VERSION "HNNBNNNYNNNNNNNNNNNNNNNNNNNNNNNNNNNNNNNNNN/4/%%%/4/'%**4NNN///"

NS_ :

BS_:

BU_: ADR_PAG_X2 BAP_Tester GW_App_PAG_PF GW_Routing_PAG_PF Klima_PAG_PF Klimakomp_Dash_PAG_PF Kombi_PAG_PF Miko_PAG_X2 OCU_PAG_PF RDK_High_PAG_PF

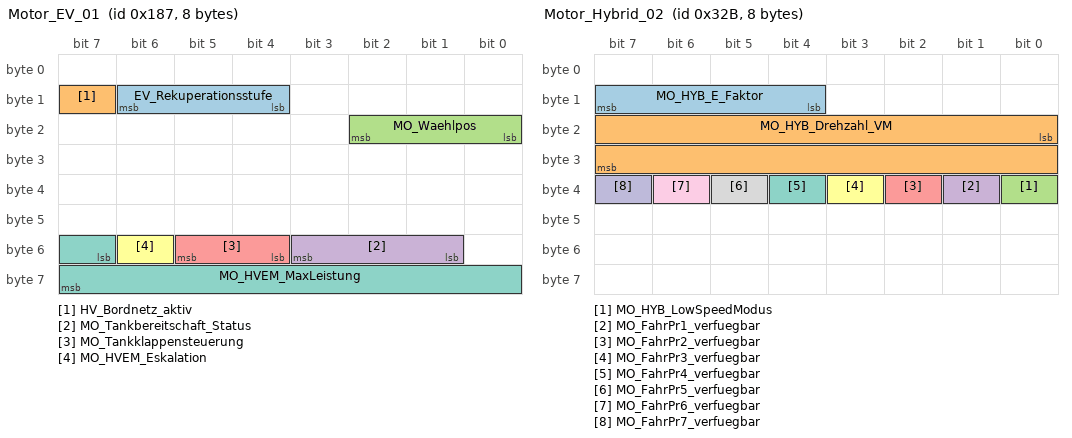
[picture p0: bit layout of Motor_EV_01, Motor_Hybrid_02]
BO_ 391 Motor_EV_01: 8 GW_Routing_PAG_PF
 SG_ EV_Rekuperationsstufe : 12|3@1+ (1,0) [0|7] "" Vector__XXX
 SG_ HV_Bordnetz_aktiv : 15|1@1+ (1,0) [0|1] "" Vector__XXX
 SG_ MO_Waehlpos : 16|3@1+ (1,0) [0|7] "" Vector__XXX
 SG_ MO_Tankbereitschaft_Status : 49|3@1+ (1,0) [0|7] ""  Kombi_PAG_PF
 SG_ MO_Tankklappensteuerung : 52|2@1+ (1,0) [0|3] "" Vector__XXX
 SG_ MO_HVEM_Eskalation : 54|1@1+ (1,0) [0|1] "" Vector__XXX
 SG_ MO_HVEM_MaxLeistung : 55|9@1+ (50,0) [0|25450] "Unit_Watt" Vector__XXX

BO_ 811 Motor_Hybrid_02: 8 GW_Routing_PAG_PF
 SG_ MO_HYB_E_Faktor : 12|4@1+ (1,0) [0|15] "" Vector__XXX
 SG_ MO_HYB_Drehzahl_VM : 16|16@1+ (0.25,0) [0|16256] "Unit_MinutInver" Vector__XXX
 SG_ MO_HYB_LowSpeedModus : 32|1@1+ (1,0) [0|1] "" Vector__XXX
 SG_ MO_FahrPr1_verfuegbar : 33|1@1+ (1,0) [0|1] ""  Klima_PAG_PF
 SG_ MO_FahrPr2_verfuegbar : 34|1@1+ (1,0) [0|1] ""  Klima_PAG_PF
 SG_ MO_FahrPr3_verfuegbar : 35|1@1+ (1,0) [0|1] ""  Klima_PAG_PF
 SG_ MO_FahrPr4_verfuegbar : 36|1@1+ (1,0) [0|1] ""  Klima_PAG_PF
 SG_ MO_FahrPr5_verfuegbar : 37|1@1+ (1,0) [0|1] ""  Klima_PAG_PF
 SG_ MO_FahrPr6_verfuegbar : 38|1@1+ (1,0) [0|1] ""  Klima_PAG_PF
 SG_ MO_FahrPr7_verfuegbar : 39|1@1+ (1,0) [0|1] ""  Klima_PAG_PF

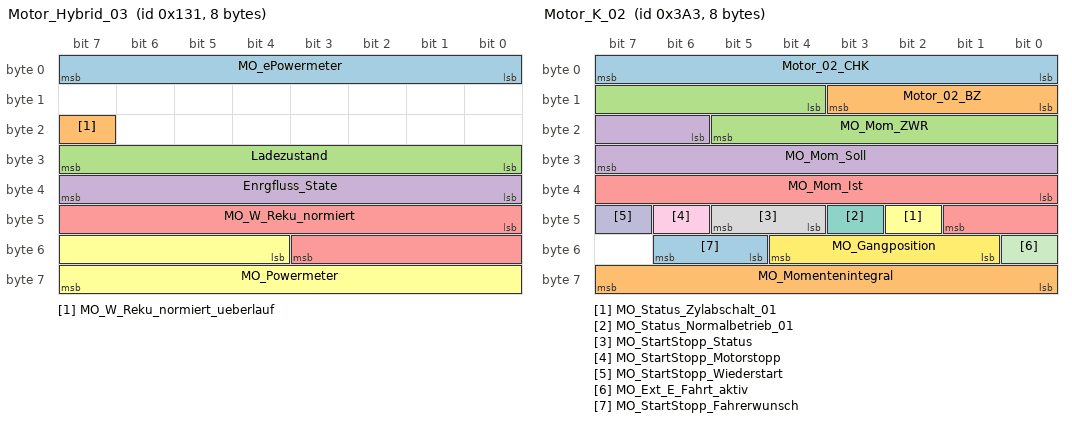
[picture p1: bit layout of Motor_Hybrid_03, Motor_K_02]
BO_ 305 Motor_Hybrid_03: 8 GW_Routing_PAG_PF
 SG_ MO_ePowermeter : 0|8@1+ (0.4,-0.4) [0|100.8] "Unit_PerCent" Vector__XXX
 SG_ MO_W_Reku_normiert_ueberlauf : 23|1@1+ (1,0) [0|1] "" Vector__XXX
 SG_ Ladezustand : 24|8@1+ (1,0) [0|100] "Unit_PerCent"  OCU_PAG_PF
 SG_ Enrgfluss_State : 32|8@1+ (1,0) [0|255] "" Vector__XXX
 SG_ MO_W_Reku_normiert : 40|12@1+ (10,0) [0|40950] "Unit_WattSecond" Vector__XXX
 SG_ MO_Powermeter : 52|12@1+ (1,0) [0|4092] ""  Kombi_PAG_PF

BO_ 931 Motor_K_02: 8 GW_Routing_PAG_PF
 SG_ Motor_02_CHK : 0|8@1+ (1,0) [0|255] "" Vector__XXX
 SG_ Motor_02_BZ : 8|4@1+ (1,0) [0|15] "" Vector__XXX
 SG_ MO_Mom_ZWR : 12|10@1+ (1,0) [0|1021] "" Vector__XXX
 SG_ MO_Mom_Soll : 22|10@1+ (1,0) [0|1021] "" Vector__XXX
 SG_ MO_Mom_Ist : 32|10@1+ (1,0) [0|1021] "" Vector__XXX
 SG_ MO_Status_Zylabschalt_01 : 42|1@1+ (1,0) [0|1] "" Vector__XXX
 SG_ MO_Status_Normalbetrieb_01 : 43|1@1+ (1,0) [0|1] "" Vector__XXX
 SG_ MO_StartStopp_Status : 44|2@1+ (1,0) [0|3] ""  Klima_PAG_PF,Kombi_PAG_PF
 SG_ MO_StartStopp_Motorstopp : 46|1@1+ (1,0) [0|1] ""  ADR_PAG_X2,Klima_PAG_PF,Kombi_PAG_PF
 SG_ MO_StartStopp_Wiederstart : 47|1@1+ (1,0) [0|1] ""  Klima_PAG_PF
 SG_ MO_Ext_E_Fahrt_aktiv : 48|1@1+ (1,0) [0|1] ""  Klima_PAG_PF
 SG_ MO_Gangposition : 49|4@1+ (1,0) [0|15] "" Vector__XXX
 SG_ MO_StartStopp_Fahrerwunsch : 53|2@1+ (1,0) [0|3] "" Vector__XXX
 SG_ MO_Momentenintegral : 56|8@1+ (0.3921,0) [0|99.9855] "" Vector__XXX

BO_ 1747 NMH_CDR_PCM: 7 ADR_PAG_X2
 SG_ NM_CDR_PCM_Start_1 : 0|1@1+ (1,0) [0|1] ""  ADR_PAG_X2,GW_App_PAG_PF,Klima_PAG_PF,Kombi_PAG_PF,Miko_PAG_X2,OCU_PAG_PF,RDK_High_PAG_PF
 SG_ NM_CDR_PCM_Start_2 : 1|1@1+ (1,0) [0|1] "" Vector__XXX
 SG_ NM_CDR_PCM_Normal_Mode_1 : 2|1@1+ (1,0) [0|1] "" Vector__XXX
 SG_ NM_CDR_PCM_Normal_Mode_2 : 3|1@1+ (1,0) [0|1] "" Vector__XXX
 SG_ NM_CDR_PCM_Car_WakeUp : 6|1@1+ (1,0) [0|1] "" Vector__XXX
 SG_ NM_CDR_PCM_Per_WakeUp : 8|5@1+ (1,0) [0|31] "" Vector__XXX
 SG_ NM_CDR_PCM_Fkt_WakeUp : 13|3@1+ (1,0) [0|7] "" Vector__XXX
 SG_ NM_CDR_PCM_Klemme_15 : 16|1@1+ (1,0) [0|1] "" Vector__XXX
 SG_ NM_CDR_PCM_Diagnose : 17|1@1+ (1,0) [0|1] "" Vector__XXX
 SG_ NM_CDR_PCM_MindestAktivZeit : 18|1@1+ (1,0) [0|1] "" Vector__XXX
 SG_ NMH_CDR_PCM_Signalfehler : 32|1@1+ (1,0) [0|1] "" Vector__XXX
 SG_ NM_CDR_PCM_TimeOut_Fehler : 33|1@1+ (1,0) [0|1] "" Vector__XXX
 SG_ NM_CDR_PCM_CAN_Diag_deaktiv : 34|1@1+ (1,0) [0|1] "" Vector__XXX
 SG_ NM_CDR_PCM_KompSchutz : 35|1@1+ (1,0) [0|1] "" Vector__XXX
 SG_ NM_CDR_PCM_Mute_Mode : 36|1@1+ (1,0) [0|1] "" Vector__XXX
 SG_ NM_CDR_PCM_Transport_Mode : 37|1@1+ (1,0) [0|1] "" Vector__XXX
 SG_ NM_CDR_PCM_Abschaltstufe_aktiv : 38|1@1+ (1,0) [0|1] "" Vector__XXX
 SG_ NM_CDR_PCM_Busfehler : 39|1@1+ (1,0) [0|1] "" Vector__XXX
 SG_ NMH_CDR_PCM_Lokalaktiv : 48|1@1+ (1,0) [0|1] "" Vector__XXX
 SG_ NMH_CDR_PCM_Subsystemaktiv : 49|1@1+ (1,0) [0|1] "" Vector__XXX

BO_ 1728 NMH_Gateway: 7 GW_App_PAG_PF
 SG_ NMH_GW_Start_1 : 0|1@1+ (1,0) [0|1] ""  ADR_PAG_X2,GW_App_PAG_PF,Klima_PAG_PF,Kombi_PAG_PF,Miko_PAG_X2,OCU_PAG_PF,RDK_High_PAG_PF
 SG_ NMH_GW_Start_2 : 1|1@1+ (1,0) [0|1] "" Vector__XXX
 SG_ NMH_GW_Normal_Mode_1 : 2|1@1+ (1,0) [0|1] "" Vector__XXX
 SG_ NMH_GW_Normal_Mode_2 : 3|1@1+ (1,0) [0|1] "" Vector__XXX
 SG_ NMH_GW_Car_WakeUp : 6|1@1+ (1,0) [0|1] "" Vector__XXX
 SG_ NMH_GW_Per_WakeUp : 8|5@1+ (1,0) [0|31] "" Vector__XXX
 SG_ NMH_GW_Fkt_WakeUp : 13|3@1+ (1,0) [0|7] "" Vector__XXX
 SG_ NMH_GW_NM_aktiv_Klemme_15 : 16|1@1+ (1,0) [0|1] "" Vector__XXX
 SG_ NMH_GW_NM_aktiv_Diagnose : 17|1@1+ (1,0) [0|1] "" Vector__XXX
 SG_ NMH_GW_NM_aktiv_Start : 18|1@1+ (1,0) [0|1] "" Vector__XXX
 SG_ NMH_GW_NM_aktiv_BDM : 19|1@1+ (1,0) [0|1] "" Vector__XXX
 SG_ NMH_GW_NM_aktiv_Warnblinken : 20|1@1+ (1,0) [0|1] "" Vector__XXX
 SG_ NMH_GW_NM_aktiv_ESP : 21|1@1+ (1,0) [0|1] "" Vector__XXX
 SG_ NMH_GW_NM_aktiv_EMP : 22|1@1+ (1,0) [0|1] "" Vector__XXX
 SG_ NMH_GW_Abschaltstufe_3 : 24|1@1+ (1,0) [0|1] "" Vector__XXX
 SG_ NMH_GW_SG_Fehlerdauer : 25|1@1+ (1,0) [0|1] "" Vector__XXX
 SG_ NMH_GW_STH_Wakeup : 26|1@1+ (1,0) [0|1] "" Vector__XXX
 SG_ NMH_GW_NL_Diagnose : 27|1@1+ (1,0) [0|1] "" Vector__XXX
 SG_ NM_GW_Signalfehler : 32|1@1+ (1,0) [0|1] "" Vector__XXX
 SG_ NMH_GW_TimeOut_Fehler : 33|1@1+ (1,0) [0|1] "" Vector__XXX
 SG_ NMH_GW_CAN_Diag_deaktiv : 34|1@1+ (1,0) [0|1] "" Vector__XXX
 SG_ NMH_GW_KompSchutz : 35|1@1+ (1,0) [0|1] "" Vector__XXX
 SG_ NMH_GW_Mute_Mode : 36|1@1+ (1,0) [0|1] "" Vector__XXX
 SG_ NMH_GW_Transport_Mode : 37|1@1+ (1,0) [0|1] "" Vector__XXX
 SG_ NMH_GW_Abschaltstufe_aktiv : 38|1@1+ (1,0) [0|1] "" Vector__XXX
 SG_ NMH_GW_Eindraht_Fehler : 39|1@1+ (1,0) [0|1] "" Vector__XXX
 SG_ NMH_GW_ACAN : 40|1@1+ (1,0) [0|1] "" Vector__XXX
 SG_ NMH_GW_KombiCAN : 41|1@1+ (1,0) [0|1] "" Vector__XXX
 SG_ NMH_GW_KomfortCAN : 42|1@1+ (1,0) [0|1] "" Vector__XXX
 SG_ NMH_GW_Infotainment : 43|1@1+ (1,0) [0|1] "" Vector__XXX
 SG_ NMH_GW_Fahrwerk : 44|1@1+ (1,0) [0|1] "" Vector__XXX
 SG_ NMH_GW_WakeUp_CAN_Bus : 45|3@1+ (1,0) [0|7] "" Vector__XXX

BO_ 1775 NMH_GSM: 7 OCU_PAG_PF
 SG_ NMH_GSM_Start_1 : 0|1@1+ (1,0) [0|1] ""  ADR_PAG_X2,GW_App_PAG_PF,Klima_PAG_PF,Kombi_PAG_PF,Miko_PAG_X2,OCU_PAG_PF,RDK_High_PAG_PF
 SG_ NMH_GSM_Start_2 : 1|1@1+ (1,0) [0|1] "" Vector__XXX
 SG_ NMH_GSM_Normal_Mode_1 : 2|1@1+ (1,0) [0|1] "" Vector__XXX
 SG_ NMH_GSM_Normal_Mode_2 : 3|1@1+ (1,0) [0|1] "" Vector__XXX
 SG_ NMH_GSM_Car_WakeUp : 6|1@1+ (1,0) [0|1] "" Vector__XXX
 SG_ NMH_GSM_Per_WakeUp : 8|5@1+ (1,0) [0|31] "" Vector__XXX
 SG_ NMH_GSM_Fkt_WakeUp : 13|3@1+ (1,0) [0|7] "" Vector__XXX
 SG_ NMH_GSM_Klemme_15 : 16|1@1+ (1,0) [0|1] "" Vector__XXX
 SG_ NMH_GSM_Diagnose : 17|1@1+ (1,0) [0|1] "" Vector__XXX
 SG_ NMH_GSM_MindestAktivZeit : 18|1@1+ (1,0) [0|1] "" Vector__XXX
 SG_ NMH_GSM_Signalfehler : 32|1@1+ (1,0) [0|1] "" Vector__XXX
 SG_ NMH_GSM_TimeOut_Fehler : 33|1@1+ (1,0) [0|1] "" Vector__XXX
 SG_ NMH_GSM_CAN_Diag_deaktiv : 34|1@1+ (1,0) [0|1] "" Vector__XXX
 SG_ NMH_GSM_KompSchutz : 35|1@1+ (1,0) [0|1] "" Vector__XXX
 SG_ NMH_GSM_Mute_Mode : 36|1@1+ (1,0) [0|1] "" Vector__XXX
 SG_ NMH_GSM_Transport_Mode : 37|1@1+ (1,0) [0|1] "" Vector__XXX
 SG_ NMH_GSM_Abschaltstufe_aktiv : 38|1@1+ (1,0) [0|1] "" Vector__XXX
 SG_ NMH_GSM_Eindraht_Fehler : 39|1@1+ (1,0) [0|1] "" Vector__XXX
 SG_ NMH_GSM_Lokalaktiv : 48|1@1+ (1,0) [0|1] "" Vector__XXX
 SG_ NMH_GSM_Subsystemaktiv : 49|1@1+ (1,0) [0|1] "" Vector__XXX

BO_ 1772 NMH_Klima: 7 Klima_PAG_PF
 SG_ NMH_KL_Start_1 : 0|1@1+ (1,0) [0|1] ""  ADR_PAG_X2,GW_App_PAG_PF,Klima_PAG_PF,Kombi_PAG_PF,Miko_PAG_X2,OCU_PAG_PF,RDK_High_PAG_PF
 SG_ NMH_KL_Start_2 : 1|1@1+ (1,0) [0|1] "" Vector__XXX
 SG_ NMH_KL_Normal_Mode_1 : 2|1@1+ (1,0) [0|1] "" Vector__XXX
 SG_ NMH_KL_Normal_Mode_2 : 3|1@1+ (1,0) [0|1] "" Vector__XXX
 SG_ NM_KL_Car_WakeUp : 6|1@1+ (1,0) [0|1] "" Vector__XXX
 SG_ NM_KL_Per_WakeUp : 8|5@1+ (1,0) [0|31] "" Vector__XXX
 SG_ NM_KL_Fkt_WakeUp : 13|3@1+ (1,0) [0|7] "" Vector__XXX
 SG_ NM_KL_Klemme_15 : 16|1@1+ (1,0) [0|1] "" Vector__XXX
 SG_ NM_KL_Diagnose : 17|1@1+ (1,0) [0|1] "" Vector__XXX
 SG_ NM_KL_MindestAktivZeit : 18|1@1+ (1,0) [0|1] "" Vector__XXX
 SG_ NM_KL_FKT_Nachlauf_Klappen : 19|1@1+ (1,0) [0|1] "" Vector__XXX
 SG_ NM_KL_NL_STH : 24|1@1+ (1,0) [0|1] "" Vector__XXX
 SG_ NM_KL_NL_Restwaerme : 25|1@1+ (1,0) [0|1] "" Vector__XXX
 SG_ NM_KL_NL_LIN : 26|1@1+ (1,0) [0|1] "" Vector__XXX
 SG_ NM_Klima_Signalfehler : 32|1@1+ (1,0) [0|1] "" Vector__XXX
 SG_ NM_KL_TimeOut_Fehler : 33|1@1+ (1,0) [0|1] "" Vector__XXX
 SG_ NM_KL_CAN_Diag_deaktiv : 34|1@1+ (1,0) [0|1] "" Vector__XXX
 SG_ NM_KL_KompSchutz : 35|1@1+ (1,0) [0|1] "" Vector__XXX
 SG_ NM_KL_Mute_Mode : 36|1@1+ (1,0) [0|1] "" Vector__XXX
 SG_ NM_KL_Transport_Mode : 37|1@1+ (1,0) [0|1] "" Vector__XXX
 SG_ NM_KL_Abschaltstufe_aktiv : 38|1@1+ (1,0) [0|1] "" Vector__XXX
 SG_ NM_KL_Eindraht_Fehler : 39|1@1+ (1,0) [0|1] "" Vector__XXX
 SG_ NMH_Klima_Lokalaktiv : 48|1@1+ (1,0) [0|1] "" Vector__XXX
 SG_ NMH_Klima_Subsystemaktiv : 49|1@1+ (1,0) [0|1] "" Vector__XXX

BO_ 1735 NMH_Kombi: 7 Kombi_PAG_PF
 SG_ NMH_KBI_Start_1 : 0|1@1+ (1,0) [0|1] ""  ADR_PAG_X2,GW_App_PAG_PF,Klima_PAG_PF,Kombi_PAG_PF,Miko_PAG_X2,OCU_PAG_PF,RDK_High_PAG_PF
 SG_ NMH_KBI_Start_2 : 1|1@1+ (1,0) [0|1] "" Vector__XXX
 SG_ NMH_KBI_Normal_Mode_1 : 2|1@1+ (1,0) [0|1] "" Vector__XXX
 SG_ NMH_KBI_Normal_Mode_2 : 3|1@1+ (1,0) [0|1] "" Vector__XXX
 SG_ NMH_KBI_Car_WakeUp : 6|1@1+ (1,0) [0|1] "" Vector__XXX
 SG_ NMH_KBI_Per_WakeUp : 8|5@1+ (1,0) [0|31] "" Vector__XXX
 SG_ NMH_KBI_Fkt_WakeUp : 13|3@1+ (1,0) [0|7] "" Vector__XXX
 SG_ NMH_KBI_NM_aktiv_Klemme_15 : 16|1@1+ (1,0) [0|1] "" Vector__XXX
 SG_ NMH_KBI_NM_aktiv_Diagnose : 17|1@1+ (1,0) [0|1] "" Vector__XXX
 SG_ NMH_KBI_NM_aktiv_Start : 18|1@1+ (1,0) [0|1] "" Vector__XXX
 SG_ NMH_KBI_NM_aktiv_Tankinhalt : 19|1@1+ (1,0) [0|1] "" Vector__XXX
 SG_ NMH_KBI_NM_aktiv_Display : 20|1@1+ (1,0) [0|1] "" Vector__XXX
 SG_ NMH_KBI_kein_NL : 24|1@1+ (1,0) [0|1] "" Vector__XXX
 SG_ NMH_KBI_NL_Sync_Funkuhr : 25|1@1+ (1,0) [0|1] "" Vector__XXX
 SG_ NM_Kombi_NL_Warnblinken : 26|1@1+ (1,0) [0|1] "" Vector__XXX
 SG_ NMH_KBI_NL_KL15 : 27|1@1+ (1,0) [0|1] "" Vector__XXX
 SG_ NMH_KBI_Signalfehler : 32|1@1+ (1,0) [0|1] "" Vector__XXX
 SG_ NMH_KBI_TimeOut_Fehler : 33|1@1+ (1,0) [0|1] "" Vector__XXX
 SG_ NMH_KBI_CAN_Diag_deaktiv : 34|1@1+ (1,0) [0|1] "" Vector__XXX
 SG_ NMH_KBI_KompSchutz : 35|1@1+ (1,0) [0|1] "" Vector__XXX
 SG_ NMH_KBI_Mute_Mode : 36|1@1+ (1,0) [0|1] "" Vector__XXX
 SG_ NMH_KBI_Transport_Mode : 37|1@1+ (1,0) [0|1] "" Vector__XXX
 SG_ NMH_KBI_Abschaltstufe_aktiv : 38|1@1+ (1,0) [0|1] "" Vector__XXX
 SG_ NMH_KBI_Eindraht_Fehler : 39|1@1+ (1,0) [0|1] "" Vector__XXX
 SG_ NMH_Kombi_Lokalaktiv : 48|1@1+ (1,0) [0|1] "" Vector__XXX
 SG_ NMH_Kombi_Subsystemaktiv : 49|1@1+ (1,0) [0|1] "" Vector__XXX

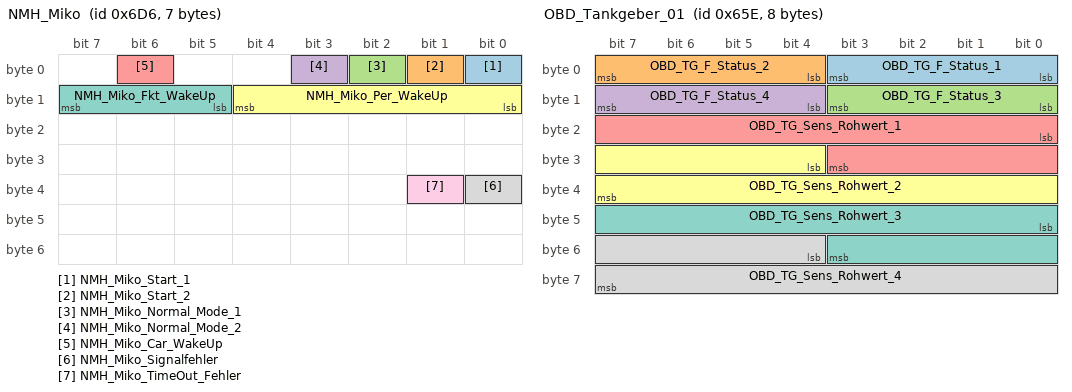
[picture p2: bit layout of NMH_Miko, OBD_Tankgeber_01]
BO_ 1750 NMH_Miko: 7 Miko_PAG_X2
 SG_ NMH_Miko_Start_1 : 0|1@1+ (1,0) [0|1] ""  ADR_PAG_X2,GW_App_PAG_PF,Klima_PAG_PF,Kombi_PAG_PF,Miko_PAG_X2,OCU_PAG_PF,RDK_High_PAG_PF
 SG_ NMH_Miko_Start_2 : 1|1@1+ (1,0) [0|1] "" Vector__XXX
 SG_ NMH_Miko_Normal_Mode_1 : 2|1@1+ (1,0) [0|1] "" Vector__XXX
 SG_ NMH_Miko_Normal_Mode_2 : 3|1@1+ (1,0) [0|1] "" Vector__XXX
 SG_ NMH_Miko_Car_WakeUp : 6|1@1+ (1,0) [0|1] "" Vector__XXX
 SG_ NMH_Miko_Per_WakeUp : 8|5@1+ (1,0) [0|31] "" Vector__XXX
 SG_ NMH_Miko_Fkt_WakeUp : 13|3@1+ (1,0) [0|7] "" Vector__XXX
 SG_ NMH_Miko_Signalfehler : 32|1@1+ (1,0) [0|1] "" Vector__XXX
 SG_ NMH_Miko_TimeOut_Fehler : 33|1@1+ (1,0) [0|1] "" Vector__XXX

BO_ 1774 NMH_RDK: 7 RDK_High_PAG_PF
 SG_ NM_RDK_Start_1 : 0|1@1+ (1,0) [0|1] ""  ADR_PAG_X2,GW_App_PAG_PF,Klima_PAG_PF,Kombi_PAG_PF,Miko_PAG_X2,OCU_PAG_PF,RDK_High_PAG_PF
 SG_ NM_RDK_Start_2 : 1|1@1+ (1,0) [0|1] "" Vector__XXX
 SG_ NM_RDK_Normal_Mode_1 : 2|1@1+ (1,0) [0|1] "" Vector__XXX
 SG_ NM_RDK_Normal_Mode_2 : 3|1@1+ (1,0) [0|1] "" Vector__XXX
 SG_ NM_RDK_Car_WakeUp : 6|1@1+ (1,0) [0|1] "" Vector__XXX
 SG_ NM_RDK_Per_WakeUp : 8|5@1+ (1,0) [0|31] "" Vector__XXX
 SG_ NM_RDK_Fkt_WakeUp : 13|3@1+ (1,0) [0|7] "" Vector__XXX
 SG_ NM_RDK_Klemme_15 : 16|1@1+ (1,0) [0|1] "" Vector__XXX
 SG_ NM_RDK_Diagnose : 17|1@1+ (1,0) [0|1] "" Vector__XXX
 SG_ NM_RDK_MindestAktivZeit : 18|1@1+ (1,0) [0|1] "" Vector__XXX
 SG_ NMH_RDK_NL_Radmanagement : 24|1@1+ (1,0) [0|1] "" Vector__XXX
 SG_ NM_RDK_Signalfehler : 32|1@1+ (1,0) [0|1] "" Vector__XXX
 SG_ NM_RDK_TimeOut_Fehler : 33|1@1+ (1,0) [0|1] "" Vector__XXX
 SG_ NM_RDK_CAN_Diag_deaktiv : 34|1@1+ (1,0) [0|1] "" Vector__XXX
 SG_ NM_RDK_KompSchutz : 35|1@1+ (1,0) [0|1] "" Vector__XXX
 SG_ NM_RDK_Mute_Mode : 36|1@1+ (1,0) [0|1] "" Vector__XXX
 SG_ NM_RDK_Transport_Mode : 37|1@1+ (1,0) [0|1] "" Vector__XXX
 SG_ NM_RDK_Abschaltstufe_aktiv : 38|1@1+ (1,0) [0|1] "" Vector__XXX
 SG_ NM_RDK_Eindraht_Fehler : 39|1@1+ (1,0) [0|1] "" Vector__XXX
 SG_ NMH_RDK_Lokalaktiv : 48|1@1+ (1,0) [0|1] "" Vector__XXX
 SG_ NMH_RDK_Subsystemaktiv : 49|1@1+ (1,0) [0|1] "" Vector__XXX

BO_ 1156 NPM_01_PAG: 8 GW_App_PAG_PF
 SG_ NPM_ForceShutdown : 0|4@1+ (1,0) [0|15] ""  ADR_PAG_X2,Klima_PAG_PF,Kombi_PAG_PF,Miko_PAG_X2,RDK_High_PAG_PF
 SG_ NPM_PreventWakeup : 4|4@1+ (1,0) [0|15] ""  ADR_PAG_X2,Klima_PAG_PF,Kombi_PAG_PF,Miko_PAG_X2,RDK_High_PAG_PF
 SG_ NPM_directAdressing : 8|1@1+ (1,0) [0|1] ""  ADR_PAG_X2,Klima_PAG_PF,Kombi_PAG_PF,Miko_PAG_X2,RDK_High_PAG_PF
 SG_ NPM_FS_VSG : 9|1@1+ (1,0) [0|1] "" Vector__XXX
 SG_ NPM_FS_HAL : 10|1@1+ (1,0) [0|1] "" Vector__XXX
 SG_ NPM_FS_Vorhalt03 : 11|1@1+ (1,0) [0|1] "" Vector__XXX
 SG_ NPM_FS_Vorhalt04 : 12|1@1+ (1,0) [0|1] "" Vector__XXX
 SG_ NPM_FS_EPB : 13|1@1+ (1,0) [0|1] "" Vector__XXX
 SG_ NPM_FS_Niveau : 14|1@1+ (1,0) [0|1] "" Vector__XXX
 SG_ NPM_FS_BCM1 : 15|1@1+ (1,0) [0|1] "" Vector__XXX
 SG_ NPM_FS_BCM2 : 16|1@1+ (1,0) [0|1] "" Vector__XXX
 SG_ NPM_FS_TF : 17|1@1+ (1,0) [0|1] "" Vector__XXX
 SG_ NPM_FS_TB : 18|1@1+ (1,0) [0|1] "" Vector__XXX
 SG_ NPM_FS_Lenkhilfe : 19|1@1+ (1,0) [0|1] "" Vector__XXX
 SG_ NPM_FS_Vorhalt12 : 20|1@1+ (1,0) [0|1] "" Vector__XXX
 SG_ NPM_FS_SF : 21|1@1+ (1,0) [0|1] "" Vector__XXX
 SG_ NPM_FS_SB : 22|1@1+ (1,0) [0|1] "" Vector__XXX
 SG_ NPM_FS_SMLS : 23|1@1+ (1,0) [0|1] "" Vector__XXX
 SG_ NPM_FS_RDK : 24|1@1+ (1,0) [0|1] ""  RDK_High_PAG_PF
 SG_ NPM_FS_AAG : 25|1@1+ (1,0) [0|1] "" Vector__XXX
 SG_ NPM_FS_HDSG : 26|1@1+ (1,0) [0|1] "" Vector__XXX
 SG_ NPM_FS_RFK : 27|1@1+ (1,0) [0|1] "" Vector__XXX
 SG_ NPM_FS_TopView : 28|1@1+ (1,0) [0|1] "" Vector__XXX
 SG_ NPM_FS_Vorhalt21 : 29|1@1+ (1,0) [0|1] "" Vector__XXX
 SG_ NPM_FS_KMB : 30|1@1+ (1,0) [0|1] ""  Kombi_PAG_PF
 SG_ NPM_FS_Miko : 31|1@1+ (1,0) [0|1] ""  Miko_PAG_X2
 SG_ NPM_FS_SU : 32|1@1+ (1,0) [0|1] "" Vector__XXX
 SG_ NPM_FS_HU : 33|1@1+ (1,0) [0|1] ""  ADR_PAG_X2
 SG_ NPM_FS_BKE : 34|1@1+ (1,0) [0|1] ""  Klima_PAG_PF
 SG_ NPM_FS_Vorhalt27 : 35|1@1+ (1,0) [0|1] "" Vector__XXX
 SG_ NPM_PrWu_VSG : 36|1@1+ (1,0) [0|1] "" Vector__XXX
 SG_ NPM_PrWu_HAL : 37|1@1+ (1,0) [0|1] "" Vector__XXX
 SG_ NPM_PrWu_Vorhalt03 : 38|1@1+ (1,0) [0|1] "" Vector__XXX
 SG_ NPM_PrWu_Vorhalt04 : 39|1@1+ (1,0) [0|1] "" Vector__XXX
 SG_ NPM_PrWu_EPB : 40|1@1+ (1,0) [0|1] "" Vector__XXX
 SG_ NPM_PrWu_Niveau : 41|1@1+ (1,0) [0|1] "" Vector__XXX
 SG_ NPM_PrWu_BCM1 : 42|1@1+ (1,0) [0|1] "" Vector__XXX
 SG_ NPM_PrWu_BCM2 : 43|1@1+ (1,0) [0|1] "" Vector__XXX
 SG_ NPM_PrWu_TF : 44|1@1+ (1,0) [0|1] "" Vector__XXX
 SG_ NPM_PrWu_TB : 45|1@1+ (1,0) [0|1] "" Vector__XXX
 SG_ NPM_PrWu_Lenkhilfe : 46|1@1+ (1,0) [0|1] "" Vector__XXX
 SG_ NPM_PrWu_SF : 48|1@1+ (1,0) [0|1] "" Vector__XXX
 SG_ NPM_PrWu_SB : 49|1@1+ (1,0) [0|1] "" Vector__XXX
 SG_ NPM_PrWu_SMLS : 50|1@1+ (1,0) [0|1] "" Vector__XXX
 SG_ NPM_PrWu_RDK : 51|1@1+ (1,0) [0|1] ""  RDK_High_PAG_PF
 SG_ NPM_PrWu_AAG : 52|1@1+ (1,0) [0|1] "" Vector__XXX
 SG_ NPM_PrWu_HDSG : 53|1@1+ (1,0) [0|1] "" Vector__XXX
 SG_ NPM_PrWu_RFK : 54|1@1+ (1,0) [0|1] "" Vector__XXX
 SG_ NPM_PrWu_TopView : 55|1@1+ (1,0) [0|1] "" Vector__XXX
 SG_ NPM_PrWu_Vorhalt21 : 56|1@1+ (1,0) [0|1] "" Vector__XXX
 SG_ NPM_PrWu_KMB : 57|1@1+ (1,0) [0|1] ""  Kombi_PAG_PF
 SG_ NPM_PrWu_Miko : 58|1@1+ (1,0) [0|1] ""  Miko_PAG_X2
 SG_ NPM_PrWu_SU : 59|1@1+ (1,0) [0|1] "" Vector__XXX
 SG_ NPM_PrWu_HU : 60|1@1+ (1,0) [0|1] ""  ADR_PAG_X2
 SG_ NPM_PrWu_BKE : 61|1@1+ (1,0) [0|1] ""  Klima_PAG_PF
 SG_ NPM_PrWu_Vorhalt27 : 62|1@1+ (1,0) [0|1] "" Vector__XXX

BO_ 1630 OBD_Tankgeber_01: 8 Kombi_PAG_PF
 SG_ OBD_TG_F_Status_1 : 0|4@1+ (1,0) [0|15] "" Vector__XXX
 SG_ OBD_TG_F_Status_2 : 4|4@1+ (1,0) [0|15] "" Vector__XXX
 SG_ OBD_TG_F_Status_3 : 8|4@1+ (1,0) [0|15] "" Vector__XXX
 SG_ OBD_TG_F_Status_4 : 12|4@1+ (1,0) [0|15] "" Vector__XXX
 SG_ OBD_TG_Sens_Rohwert_1 : 16|12@1+ (0.5,0) [0|2047.5] "Unit_Ohm" Vector__XXX
 SG_ OBD_TG_Sens_Rohwert_2 : 28|12@1+ (0.5,0) [0|2047.5] "Unit_Ohm" Vector__XXX
 SG_ OBD_TG_Sens_Rohwert_3 : 40|12@1+ (0.5,0) [0|2047.5] "Unit_Ohm" Vector__XXX
 SG_ OBD_TG_Sens_Rohwert_4 : 52|12@1+ (0.5,0) [0|2047.5] "Unit_Ohm" Vector__XXX

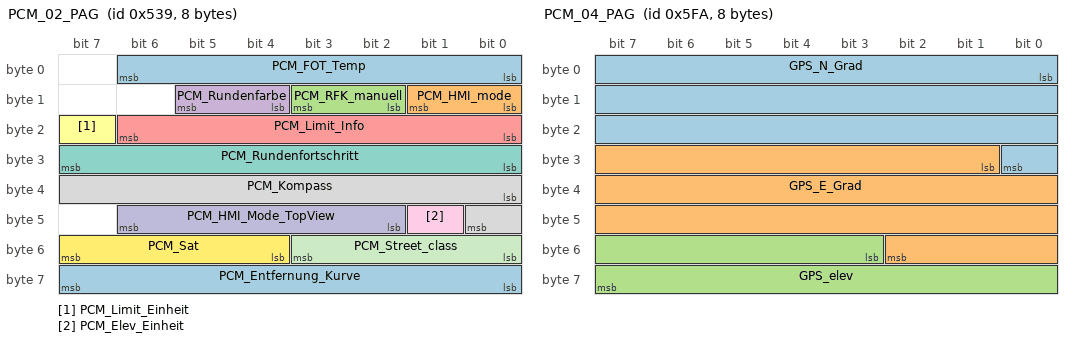
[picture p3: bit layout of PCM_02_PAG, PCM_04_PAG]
BO_ 1337 PCM_02_PAG: 8 ADR_PAG_X2
 SG_ PCM_FOT_Temp : 0|7@1+ (1,-10) [-10|116] "Unit_DegreCelsi" Vector__XXX
 SG_ PCM_HMI_mode : 8|2@1+ (1,0) [0|3] ""  GW_Routing_PAG_PF
 SG_ PCM_RFK_manuell : 10|2@1+ (1,0) [0|3] ""  GW_Routing_PAG_PF
 SG_ PCM_Rundenfarbe : 12|2@1+ (1,0) [0|3] "" Vector__XXX
 SG_ PCM_Limit_Info : 16|7@1+ (5,0) [0|200] ""  Kombi_PAG_PF
 SG_ PCM_Limit_Einheit : 23|1@1+ (1,0) [0|1] "" Vector__XXX
 SG_ PCM_Rundenfortschritt : 24|8@1+ (1.5,0) [0|240] "" Vector__XXX
 SG_ PCM_Kompass : 32|9@1+ (1,0) [0|359] "Unit_DegreCelsi"  Kombi_PAG_PF
 SG_ PCM_Elev_Einheit : 41|1@1+ (1,0) [0|1] ""  GW_Routing_PAG_PF,Kombi_PAG_PF,OCU_PAG_PF
 SG_ PCM_HMI_Mode_TopView : 42|5@1+ (1,0) [0|31] "" Vector__XXX
 SG_ PCM_Street_class : 48|4@1+ (1,0) [0|15] "" Vector__XXX
 SG_ PCM_Sat : 52|4@1+ (1,0) [0|15] "" Vector__XXX
 SG_ PCM_Entfernung_Kurve : 56|8@1+ (10,0) [10|2540] "Unit_Meter"  Kombi_PAG_PF

BO_ 1530 PCM_04_PAG: 8 ADR_PAG_X2
 SG_ GPS_N_Grad : 0|25@1+ (1E-005,-90) [-90|90] ""  GW_Routing_PAG_PF,OCU_PAG_PF
 SG_ GPS_E_Grad : 25|26@1+ (1E-005,-180) [-180|180] ""  GW_Routing_PAG_PF,OCU_PAG_PF
 SG_ GPS_elev : 51|13@1+ (1,-1000) [-1000|7191] ""  GW_Routing_PAG_PF,OCU_PAG_PF

BO_ 1707 PCM_CDR_01_PAG: 8 ADR_PAG_X2
 SG_ PCM_Std : 0|5@1+ (1,0) [0|23] "Unit_Hours"  Kombi_PAG_PF
 SG_ PCM_Min : 5|6@1+ (1,0) [0|59] "Unit_Minut"  Kombi_PAG_PF
 SG_ PCM_Sek : 11|6@1+ (1,0) [0|59] "Unit_Secon"  Kombi_PAG_PF
 SG_ PCM_Zeitzone : 17|5@1+ (0.5,0) [0.5|15] "Unit_Hours"  Kombi_PAG_PF
 SG_ PCM_Zeitzone_Vorzeichen : 22|1@1+ (1,0) [0|1] ""  Kombi_PAG_PF
 SG_ PCM_Uebern : 23|1@1+ (1,0) [0|1] ""  Kombi_PAG_PF
 SG_ PCM_Tag : 24|5@1+ (1,0) [1|31] "Unit_Day"  Kombi_PAG_PF
 SG_ PCM_Mon : 29|4@1+ (1,0) [1|12] "Unit_Month"  Kombi_PAG_PF
 SG_ PCM_JJ : 33|7@1+ (1,0) [0|99] "Unit_Year"  Kombi_PAG_PF
 SG_ PCM_Sommerzeit : 40|1@1+ (1,0) [0|1] ""  Kombi_PAG_PF
 SG_ PCM_Reset_Trip_1 : 41|1@1+ (1,0) [0|1] ""  Kombi_PAG_PF
 SG_ PCM_Reset_Trip_2 : 42|1@1+ (1,0) [0|1] ""  Kombi_PAG_PF
 SG_ HU_Fotosensor : 48|9@1+ (0.25,0) [0|100] "Unit_PerCent"  GW_Routing_PAG_PF,Klima_PAG_PF,Kombi_PAG_PF,Miko_PAG_X2
 SG_ HU_SVB_AMP : 57|1@1+ (1,0) [0|1] "" Vector__XXX
 SG_ PCM_SVB_TV : 58|1@1+ (1,0) [0|1] "" Vector__XXX
 SG_ PCM_KD_Fehler_AMP : 59|1@1+ (1,0) [0|1] "" Vector__XXX
 SG_ PCM_KD_Fehler_TV : 60|1@1+ (1,0) [0|1] "" Vector__XXX
 SG_ HU_PCMCDR : 61|1@1+ (1,0) [0|1] ""  GW_App_PAG_PF
 SG_ HU_Topview_on_Anf : 62|1@1+ (1,0) [0|1] "" Vector__XXX
 SG_ HU_KD_Fehler : 63|1@1+ (1,0) [0|1] ""  GW_App_PAG_PF

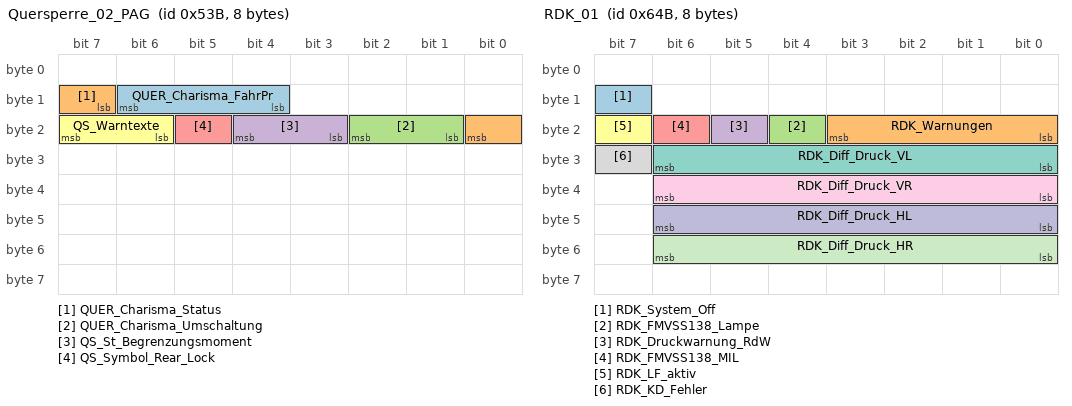
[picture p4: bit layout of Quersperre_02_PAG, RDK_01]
BO_ 1339 Quersperre_02_PAG: 8 GW_Routing_PAG_PF
 SG_ QUER_Charisma_FahrPr : 12|3@1+ (1,0) [0|7] "" Vector__XXX
 SG_ QUER_Charisma_Status : 15|2@1+ (1,0) [0|3] "" Vector__XXX
 SG_ QUER_Charisma_Umschaltung : 17|2@1+ (1,0) [0|3] "" Vector__XXX
 SG_ QS_St_Begrenzungsmoment : 19|2@1+ (1,0) [0|3] "" Vector__XXX
 SG_ QS_Symbol_Rear_Lock : 21|1@1+ (1,0) [0|1] "" Vector__XXX
 SG_ QS_Warntexte : 22|2@1+ (1,0) [0|3] ""  Kombi_PAG_PF

BO_ 1611 RDK_01: 8 RDK_High_PAG_PF
 SG_ RDK_System_Off : 15|1@1+ (1,0) [0|1] ""  GW_Routing_PAG_PF
 SG_ RDK_Warnungen : 16|4@1+ (1,0) [0|15] ""  GW_Routing_PAG_PF
 SG_ RDK_FMVSS138_Lampe : 20|1@1+ (1,0) [0|1] ""  GW_Routing_PAG_PF
 SG_ RDK_Druckwarnung_RdW : 21|1@1+ (1,0) [0|1] ""  GW_Routing_PAG_PF
 SG_ RDK_FMVSS138_MIL : 22|1@1+ (1,0) [0|1] ""  GW_Routing_PAG_PF
 SG_ RDK_LF_aktiv : 23|1@1+ (1,0) [0|1] ""  GW_Routing_PAG_PF
 SG_ RDK_Diff_Druck_VL : 24|7@1+ (0.1,-6.3) [-6.3|6.3] "Unit_Bar"  GW_Routing_PAG_PF,Kombi_PAG_PF
 SG_ RDK_KD_Fehler : 31|1@1+ (1,0) [0|1] ""  GW_App_PAG_PF,GW_Routing_PAG_PF
 SG_ RDK_Diff_Druck_VR : 32|7@1+ (0.1,-6.3) [-6.3|6.3] "Unit_Bar"  GW_Routing_PAG_PF,Kombi_PAG_PF
 SG_ RDK_Diff_Druck_HL : 40|7@1+ (0.1,-6.3) [-6.3|6.3] "Unit_Bar"  GW_Routing_PAG_PF,Kombi_PAG_PF
 SG_ RDK_Diff_Druck_HR : 48|7@1+ (0.1,-6.3) [-6.3|6.3] "Unit_Bar"  GW_Routing_PAG_PF,Kombi_PAG_PF

BO_ 1652 RDK_02_PAG: 8 RDK_High_PAG_PF
 SG_ RDK_W_1_Reifen_VL : 0|1@1+ (1,0) [0|1] ""  Kombi_PAG_PF
 SG_ RDK_W_2_Reifen_VL : 1|1@1+ (1,0) [0|1] ""  Kombi_PAG_PF
 SG_ RDK_W_1_Reifen_VR : 2|1@1+ (1,0) [0|1] ""  Kombi_PAG_PF
 SG_ RDK_W_2_Reifen_VR : 3|1@1+ (1,0) [0|1] ""  Kombi_PAG_PF
 SG_ RDK_W_1_Reifen_HL : 4|1@1+ (1,0) [0|1] ""  Kombi_PAG_PF
 SG_ RDK_W_2_Reifen_HL : 5|1@1+ (1,0) [0|1] ""  Kombi_PAG_PF
 SG_ RDK_W_1_Reifen_HR : 6|1@1+ (1,0) [0|1] ""  Kombi_PAG_PF
 SG_ RDK_W_2_Reifen_HR : 7|1@1+ (1,0) [0|1] ""  Kombi_PAG_PF
 SG_ RDK_Warnung_1 : 8|1@1+ (1,0) [0|1] "" Vector__XXX
 SG_ RDK_Warnung_2 : 9|1@1+ (1,0) [0|1] "" Vector__XXX
 SG_ RDK_angelernt : 10|1@1+ (1,0) [0|1] ""  ADR_PAG_X2
 SG_ RDK_Solldr_uebern : 12|1@1+ (1,0) [0|1] ""  Kombi_PAG_PF
 SG_ RDK_Text_1 : 16|1@1+ (1,0) [0|1] ""  Kombi_PAG_PF
 SG_ RDK_Text_2 : 17|1@1+ (1,0) [0|1] ""  Kombi_PAG_PF
 SG_ RDK_Text_3 : 18|1@1+ (1,0) [0|1] ""  Kombi_PAG_PF
 SG_ RDK_Text_4 : 19|1@1+ (1,0) [0|1] ""  Kombi_PAG_PF
 SG_ RDK_Text_5 : 20|1@1+ (1,0) [0|1] ""  Kombi_PAG_PF
 SG_ RDK_Text_6 : 21|1@1+ (1,0) [0|1] ""  Kombi_PAG_PF
 SG_ RDK_W_3_Reifendr_erh : 23|1@1+ (1,0) [0|1] ""  Kombi_PAG_PF

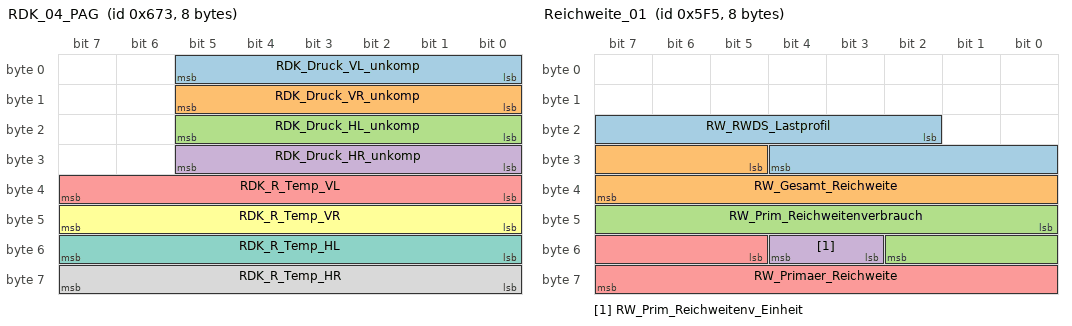
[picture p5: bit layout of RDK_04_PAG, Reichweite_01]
BO_ 1651 RDK_04_PAG: 8 RDK_High_PAG_PF
 SG_ RDK_Druck_VL_unkomp : 0|6@1+ (0.1,0) [0|6.2] "Unit_Bar"  Kombi_PAG_PF
 SG_ RDK_Druck_VR_unkomp : 8|6@1+ (0.1,0) [0|6.2] "Unit_Bar"  Kombi_PAG_PF
 SG_ RDK_Druck_HL_unkomp : 16|6@1+ (0.1,0) [0|6.2] "Unit_Bar"  Kombi_PAG_PF
 SG_ RDK_Druck_HR_unkomp : 24|6@1+ (0.1,0) [0|6.2] "Unit_Bar"  Kombi_PAG_PF
 SG_ RDK_R_Temp_VL : 32|8@1+ (1,-60) [-60|194] "Unit_DegreCelsi" Vector__XXX
 SG_ RDK_R_Temp_VR : 40|8@1+ (1,-60) [-60|194] "Unit_DegreCelsi" Vector__XXX
 SG_ RDK_R_Temp_HL : 48|8@1+ (1,-60) [-60|194] "Unit_DegreCelsi" Vector__XXX
 SG_ RDK_R_Temp_HR : 56|8@1+ (1,-60) [-60|194] "Unit_DegreCelsi" Vector__XXX

BO_ 1525 Reichweite_01: 8 GW_Routing_PAG_PF
 SG_ RW_RWDS_Lastprofil : 18|11@1+ (1,0) [0|2045] "Unit_Amper" Vector__XXX
 SG_ RW_Gesamt_Reichweite : 29|11@1+ (1,0) [0|2044] "Unit_KiloMeter"  Kombi_PAG_PF
 SG_ RW_Prim_Reichweitenverbrauch : 40|11@1+ (0.1,0) [0|204.4] "" Vector__XXX
 SG_ RW_Prim_Reichweitenv_Einheit : 51|2@1+ (1,0) [0|3] "" Vector__XXX
 SG_ RW_Primaer_Reichweite : 53|11@1+ (1,0) [0|2044] "Unit_KiloMeter" Vector__XXX

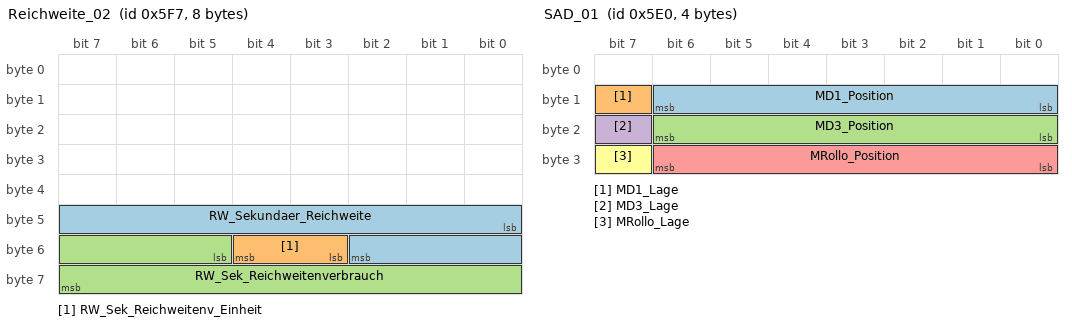
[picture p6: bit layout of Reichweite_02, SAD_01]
BO_ 1527 Reichweite_02: 8 GW_Routing_PAG_PF
 SG_ RW_Sekundaer_Reichweite : 40|11@1+ (1,0) [0|2044] "Unit_KiloMeter"  Kombi_PAG_PF
 SG_ RW_Sek_Reichweitenv_Einheit : 51|2@1+ (1,0) [0|3] "" Vector__XXX
 SG_ RW_Sek_Reichweitenverbrauch : 53|11@1+ (0.1,0) [0|204.4] "" Vector__XXX

BO_ 1504 SAD_01: 4 GW_Routing_PAG_PF
 SG_ MD1_Position : 8|7@1+ (1,0) [0|100] "Unit_PerCent"  Klima_PAG_PF
 SG_ MD1_Lage : 15|1@1+ (1,0) [0|1] ""  Klima_PAG_PF
 SG_ MD3_Position : 16|7@1+ (1,0) [0|100] "Unit_PerCent"  Klima_PAG_PF
 SG_ MD3_Lage : 23|1@1+ (1,0) [0|1] "" Vector__XXX
 SG_ MRollo_Position : 24|7@1+ (1,0) [0|100] "Unit_PerCent" Vector__XXX
 SG_ MRollo_Lage : 31|1@1+ (1,0) [0|1] "" Vector__XXX

BO_ 1413 Systeminfo_01: 8 GW_App_PAG_PF
 SG_ SI_Int_CAN_gespiegelt : 0|1@1+ (1,0) [0|1] "" Vector__XXX
 SG_ SI_CAN_Komfort_Sleep : 1|1@1+ (1,0) [0|1] ""  ADR_PAG_X2,Kombi_PAG_PF
 SG_ SI_CAN_Dashboard_Sleep : 2|1@1+ (1,0) [0|1] ""  ADR_PAG_X2
 SG_ SI_CAN_Antrieb_Sleep : 3|1@1+ (1,0) [0|1] ""  ADR_PAG_X2
 SG_ SI_Infotainment_Sleep : 4|1@1+ (1,0) [0|1] "" Vector__XXX
 SG_ SI_CAN_Extended_Sleep : 5|1@1+ (1,0) [0|1] ""  ADR_PAG_X2,Kombi_PAG_PF
 SG_ SI_Fahrwerk_Sleep : 6|1@1+ (1,0) [0|1] ""  ADR_PAG_X2
 SG_ SI_Diagnose_Aktiv : 7|1@1+ (1,0) [0|1] "" Vector__XXX
 SG_ SI_QRS_Mode : 8|1@1+ (1,0) [0|1] ""  OCU_PAG_PF,RDK_High_PAG_PF
 SG_ SI_T_Mode : 9|1@1+ (1,0) [0|1] ""  ADR_PAG_X2,Klima_PAG_PF,Kombi_PAG_PF,OCU_PAG_PF,RDK_High_PAG_PF
 SG_ SI_NWDF : 10|1@1+ (1,0) [0|1] ""  ADR_PAG_X2,Klima_PAG_PF,Kombi_PAG_PF,Miko_PAG_X2,OCU_PAG_PF,RDK_High_PAG_PF
 SG_ SI_NWDF_gueltig : 11|1@1+ (1,0) [0|1] ""  ADR_PAG_X2,Klima_PAG_PF,Kombi_PAG_PF,Miko_PAG_X2,OCU_PAG_PF,RDK_High_PAG_PF
 SG_ SI_Sammelfehler : 12|1@1+ (1,0) [0|1] "" Vector__XXX
 SG_ GW_KD_Fehler : 13|1@1+ (1,0) [0|1] "" Vector__XXX
 SG_ SI_T_Schutz : 14|1@1+ (1,0) [0|1] "" Vector__XXX
 SG_ SI_MOST_Status : 15|1@1+ (1,0) [0|1] "" Vector__XXX
 SG_ SI_Sammel_SG_Fehler : 56|6@1+ (1,0) [0|60] "" Vector__XXX
 SG_ SI_MO_WU : 63|1@1+ (1,0) [0|1] "" Vector__XXX

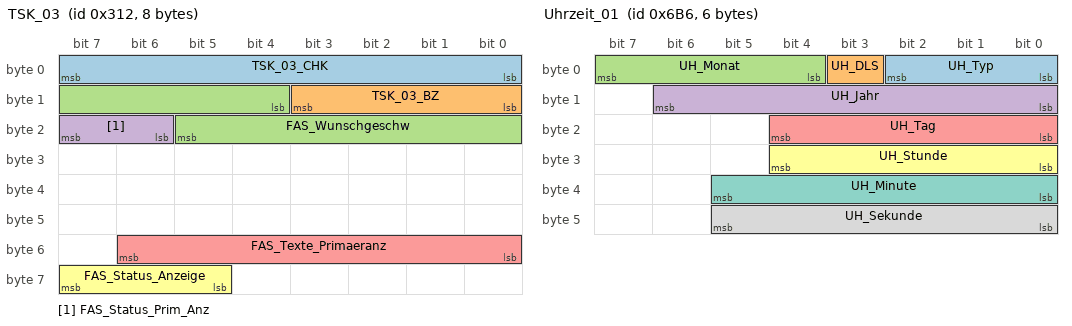
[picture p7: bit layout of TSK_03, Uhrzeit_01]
BO_ 786 TSK_03: 8 GW_Routing_PAG_PF
 SG_ TSK_03_CHK : 0|8@1+ (1,0) [0|255] ""  Kombi_PAG_PF
 SG_ TSK_03_BZ : 8|4@1+ (1,0) [0|15] ""  Kombi_PAG_PF
 SG_ FAS_Wunschgeschw : 12|10@1+ (0.32,0) [0|326.72] "Unit_KiloMeterPerHour"  Kombi_PAG_PF
 SG_ FAS_Status_Prim_Anz : 22|2@1+ (1,0) [0|3] "" Vector__XXX
 SG_ FAS_Texte_Primaeranz : 48|7@1+ (1,0) [0|127] ""  Kombi_PAG_PF
 SG_ FAS_Status_Anzeige : 61|3@1+ (1,0) [0|7] ""  Kombi_PAG_PF

BO_ 1718 Uhrzeit_01: 6 Kombi_PAG_PF
 SG_ UH_Typ : 0|3@1+ (1,0) [0|7] "" Vector__XXX
 SG_ UH_DLS : 3|1@1+ (1,0) [0|1] "" Vector__XXX
 SG_ UH_Monat : 4|4@1+ (1,0) [1|12] "Unit_Month"  GW_App_PAG_PF
 SG_ UH_Jahr : 8|7@1+ (1,2000) [2000|2127] "Unit_Year"  GW_App_PAG_PF
 SG_ UH_Tag : 16|5@1+ (1,0) [1|31] "Unit_Day"  GW_App_PAG_PF
 SG_ UH_Stunde : 24|5@1+ (1,0) [0|23] "Unit_Hours"  GW_App_PAG_PF
 SG_ UH_Minute : 32|6@1+ (1,0) [0|59] "Unit_Minut"  GW_App_PAG_PF
 SG_ UH_Sekunde : 40|6@1+ (1,0) [0|59] "Unit_Secon"  GW_App_PAG_PF

BO_ 1716 VIN_01: 8 GW_Routing_PAG_PF
 SG_ VIN_01_MUX M : 0|2@1+ (1,0) [0|3] ""  ADR_PAG_X2,Klima_PAG_PF,OCU_PAG_PF
 SG_ KS_Geheimnis_1 m0 : 8|8@1+ (1,0) [0|255] "" Vector__XXX
 SG_ VIN_4 m1 : 8|8@1+ (1,0) [0|255] ""  ADR_PAG_X2,Klima_PAG_PF,OCU_PAG_PF
 SG_ VIN_11 m2 : 8|8@1+ (1,0) [0|255] ""  ADR_PAG_X2,Klima_PAG_PF,OCU_PAG_PF
 SG_ KS_Geheimnis_2 m0 : 16|8@1+ (1,0) [0|255] "" Vector__XXX
 SG_ VIN_5 m1 : 16|8@1+ (1,0) [0|255] ""  ADR_PAG_X2,Klima_PAG_PF,OCU_PAG_PF
 SG_ VIN_12 m2 : 16|8@1+ (1,0) [0|255] ""  ADR_PAG_X2,Klima_PAG_PF,OCU_PAG_PF
 SG_ KS_Geheimnis_3 m0 : 24|8@1+ (1,0) [0|255] "" Vector__XXX
 SG_ VIN_6 m1 : 24|8@1+ (1,0) [0|255] ""  ADR_PAG_X2,Klima_PAG_PF,OCU_PAG_PF
 SG_ VIN_13 m2 : 24|8@1+ (1,0) [0|255] ""  ADR_PAG_X2,Klima_PAG_PF,OCU_PAG_PF
 SG_ KS_Geheimnis_4 m0 : 32|8@1+ (1,0) [0|255] "" Vector__XXX
 SG_ VIN_7 m1 : 32|8@1+ (1,0) [0|255] ""  ADR_PAG_X2,Klima_PAG_PF,OCU_PAG_PF
 SG_ VIN_14 m2 : 32|8@1+ (1,0) [0|255] ""  ADR_PAG_X2,Klima_PAG_PF,OCU_PAG_PF
 SG_ VIN_1 m0 : 40|8@1+ (1,0) [0|255] ""  ADR_PAG_X2,Klima_PAG_PF,OCU_PAG_PF
 SG_ VIN_8 m1 : 40|8@1+ (1,0) [0|255] ""  ADR_PAG_X2,Klima_PAG_PF,OCU_PAG_PF
 SG_ VIN_15 m2 : 40|8@1+ (1,0) [0|255] ""  ADR_PAG_X2,Klima_PAG_PF,OCU_PAG_PF
 SG_ VIN_2 m0 : 48|8@1+ (1,0) [0|255] ""  ADR_PAG_X2,Klima_PAG_PF,OCU_PAG_PF
 SG_ VIN_9 m1 : 48|8@1+ (1,0) [0|255] ""  ADR_PAG_X2,Klima_PAG_PF,OCU_PAG_PF
 SG_ VIN_16 m2 : 48|8@1+ (1,0) [0|255] ""  ADR_PAG_X2,Klima_PAG_PF,OCU_PAG_PF
 SG_ VIN_3 m0 : 56|8@1+ (1,0) [0|255] ""  ADR_PAG_X2,Klima_PAG_PF,OCU_PAG_PF
 SG_ VIN_10 m1 : 56|8@1+ (1,0) [0|255] ""  ADR_PAG_X2,Klima_PAG_PF,OCU_PAG_PF
 SG_ VIN_17 m2 : 56|8@1+ (1,0) [0|255] ""  ADR_PAG_X2,Klima_PAG_PF,OCU_PAG_PF

BO_ 915 WBA_02: 8 GW_Routing_PAG_PF
 SG_ WBA_02_CHK : 0|8@1+ (1,0) [0|255] ""  Kombi_PAG_PF
 SG_ WBA_02_BZ : 8|4@1+ (1,0) [0|15] ""  Kombi_PAG_PF
 SG_ WBA_Senderkennung M : 12|1@1+ (1,0) [0|1] ""  Kombi_PAG_PF
 SG_ WBA_Lampe_Shift_Lock m0 : 13|1@1+ (1,0) [0|1] "" Vector__XXX
 SG_ WBA_Schaltempf_verfbar m1 : 13|1@1+ (1,0) [0|1] "" Vector__XXX
 SG_ WBA_Effizienzmodus : 14|1@1+ (1,0) [0|1] "" Vector__XXX
 SG_ WBA_Blinken m0 : 16|1@1+ (1,0) [0|1] ""  Kombi_PAG_PF
 SG_ WBA_Getriebevariante m0 : 17|4@1+ (1,0) [0|15] "" Vector__XXX
 SG_ WBA_GE_Warnung : 21|3@1+ (1,0) [0|7] ""  Kombi_PAG_PF
 SG_ WBA_Fahrstufe m0 : 24|4@1+ (1,0) [0|15] ""  Kombi_PAG_PF
 SG_ WBA_Istgang m1 : 24|4@1+ (1,0) [0|15] "" Vector__XXX
 SG_ WBA_eing_Gang m0 : 28|4@1+ (1,0) [0|15] ""  Kombi_PAG_PF
 SG_ WBA_Sollgang m1 : 28|4@1+ (1,0) [0|15] "" Vector__XXX
 SG_ WBA_GE_Texte m0 : 32|3@1+ (1,0) [0|7] ""  Kombi_PAG_PF
 SG_ WBA_Schaltschema_Aktiv m0 : 35|1@1+ (1,0) [0|1] "" Vector__XXX
 SG_ WH_Warnung m0 : 36|3@1+ (1,0) [0|7] "" Vector__XXX
 SG_ WBA_GE_Zusatzwarnungen m0 : 39|3@1+ (1,0) [0|7] "" Vector__XXX
 SG_ GE_Tipschaltempf_verfuegbar m0 : 43|1@1+ (1,0) [0|1] "" Vector__XXX
 SG_ GE_Sollgang m0 : 44|4@1+ (1,0) [0|15] "" Vector__XXX

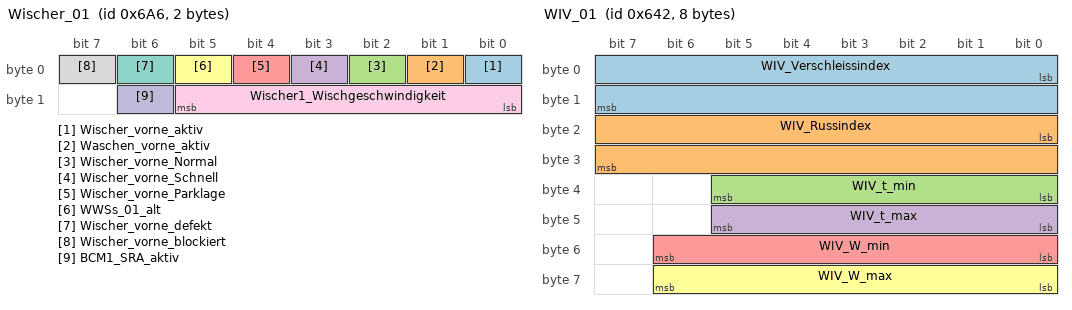
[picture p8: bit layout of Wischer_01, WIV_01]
BO_ 1702 Wischer_01: 2 GW_Routing_PAG_PF
 SG_ Wischer_vorne_aktiv : 0|1@1+ (1,0) [0|1] ""  Klima_PAG_PF
 SG_ Waschen_vorne_aktiv : 1|1@1+ (1,0) [0|1] ""  Klima_PAG_PF
 SG_ Wischer_vorne_Normal : 2|1@1+ (1,0) [0|1] ""  Klima_PAG_PF
 SG_ Wischer_vorne_Schnell : 3|1@1+ (1,0) [0|1] ""  Klima_PAG_PF
 SG_ Wischer_vorne_Parklage : 4|1@1+ (1,0) [0|1] "" Vector__XXX
 SG_ WWSs_01_alt : 5|1@1+ (1,0) [0|1] "" Vector__XXX
 SG_ Wischer_vorne_defekt : 6|1@1+ (1,0) [0|1] ""  Kombi_PAG_PF
 SG_ Wischer_vorne_blockiert : 7|1@1+ (1,0) [0|1] "" Vector__XXX
 SG_ Wischer1_Wischgeschwindigkeit : 8|6@1+ (1,9) [10|70] "Unit_MinutInver" Vector__XXX
 SG_ BCM1_SRA_aktiv : 14|1@1+ (1,0) [0|1] "" Vector__XXX

BO_ 1602 WIV_01: 8 GW_Routing_PAG_PF
 SG_ WIV_Verschleissindex : 0|16@1+ (2E-008,0) [0|0.00131068] ""  Kombi_PAG_PF
 SG_ WIV_Russindex : 16|16@1+ (2E-008,0) [0|0.00131068] ""  Kombi_PAG_PF
 SG_ WIV_t_min : 32|6@1+ (1,0) [0|63] "Unit_Month"  Kombi_PAG_PF
 SG_ WIV_t_max : 40|6@1+ (1,0) [0|63] "Unit_Month"  Kombi_PAG_PF
 SG_ WIV_W_min : 48|7@1+ (1000,0) [0|127000] "Unit_KiloMeter"  Kombi_PAG_PF
 SG_ WIV_W_max : 56|7@1+ (1000,0) [0|127000] "Unit_KiloMeter"  Kombi_PAG_PF

CM_ SG_ 391 EV_Rekuperationsstufe "Im Kombi anzuzeigende Rekuperationsstufe";
CM_ SG_ 391 HV_Bordnetz_aktiv "Signalisiert ein aktives Hochvoltbordnetz. HV-Schütze geschlossen. Im Fehlerfall wird das Bit nicht gesetzt.(Klemmende Schütze)";
CM_ SG_ 391 MO_Waehlpos "Wählhebelposition (im VW120/7 und MQB Omega ist der Wählhebel am HCAN mit Master Motor-SG angeschlossen)

(wenn Signal in MSG_HYB_03: Signal nur in der CAN-Welt PQ35/25 zu verwenden, da dort am ACAN die Wählhebelposition nicht abgesichert übertragen wir";
CM_ SG_ 391 MO_Tankbereitschaft_Status "Meldung der Tankbereitschaft";
CM_ SG_ 391 MO_Tankklappensteuerung "Ansteuerungsanforderung der Tankklappe";
CM_ SG_ 391 MO_HVEM_Eskalation "Eskalationsbit, mit diesem zusammen darf MO_HVEM_MaxLeistung < der minimal angeforderten Leistung sein und ist durch das HVEM durch Ergreifung aller Eskalationsmaßnahmen umzusetzen (Bei neg. Ladebilanz z.B. im Leerlauf nötig, um die HVBatt vor Entladung e";
CM_ SG_ 391 MO_HVEM_MaxLeistung "Maximal zulässige Leistung, die das HVEM einzustellen hat. 
Ohne Eskalationsbit ist diese Anforderung >= der Minimal benötigten Leistung des HVEM";
CM_ BO_ 811 "Motor - Getriebe - Schnittstelle auf CAN-Antrieb (nur Hybrid)";
CM_ SG_ 811 MO_HYB_E_Faktor "Signed Nibble, verwendet vom GSG zur Interpolation zwischen VMKennfeld und dem Rekuperations-Grenzkennfeld (negative Werte des E-Faktors) bzw. dem Boost-Grenzkennfeld (positive Werte des E-Faktors).
0000 = VM-Kennfeld (keine Interpolation)
0001..0111 = ";
CM_ SG_ 811 MO_HYB_Drehzahl_VM "für OBD freeze frame";
CM_ SG_ 811 MO_HYB_LowSpeedModus "MSG legt fest:
0 = klassisches Ausrollen/Anfahren mit N_mot >= N_Leerlauf_VM
1 = elektr. Ausrollen/Anfahren mit geschl. Triebstrang mit N_mot < N_Leerlauf_VM";
CM_ SG_ 811 MO_FahrPr1_verfuegbar "Verfügbarkeitsanzeige des Fahrprogramm 1";
CM_ SG_ 811 MO_FahrPr2_verfuegbar "Verfügbarkeitsanzeige des Fahrprogramm 2";
CM_ SG_ 811 MO_FahrPr3_verfuegbar "Verfügbarkeitsanzeige des Fahrprogramm 3";
CM_ SG_ 811 MO_FahrPr4_verfuegbar "Verfügbarkeitsanzeige des Fahrprogramm 4";
CM_ SG_ 811 MO_FahrPr5_verfuegbar "Verfügbarkeitsanzeige des Fahrprogramm 5";
CM_ SG_ 811 MO_FahrPr6_verfuegbar "Verfügbarkeitsanzeige des Fahrprogramm 6";
CM_ SG_ 811 MO_FahrPr7_verfuegbar "Verfügbarkeitsanzeige des Fahrprogramm 7";
CM_ SG_ 305 MO_ePowermeter "Anzeige ePowermeter (Fahrreserve elektrisch bis Start Verbrennungsmotor (Verbrenner startet bei 100%))";
CM_ SG_ 305 MO_W_Reku_normiert_ueberlauf "Motorsteuergeräteinterner Rekuperationszähler, der vom Kombi ausgewertet wird, um die Rekuperierte Arbeit/Leistung zu erfassen.";
CM_ SG_ 305 Ladezustand "Ladezustand der Batterie
";
CM_ SG_ 305 Enrgfluss_State "Energiefluss zwischen den Achsen, Batterie, Elektromotor und Verbrennungsmotor";
CM_ SG_ 305 MO_W_Reku_normiert "Motorsteuergeräteinterner Rekuperationszähler, der vom Kombi ausgewertet wird, um die Rekuperierte Arbeit/Leistung zu erfassen.";
CM_ SG_ 305 MO_Powermeter "Anzeigewerte im Kombi
0       = Unteres Ende Bremsen/grau;
340   = Unteres Ende CHARGE;
1020 = READY;
1870 = Oberes Ende EFFICIENCY;
3400 = 100%;
4080 = MAX;";
CM_ BO_ 931 "Kopie der Originalbotschaft
aus Rückwärtskompatibilitätsgründen nur für PAG angelegt";
CM_ SG_ 931 Motor_02_CHK "Berechnung siehe Lastenheft 'Kommunikationsabsicherung für FlexRay und CAN'
Endwerte siehe 'Kommunikationsabsicherung für FlexRay und CAN / Anhang C: Tabelle S-PDU Kennungen'";
CM_ SG_ 931 MO_Mom_ZWR "Minimales Motormoment bei Zündwinkelrücknahme.

Achtung:
Einheitenloser CAN-Wert.
Faktor in MO_Faktor_Momente in Motor_Code_01 beachten!";
CM_ SG_ 931 MO_Mom_Soll "Achtung:
Einheitenloser CAN-Wert.
Faktor in MO_Faktor_Momente in Motor_Code_01 beachten!

Sollmoment ohne P und D Anteil des Leerlaufreglers, ohne Antiruckelfunktion und ohne Getriebeeingriff";
CM_ SG_ 931 MO_Mom_Ist "Achtung:
Einheitenloser CAN-Wert.
Faktor in MO_Faktor_Momente in Motor_Code_01 beachten!

Istmoment ohne P und D Anteil des Leerlaufreglers, ohne Antiruckelfunktion und ohne Getriebeeingriff";
CM_ SG_ 931 MO_Status_Zylabschalt_01 "Statusbit: Motor ist in Zylinderabschaltregelung";
CM_ SG_ 931 MO_Status_Normalbetrieb_01 "Das Motorsteuergerät sendet das Informationsbit, wenn die Initialisierungsphase des Steuergerätes abgeschlossen ist. Zusätzlich muss die Klemme 15 eingeschalten sein und eine applizierbare Mindestdrehzahlschwelle (Kennlinie in Abh. von der Kühlwassertempe";
CM_ SG_ 931 MO_StartStopp_Status "Aktivitätsstatus Start/Stopp-Koordinator
HYBRID:
Wenn MO_Hybridfahrzeug = 1 gilt:
Signal bezieht sich nur auf den Verbrennungsmotor, nicht auf den Hybridantrieb
";
CM_ SG_ 931 MO_StartStopp_Motorstopp "Motor-Stopp durch Start/Stopp-Koordinator
HYBRID:
Wenn MO_Hybridfahrzeug = 1 gilt:
Verbrennungsmotor durch Hybrid-Koordinator im MSG ausgeschaltet. 
Die definierten Start/Stopp-Signale beziehen sich nur auf den Verbrennungsmotor!";
CM_ SG_ 931 MO_StartStopp_Wiederstart "Motorwiederstart durch Start/Stopp-Koordinator
HYBRID:
Wenn MO_Hybridfahrzeug =1 gilt:
Warnung vor Spannungseinbruch beim Zustart des Verbrennungsmotors. 
-nicht relevant, da derzeit kein Start über 12V-Starter geplant-
Dieses Signal wird nur vom Hyb";
CM_ SG_ 931 MO_Ext_E_Fahrt_aktiv "MLB: Funktionsrückmeldung zum erw. E-Fahr-Betrieb über Lampe/LED im E-Mode-Taster";
CM_ SG_ 931 MO_Gangposition "Stellung des Wählhebels in der Schaltgasse des Handschaltgetriebes.";
CM_ SG_ 931 MO_StartStopp_Fahrerwunsch "Fahreraktivität Start/Stop";
CM_ SG_ 931 MO_Momentenintegral "100 %  entspricht volle Verfügbarkeit aktuell vorhanden. 0 % entspricht Integral bis Limit gefüllt, erhöhender Eingriff kann aktuell nicht berücksichtigt werden oder erhöhender Eingriff ist in diesem Projekt nicht möglich (applikativ deaktiviert) oder auf";
CM_ SG_ 1747 NM_CDR_PCM_Start_1 "Transition in NMH-Statemachine: 'Bus-Sleep' ==> 'Start'
Das Bit wird von der Standard-SW bedient.";
CM_ SG_ 1747 NM_CDR_PCM_Start_2 "Transition in NMH-Statemachine: 'Prepare To Sleep' ==> 'Start'
Das Bit wird von der Standard-SW bedient.";
CM_ SG_ 1747 NM_CDR_PCM_Normal_Mode_1 "Transition in NMH-Statemachine: 'Start' ==> 'Normal Mode'
Das Bit wird von der Standard-SW bedient.";
CM_ SG_ 1747 NM_CDR_PCM_Normal_Mode_2 "Transition in NMH-Statemachine: 'Ready To Sleep' ==> 'Normal'
Das Bit wird von der Standard-SW bedient.";
CM_ SG_ 1747 NM_CDR_PCM_Car_WakeUp "Das Bit wird vom Waehlhebel nicht bedient. Die Car Wakeup-Funktionalität ist im Waehlhebel nicht umgesetzt.
";
CM_ SG_ 1747 NM_CDR_PCM_Per_WakeUp "Peripherie-Wakeup (Peripherie inkl. CAN hat geweckt)
";
CM_ SG_ 1747 NM_CDR_PCM_Fkt_WakeUp "Funktions-Wakeup (Softwarefunktion hat geweckt)
";
CM_ SG_ 1747 NM_CDR_PCM_Klemme_15 "NM-Nachlaufursache: Der Waehllhebel sendet noch NM-high Botschaften (befindet sich nicht im Zustand 'Ready To Sleep') aufgrund der Mindestaktivzeit von 4s. In diesem Fall wird das Bit vom Waehlhebel gesetzt.";
CM_ SG_ 1747 NM_CDR_PCM_Diagnose "NM-Nachlaufursache: Der Waehllhebel sendet noch NM-high Botschaften (befindet sich nicht im Zustand 'Ready To Sleep') aufgrund der Mindestaktivzeit von 4s. In diesem Fall wird das Bit vom Waehlhebel gesetzt.";
CM_ SG_ 1747 NM_CDR_PCM_MindestAktivZeit "NM-Nachlaufursache: Der Waehllhebel sendet noch NM-high Botschaften (befindet sich nicht im Zustand 'Ready To Sleep') aufgrund der Mindestaktivzeit von 4s. In diesem Fall wird das Bit vom Waehlhebel gesetzt.";
CM_ SG_ 1747 NMH_CDR_PCM_Signalfehler "Bei der Speicherung eines CAN-Signalfehlers muss dieser mindestens einmal in der NM-Botschaft angezeigt werden.";
CM_ SG_ 1747 NM_CDR_PCM_TimeOut_Fehler "Der Waehlhebel hat einen aktiven Timeout-Fehler zu einem anderen SG erkannt und setzt dieses Bit. Der FSP-Eintrag ist aktiv. Sobald wieder Botschaften des anderen Teilnehmers empfangen werden (FSP-Eintrag passiv), wird das Bit zurückgesetzt.";
CM_ SG_ 1747 NM_CDR_PCM_CAN_Diag_deaktiv "Das Bit wird vom Waehlhebel in folgenden Fällen gesetzt (CAN-Diagnose ist deaktiv):
- Hochlauf des Steuergeräts nach CAN-Wakeup (t_diag_start ist noch nicht abgelaufen)
- Retriggerung von t_diag_start bei Kl.15 EIN
- Unterspannung (U < 9V)
- Überspann";
CM_ SG_ 1747 NM_CDR_PCM_Transport_Mode "Funktionseinschränkung aufgrund Transportmodus aktiv:
";
CM_ SG_ 1747 NM_CDR_PCM_Abschaltstufe_aktiv "Funktionseinschränkung aufgrund Abschaltstufe aktiv:


";
CM_ SG_ 1747 NM_CDR_PCM_Busfehler "Das Bit wird vom Waehlhebel gesetzt, wenn der ERROR-Pin des CAN-Transceivers dem µController einen Fehler signalisiert.";
CM_ SG_ 1747 NMH_CDR_PCM_Subsystemaktiv "Zeigt an ob ein Subsystem des SGs nach Klemme15 AUS und nach entsprechender MAX Aktivzeit noch aktiv war";
CM_ BO_ 1728 "D4 Kombi-Komfort 200ms";
CM_ SG_ 1728 NMH_GW_Start_1 "Zustand Start (<--Sleep)";
CM_ SG_ 1728 NMH_GW_Start_2 "Zustand Start (<--Prepare to Sleep)";
CM_ SG_ 1728 NMH_GW_Normal_Mode_1 "Zustand Normal Mode (<-- Start)";
CM_ SG_ 1728 NMH_GW_Normal_Mode_2 "Zustand Normal Mode (<-- Ready to Sleep)";
CM_ SG_ 1728 NMH_GW_Car_WakeUp "Car WakeUp (optional), wird vom GW nicht gesendet";
CM_ SG_ 1728 NMH_GW_Per_WakeUp "Weckursache Peripherie
";
CM_ SG_ 1728 NMH_GW_Fkt_WakeUp "Weckursache Funktion (Softwarefunktion hat geweckt)
0 = wenn Peripheriewakeup
1 = BDM BEM
2 = Car Wakeup empfangen: Das Bussegment wurde aufgrund einer CarWakeup Anforderung geweckt. Das GW hat zuvor eine NWM-Botschaft auf einem Bus mit aktiviertem Car";
CM_ SG_ 1728 NMH_GW_NM_aktiv_Klemme_15 "Kl.15 EIN (Nachlaufursache, nicht 'Ready To Sleep')";
CM_ SG_ 1728 NMH_GW_NM_aktiv_Diagnose "Diagnose bei Kl 15 aus (Nachlaufursache, nicht 'Ready To Sleep')";
CM_ SG_ 1728 NMH_GW_NM_aktiv_Start "Mindestaktivzeit Zustand 'Start' (Nachlaufursache, nicht 'Ready To Sleep')";
CM_ SG_ 1728 NMH_GW_NM_aktiv_BDM "BDM-Kommunikation (Nachlaufursache, nicht 'Ready To Sleep')
";
CM_ SG_ 1728 NMH_GW_NM_aktiv_Warnblinken "Warnblinken (NM-Nachlaufursache, nicht 'Ready To Sleep')
";
CM_ SG_ 1728 NMH_GW_NM_aktiv_ESP "ESP aktiv (Wakeup/Sleep-Konzept)
(NM-Nachlaufursache, nicht 'Ready To Sleep')
";
CM_ SG_ 1728 NMH_GW_NM_aktiv_EMP "Nachlauf Energiemanagementplannung";
CM_ SG_ 1728 NMH_GW_Abschaltstufe_3 "Abschaltstufe 3 (BEM) 
(SG-interner Nachlauf vor CAN-Wakeup)
";
CM_ SG_ 1728 NMH_GW_SG_Fehlerdauer "Steuergeraetefehlerdauer (BEM)
(SG-interner Nachlauf vor CAN-Wakeup)
";
CM_ SG_ 1728 NMH_GW_STH_Wakeup "Standheizungswakeup (BEM)
(SG-interner Nachlauf vor CAN-Wakeup)";
CM_ SG_ 1728 NMH_GW_NL_Diagnose "Gateway hat lokalen Nachlauf wegen Kommunikation mit Tester auf DiagCAN";
CM_ SG_ 1728 NM_GW_Signalfehler "Bei der Speicherung eines CAN-Signalfehlers muss dieser mindestens einmal in der NM-Botschaft angezeigt werden.";
CM_ SG_ 1728 NMH_GW_TimeOut_Fehler "Aktiver Timeout Fehlerspeichereintrag";
CM_ SG_ 1728 NMH_GW_CAN_Diag_deaktiv "CAN Bus bezogene Eigendiagnose deaktiviert (Überspannung, Unterspannung, Hochlaufphase, ...) ";
CM_ SG_ 1728 NMH_GW_KompSchutz "Funktionseinschränung aufgrund Komponentenschutz aktiv";
CM_ SG_ 1728 NMH_GW_Mute_Mode "Funktionseinschränung aufgrund Mute Mode aktiv, nur VW";
CM_ SG_ 1728 NMH_GW_Transport_Mode "Funktionseinschränung aufgrund Transport Mode aktiv";
CM_ SG_ 1728 NMH_GW_Abschaltstufe_aktiv "Funktionsabschaltung wegen Abschaltschaltstufe";
CM_ SG_ 1728 NMH_GW_Eindraht_Fehler "Erkennung Eindrahtfehler";
CM_ SG_ 1728 NMH_GW_ACAN "Antriebs-CAN aktiv (Wakeup/Sleep Konzept)
(NM-Nachlaufursache, nicht 'Ready To Sleep')
";
CM_ SG_ 1728 NMH_GW_KombiCAN "Kombi/Fahrwerks-CAN aktiv (Wakeup/Sleep Konzept)
(NM-Nachlaufursache, nicht 'Ready To Sleep')
";
CM_ SG_ 1728 NMH_GW_KomfortCAN "Komfort-CAN aktiv (Wakeup/Sleep Konzept)
(NM-Nachlaufursache, nicht 'Ready To Sleep')

";
CM_ SG_ 1728 NMH_GW_Infotainment "Infotainment aktiv (CAN oder MOST), Wakeup/Sleep-Konzept
(NM-Nachlaufursache, nicht 'Ready To Sleep')
";
CM_ SG_ 1728 NMH_GW_Fahrwerk "Fahrwerks-Bus aktiv (Wakeup/Sleep Konzept)
(NM-Nachlaufursache, nicht 'Ready To Sleep')
";
CM_ SG_ 1728 NMH_GW_WakeUp_CAN_Bus "Weckendes Bussegment (Welcher CAN hat geweckt bzw. CarWakeup angefordert?)

";
CM_ BO_ 1775 "200ms";
CM_ SG_ 1775 NMH_GSM_Start_1 "Zustand Start (<--Sleep)";
CM_ SG_ 1775 NMH_GSM_Start_2 "Zustand Start (<--Prepare to Sleep)";
CM_ SG_ 1775 NMH_GSM_Normal_Mode_1 "Zustand Normal Mode (<-- Start)";
CM_ SG_ 1775 NMH_GSM_Normal_Mode_2 "Zustand Normal Mode (<-- Ready to Sleep)";
CM_ SG_ 1775 NMH_GSM_Car_WakeUp "Car WakeUp optional, wird vom SG nicht bedient
";
CM_ SG_ 1775 NMH_GSM_Per_WakeUp "Weckursache Peripherie
";
CM_ SG_ 1775 NMH_GSM_Fkt_WakeUp "Weckursache Funktion
";
CM_ SG_ 1775 NMH_GSM_Klemme_15 "Kl.15 EIN (Nachlaufursache, SG nicht im NM-Zustand 'Ready to Sleep')
";
CM_ SG_ 1775 NMH_GSM_Diagnose "Diagnose bei Kl 15 aus (Nachlaufursache, SG nicht im NM-Zustand 'Ready to Sleep')
";
CM_ SG_ 1775 NMH_GSM_MindestAktivZeit "Mindestaktivzeit Taktiv_min (Nachlaufursache, SG nicht im NM-Zustand 'Ready to Sleep') / nSTART
";
CM_ SG_ 1775 NMH_GSM_Signalfehler "Bei der Speicherung eines CAN-Signalfehlers muss dieser mindestens einmal in der NM-Botschaft angezeigt werden.";
CM_ SG_ 1775 NMH_GSM_TimeOut_Fehler "Aktiver Timeout Fehlerspeichereintrag";
CM_ SG_ 1775 NMH_GSM_CAN_Diag_deaktiv "CAN-Diagnose deaktiv (Überspannung, Unterspannung, Hochlaufphase, ...) ";
CM_ SG_ 1775 NMH_GSM_KompSchutz "Funktionseinschränung aufgrund Komponentenschutz aktiv";
CM_ SG_ 1775 NMH_GSM_Mute_Mode "Funktionseinschränung aufgrund Mute Mode aktiv, nur VW";
CM_ SG_ 1775 NMH_GSM_Transport_Mode "Funktionseinschränung aufgrund Transport Mode aktiv";
CM_ SG_ 1775 NMH_GSM_Abschaltstufe_aktiv "Funktionsabschaltung wegen Abschaltschaltstufe";
CM_ SG_ 1775 NMH_GSM_Eindraht_Fehler "Erkennung Eindrahtfehler";
CM_ SG_ 1775 NMH_GSM_Lokalaktiv "Zeigt an ob Steuergerät lokal aktiv war";
CM_ SG_ 1775 NMH_GSM_Subsystemaktiv "Zeigt an ob ein Subsystem des SGs nach Klemme15 AUS und nach entsprechender MAX Aktivzeit noch aktiv war";
CM_ BO_ 1772 "200ms

im RSe TME";
CM_ SG_ 1772 NMH_KL_Start_1 "Zustand Start (<--Sleep)";
CM_ SG_ 1772 NMH_KL_Start_2 "Zustand Start (<--Prepare to Sleep)";
CM_ SG_ 1772 NMH_KL_Normal_Mode_1 "Zustand Normal Mode (<-- Start)";
CM_ SG_ 1772 NMH_KL_Normal_Mode_2 "Zustand Normal Mode (<-- Ready to Sleep)";
CM_ SG_ 1772 NM_KL_Car_WakeUp "Car WakeUp optional";
CM_ SG_ 1772 NM_KL_Per_WakeUp "Weckursache Peripherie

";
CM_ SG_ 1772 NM_KL_Fkt_WakeUp "Weckursache Funktion
";
CM_ SG_ 1772 NM_KL_Klemme_15 "Kl.15 EIN (Nachlaufursache, SG nicht im NM-Zustand 'Ready to Sleep')";
CM_ SG_ 1772 NM_KL_Diagnose "Diagnose bei Kl 15 aus (Nachlaufursache, SG nicht im NM-Zustand 'Ready to Sleep')";
CM_ SG_ 1772 NM_KL_MindestAktivZeit "Mindestaktivzeit Taktiv_min (Nachlaufursache, SG nicht im NM-Zustand 'Ready to Sleep')";
CM_ SG_ 1772 NM_KL_FKT_Nachlauf_Klappen "Funktionsnachlauf Klappen (Nachlaufursache, SG nicht im NM-Zustand 'Ready to Sleep')";
CM_ SG_ 1772 NM_KL_NL_STH "Nachlaufursache Standheizung";
CM_ SG_ 1772 NM_KL_NL_Restwaerme "Nachlaufursache Restwärme
";
CM_ SG_ 1772 NM_KL_NL_LIN "Nachlaufursache LIN
";
CM_ SG_ 1772 NM_Klima_Signalfehler "Bei der Speicherung eines CAN-Signalfehlers muss dieser mindestens einmal in der NM-Botschaft angezeigt werden.";
CM_ SG_ 1772 NM_KL_TimeOut_Fehler "Aktiver Timeout Fehlerspeichereintrag";
CM_ SG_ 1772 NM_KL_CAN_Diag_deaktiv "CAN Bus bezogene Eigendiagnose deaktiviert (Überspannung, Unterspannung, Hochlaufphase, ...) ";
CM_ SG_ 1772 NM_KL_KompSchutz "Funktionseinschränkung aufgrund Komponentenschutz aktiv";
CM_ SG_ 1772 NM_KL_Mute_Mode "Funktionseinschränung aufgrund Mute Mode aktiv, nur VW";
CM_ SG_ 1772 NM_KL_Transport_Mode "Funktionseinschränung aufgrund Transport Mode aktiv";
CM_ SG_ 1772 NM_KL_Abschaltstufe_aktiv "Funktionsabschaltung wegen Abschaltschaltstufe";
CM_ SG_ 1772 NM_KL_Eindraht_Fehler "Erkennung Eindrahtfehler";
CM_ SG_ 1772 NMH_Klima_Lokalaktiv "Zeigt an ob das SG nach Klemme15 AUS und nach entsprechender MAX Aktivzeit noch aktiv war";
CM_ SG_ 1772 NMH_Klima_Subsystemaktiv "Zeigt an ob ein Subsystem des SGs nach Klemme15 AUS und nach entsprechender MAX Aktivzeit noch aktiv war";
CM_ BO_ 1735 "D4 NMH-Kombi 200ms";
CM_ SG_ 1735 NMH_KBI_Start_1 "Zustand Start (<--Sleep)";
CM_ SG_ 1735 NMH_KBI_Start_2 "Zustand Start (<--Prepare to Sleep)";
CM_ SG_ 1735 NMH_KBI_Normal_Mode_1 "Zustand Normal Mode (<-- Start)";
CM_ SG_ 1735 NMH_KBI_Normal_Mode_2 "Zustand Normal Mode (<-- Ready to Sleep)";
CM_ SG_ 1735 NMH_KBI_Car_WakeUp "Car WakeUp (optional), wird vom Kombi nicht gesendet";
CM_ SG_ 1735 NMH_KBI_Per_WakeUp "Weckursache Peripherie
";
CM_ SG_ 1735 NMH_KBI_Fkt_WakeUp "Weckursache Funktion

";
CM_ SG_ 1735 NMH_KBI_NM_aktiv_Klemme_15 "Klemme 15 ein (NM-Nachlaufursache, nicht 'Ready To Sleep')
";
CM_ SG_ 1735 NMH_KBI_NM_aktiv_Diagnose "Diagnose bei Kl 15 aus (NM-Nachlaufursache, nicht 'Ready To Sleep')
";
CM_ SG_ 1735 NMH_KBI_NM_aktiv_Start "Mindestaktivzeit Zustand 'Start' (NM-Nachlaufursache, nicht 'Ready To Sleep')
 ";
CM_ SG_ 1735 NMH_KBI_NM_aktiv_Tankinhalt "Referenzwertbildung Tankinhalt (NM-Nachlaufursache, nicht 'Ready To Sleep')";
CM_ SG_ 1735 NMH_KBI_NM_aktiv_Display "Display aktiv (Good-Bye-Screen) 
(NM-Nachlaufursache, nicht 'Ready To Sleep')
";
CM_ SG_ 1735 NMH_KBI_kein_NL "kein lokaler / SG interner Nachlauf vor Wakeup";
CM_ SG_ 1735 NMH_KBI_NL_Sync_Funkuhr "Synchronisation Funkuhr (lokaler / SG interner Nachlauf vor Wakeup)
";
CM_ SG_ 1735 NM_Kombi_NL_Warnblinken "Lokale Aktivität vor Wakeup: freilaufendes Warnblinken";
CM_ SG_ 1735 NMH_KBI_NL_KL15 "Nachlauf Kl. 15 aus  (lokaler / SG interner Nachlauf vor Wakeup)";
CM_ SG_ 1735 NMH_KBI_Signalfehler "Bei der Speicherung eines CAN-Signalfehlers muss dieser mindestens einmal in der NM-Botschaft angezeigt werden.";
CM_ SG_ 1735 NMH_KBI_TimeOut_Fehler "Aktiver Timeout Fehlerspeichereintrag  ";
CM_ SG_ 1735 NMH_KBI_CAN_Diag_deaktiv "CAN Bus bezogene Eigendiagnose deaktiviert (Überspannung, Unterspannung, Hochlaufphase, ...) ";
CM_ SG_ 1735 NMH_KBI_KompSchutz "Funktionseinschränung aufgrund Komponentenschutz aktiv";
CM_ SG_ 1735 NMH_KBI_Mute_Mode "Funktionseinschränung aufgrund Mute Mode aktiv, nur VW";
CM_ SG_ 1735 NMH_KBI_Transport_Mode "Funktionseinschränung aufgrund Transport Mode aktiv";
CM_ SG_ 1735 NMH_KBI_Abschaltstufe_aktiv "Funktionsabschaltung wegen Abschaltschaltstufe";
CM_ SG_ 1735 NMH_KBI_Eindraht_Fehler "Erkennung Eindrahtfehler";
CM_ SG_ 1735 NMH_Kombi_Lokalaktiv "Zeigt an ob das SG nach Klemme15 AUS und nach entsprechender MAX Aktivzeit noch aktiv war";
CM_ SG_ 1735 NMH_Kombi_Subsystemaktiv "Zeigt an ob ein Subsystem des SGs nach Klemme15 AUS und nach entsprechender MAX Aktivzeit noch aktiv war";
CM_ SG_ 1750 NMH_Miko_Start_1 "Zustand Start (<--Sleep)";
CM_ SG_ 1750 NMH_Miko_Start_2 "Zustand Start (<--Prepare to Sleep)";
CM_ SG_ 1750 NMH_Miko_Normal_Mode_1 "Zustand Normal Mode (<-- Start)";
CM_ SG_ 1750 NMH_Miko_Normal_Mode_2 "Zustand Normal Mode (<-- Ready to Sleep)";
CM_ SG_ 1750 NMH_Miko_Car_WakeUp "Car WakeUp optional";
CM_ SG_ 1750 NMH_Miko_Per_WakeUp "Weckurasche Peripherie
";
CM_ SG_ 1750 NMH_Miko_Fkt_WakeUp "Weckursache Funktion
";
CM_ SG_ 1750 NMH_Miko_Signalfehler "Bei der Speicherung eines CAN-Signalfehlers muss dieser mindestens einmal in der NM-Botschaft angezeigt werden.";
CM_ SG_ 1750 NMH_Miko_TimeOut_Fehler "Aktiver Timeout Fehlerspeichereintrag";
CM_ SG_ 1774 NM_RDK_Start_1 "Zustand Start (<--Sleep)";
CM_ SG_ 1774 NM_RDK_Start_2 "Zustand Start (<--Prepare to Sleep)";
CM_ SG_ 1774 NM_RDK_Normal_Mode_1 "Zustand Normal Mode (<-- Start)";
CM_ SG_ 1774 NM_RDK_Normal_Mode_2 "Zustand Normal Mode (<-- RTS)";
CM_ SG_ 1774 NM_RDK_Car_WakeUp "Car WakeUp optional";
CM_ SG_ 1774 NM_RDK_Per_WakeUp "Weckursache Peripherie
";
CM_ SG_ 1774 NM_RDK_Fkt_WakeUp "Weckursache Funktion
";
CM_ SG_ 1774 NM_RDK_Klemme_15 "Kl.15 EIN (Nachlaufursache, kein Sleep Ind gesetzt)";
CM_ SG_ 1774 NM_RDK_Diagnose "Diagnose bei Kl 15 aus (Nachlaufursache, kein Sleep Ind gesetzt)";
CM_ SG_ 1774 NM_RDK_MindestAktivZeit "Mindestaktivzeit Taktiv_min (Nachlaufursache, kein Sleep Ind gesetzt)";
CM_ SG_ 1774 NMH_RDK_NL_Radmanagement "Radmanagement aktiv";
CM_ SG_ 1774 NM_RDK_Signalfehler "Bei der Speicherung eines CAN-Signalfehlers muss dieser mindestens einmal in der NM-Botschaft angezeigt werden.";
CM_ SG_ 1774 NM_RDK_TimeOut_Fehler "Aktiver Timeout Fehlerspeichereintrag";
CM_ SG_ 1774 NM_RDK_CAN_Diag_deaktiv "CAN Bus bezogene Eigendiagnose deaktiviert (Überspannung, Unterspannung, Hochlaufphase, ...) ";
CM_ SG_ 1774 NM_RDK_KompSchutz "Funktionseinschränung aufgrund Komponentenschutz aktiv";
CM_ SG_ 1774 NM_RDK_Mute_Mode "Funktionseinschränung aufgrund Mute Mode aktiv, nur VW";
CM_ SG_ 1774 NM_RDK_Transport_Mode "Funktionseinschränung aufgrund Transport Mode aktiv";
CM_ SG_ 1774 NM_RDK_Abschaltstufe_aktiv "Funktionsabschaltung wegen Abschaltschaltstufe";
CM_ SG_ 1774 NM_RDK_Eindraht_Fehler "Erkennung Eindrahtfehler";
CM_ SG_ 1774 NMH_RDK_Lokalaktiv "Zeigt an ob Steuergerät lokal aktiv war";
CM_ SG_ 1774 NMH_RDK_Subsystemaktiv "Zeigt an ob ein Subsystem des SGs nach Klemme15 AUS und nach entsprechender MAX Aktivzeit noch aktiv war";
CM_ BO_ 1156 "Netzwerk Power Management
Network Control Botschaft
";
CM_ SG_ 1156 NPM_ForceShutdown "ForceSleep
";
CM_ SG_ 1156 NPM_PreventWakeup "PreventWakeup";
CM_ SG_ 1156 NPM_FS_VSG "Force Shutdown VSG";
CM_ SG_ 1156 NPM_FS_HAL "Force Shutdown HAL - Hinterachslenkung";
CM_ SG_ 1156 NPM_FS_Vorhalt03 "Force Shutdown Vorhalt
";
CM_ SG_ 1156 NPM_FS_Vorhalt04 "Force Shutdown Vorhalt
";
CM_ SG_ 1156 NPM_FS_EPB "Force Shutdown El. Parkbremse
";
CM_ SG_ 1156 NPM_FS_Niveau "Force Shutdown Niveau & PASM
";
CM_ SG_ 1156 NPM_FS_BCM1 "Force Shutdown BCM Vorne
";
CM_ SG_ 1156 NPM_FS_BCM2 "Force Shutdown BCM Hinten";
CM_ SG_ 1156 NPM_FS_TF "Force Shutdown Tuer Fahrer
";
CM_ SG_ 1156 NPM_FS_TB "Force Shutdown Tuer Beifahrer";
CM_ SG_ 1156 NPM_FS_Lenkhilfe "Force Shutdown Lenkhilfe";
CM_ SG_ 1156 NPM_FS_Vorhalt12 "Force Shutdown Vorhalt";
CM_ SG_ 1156 NPM_FS_SF "Force Shutdown Sitz Fahrer
";
CM_ SG_ 1156 NPM_FS_SB "Force Shutdown Sitz Beifahrer
";
CM_ SG_ 1156 NPM_FS_SMLS "Force Shutdown Kombilenksäulenmodul
";
CM_ SG_ 1156 NPM_FS_RDK "Force Shutdown RDK
";
CM_ SG_ 1156 NPM_FS_AAG "Force Shutdown Anhängersteuergerät
";
CM_ SG_ 1156 NPM_FS_HDSG "Force Shutdown PowerLiftGate (Heckklappe)
";
CM_ SG_ 1156 NPM_FS_RFK "Force Shutdown Rückfahrkamera
";
CM_ SG_ 1156 NPM_FS_TopView "Force Shutdown TopView";
CM_ SG_ 1156 NPM_FS_Vorhalt21 "Force Shutdown Vorhalt
";
CM_ SG_ 1156 NPM_FS_KMB "Force Shutdown Kombiinstrument";
CM_ SG_ 1156 NPM_FS_Miko "Force Shutdown Mittelkonsole
";
CM_ SG_ 1156 NPM_FS_SU "Force Shutdown Stoppuhr
";
CM_ SG_ 1156 NPM_FS_HU "Force Shutdown PCM
";
CM_ SG_ 1156 NPM_FS_BKE "Force Shutdown Bedien- Klimaeinheit";
CM_ SG_ 1156 NPM_FS_Vorhalt27 "Force Shutdown Vorhalt
";
CM_ SG_ 1156 NPM_PrWu_VSG "Prevent Wakeup VSG
";
CM_ SG_ 1156 NPM_PrWu_HAL "Prevent Wakeup HAL- Hinterachslenkung
";
CM_ SG_ 1156 NPM_PrWu_Vorhalt03 "Prevent Wakeup Vorhalt";
CM_ SG_ 1156 NPM_PrWu_Vorhalt04 "Prevent Wakeup Vorhalt
";
CM_ SG_ 1156 NPM_PrWu_EPB "Prevent Wakeup EPB
";
CM_ SG_ 1156 NPM_PrWu_Niveau "Prevent Wakeup Niveau & PASM
";
CM_ SG_ 1156 NPM_PrWu_BCM1 "Prevent Wakeup BCM Vorne";
CM_ SG_ 1156 NPM_PrWu_BCM2 "Prevent Wakeup BCM Hinten
";
CM_ SG_ 1156 NPM_PrWu_TF "Prevent Wakeup Tuer Fahrer
";
CM_ SG_ 1156 NPM_PrWu_TB "Prevent Wakeup Tuer Beifahrer
";
CM_ SG_ 1156 NPM_PrWu_Lenkhilfe "Prevent Wakeup Lenkhilfe
";
CM_ SG_ 1156 NPM_PrWu_SF "Prevent Wakeup Sitz Fahrer
";
CM_ SG_ 1156 NPM_PrWu_SB "Prevent Wakeup Sitz Beifahrer
";
CM_ SG_ 1156 NPM_PrWu_SMLS "Prevent Wakeup Kombilenksäulenmodul
";
CM_ SG_ 1156 NPM_PrWu_RDK "Prevent Wakeup RDK";
CM_ SG_ 1156 NPM_PrWu_AAG "Prevent Wakeup Anhängersteuergerät
";
CM_ SG_ 1156 NPM_PrWu_HDSG "Prevent Wakeup PLG
";
CM_ SG_ 1156 NPM_PrWu_RFK "Prevent Wakeup Rückfahrkamera
";
CM_ SG_ 1156 NPM_PrWu_TopView "Prevent Wakeup TopView";
CM_ SG_ 1156 NPM_PrWu_Vorhalt21 "Prevent Wakeup Vorhalt";
CM_ SG_ 1156 NPM_PrWu_KMB "Prevent Wakeup Kombiinstrument
";
CM_ SG_ 1156 NPM_PrWu_Miko "Prevent Wakeup Mittelkonsole
";
CM_ SG_ 1156 NPM_PrWu_SU "Prevent Wakeup Stoppuhr
";
CM_ SG_ 1156 NPM_PrWu_HU "Prevent Wakeup PCM
";
CM_ SG_ 1156 NPM_PrWu_BKE "Prevent Wakeup BKE
";
CM_ SG_ 1156 NPM_PrWu_Vorhalt27 "Prevent Wakeup Vorhalt";
CM_ BO_ 1630 "Tankgeberwerte für OBD-relevante Plausibilisierung im Motor-SG";
CM_ SG_ 1630 OBD_TG_F_Status_1 "Fehlerstatus Tankfüllstandsgeber (OBD relevanter Sensor für Tankleckdiagnose)";
CM_ SG_ 1630 OBD_TG_F_Status_2 "Fehlerstatus Tankfüllstandsgeber (OBD relevanter Sensor für Tankleckdiagnose)

0x00 = kein Fehler / Init / nicht verbaut
0x01 = KS-
0x02 = KS+ (B8: nicht bedient)
0x03 = OC (Leitungsunterbrechung) (B8: nicht bedient)
0x04 = OOR+ (out of range high) ";
CM_ SG_ 1630 OBD_TG_F_Status_3 "Fehlerstatus Tankfüllstandsgeber (OBD relevanter Sensor für Tankleckdiagnose)

0x00 = kein Fehler / Init / nicht verbaut
0x01 = KS-
0x02 = KS+ (B8: nicht bedient)
0x03 = OC (Leitungsunterbrechung) (B8: nicht bedient)
0x04 = OOR+ (out of range high) ";
CM_ SG_ 1630 OBD_TG_F_Status_4 "Fehlerstatus Tankfüllstandsgeber (OBD relevanter Sensor für Tankleckdiagnose)

0x00 = kein Fehler / Init / nicht verbaut
0x01 = KS-
0x02 = KS+ (B8: nicht bedient)
0x03 = OC (Leitungsunterbrechung) (B8: nicht bedient)
0x04 = OOR+ (out of range high) ";
CM_ SG_ 1630 OBD_TG_Sens_Rohwert_1 "Rohwert des Tankgebers, nur gefiltert (gleitender Mittelwert), Ausgabe im 500ms-Raster";
CM_ SG_ 1630 OBD_TG_Sens_Rohwert_2 "Rohwert des Tankgebers, nur gefiltert (gleitender Mittelwert), Ausgabe im 500ms-Raster";
CM_ SG_ 1630 OBD_TG_Sens_Rohwert_3 "Rohwert des Tankgebers, nur gefiltert (gleitender Mittelwert), Ausgabe im 500ms-Raster";
CM_ SG_ 1630 OBD_TG_Sens_Rohwert_4 "Rohwert des Tankgebers, nur gefiltert (gleitender Mittelwert), Ausgabe im 500ms-Raster";
CM_ SG_ 1337 PCM_FOT_Temp "FOT-Temperatur PCM/Radio";
CM_ SG_ 1337 PCM_HMI_mode "Einstellung in der HMI des PCM fuer welche Einparksituation die Guidlines angezeigt werden sollen";
CM_ SG_ 1337 PCM_RFK_manuell "Manuelle Steuerung des RFK-SG von der PCM Headunit aus";
CM_ SG_ 1337 PCM_Rundenfarbe "Darstellungsfarbe Kuchendiagramm";
CM_ SG_ 1337 PCM_Limit_Info "LIMIT gemäss Kartenmaterial, in km/h bzw. mls/h";
CM_ SG_ 1337 PCM_Limit_Einheit "LIMIT-Einheit gemäss Kartenmaterial";
CM_ SG_ 1337 PCM_Rundenfortschritt "Kuchendiagramm Sportchrono: Position in der aktuellen Runde; Wert 240 entspricht 360° (Signalauflösung 1,5°)";
CM_ SG_ 1337 PCM_Kompass "Kompassinfo für Kombiinstrument und VTS.
0° = Nord; 90° = Ost; 180° = Süd; 270° = West 

";
CM_ SG_ 1337 PCM_Elev_Einheit "Einheit übertragene geografische Höhe in feet oder meter";
CM_ SG_ 1337 PCM_HMI_Mode_TopView "Setzen der Darstellungsvariante in PCM";
CM_ SG_ 1337 PCM_Street_class "Street Class (Vorhalt für VTS)
Maximal 16 Stufen, Zuordnung tbd.
";
CM_ SG_ 1337 PCM_Sat "Anzahl Satelliten (Vorhalt für VTS)
";
CM_ SG_ 1337 PCM_Entfernung_Kurve "Entfernung bis Kurve";
CM_ SG_ 1530 GPS_N_Grad "geografische Koordinate Breitengrad in Grad * 100 000 als signed integer 
-87,12345° entspricht der Zahl -8712345 
12345 sind Dezimalstellen 
Herkunft GPS-Empfänger
";
CM_ SG_ 1530 GPS_E_Grad "geografische Koordinate Längengrad in Grad * 100 000 als signed integer  
-177,12345° entspricht der Zahl -17712345 
12345 sind Dezimalstellen 
Herkunft GPS-Empfänger
";
CM_ SG_ 1530 GPS_elev "geografische Höhe in m -1000 oder in feet -1000 
(Offset 1000) 
Herkunft GPS-Empfänger 
Meter:Höhe=Wert-1000 
Feet:Höhe=(Wert-1000)*10 
Bei den Werten 8190 und 8191 dürfen die Empfänger keinen Fehler eintragen.";
CM_ SG_ 1707 PCM_Std "GPS-Zeit in Stunden
PCM-Signal, kein CDR-Signal";
CM_ SG_ 1707 PCM_Min "GPS-Zeit in Minuten
PCM-Signal, kein CDR-Signal";
CM_ SG_ 1707 PCM_Sek "GPS-Zeit in Sekunden
PCM-Signal, kein CDR-Signal";
CM_ SG_ 1707 PCM_Zeitzone "Das PCM sendet bei automatischer
Zeitzonenverstellung die anhand der GPSPosition
ermittelte Zeitzone. Ist keine
Zeitzoneninformation verfuegbar, sendet das
PCM den Fehlerwert 0x1F
PCM-Signal, kein CDR-Signal";
CM_ SG_ 1707 PCM_Zeitzone_Vorzeichen "Vorzeichen fuer die im Signal 'PCM_Zeitzone'
gesendete Zeitzoneninformation
PCM-Signal, kein CDR-Signal";
CM_ SG_ 1707 PCM_Uebern "Zeit im Kombi übernehmen
PCM-Signal, kein CDR-Signal";
CM_ SG_ 1707 PCM_Tag "Tag
PCM-Signal, kein CDR-Signal";
CM_ SG_ 1707 PCM_Mon "Monat
PCM-Signal, kein CDR-Signal";
CM_ SG_ 1707 PCM_JJ "Jahr
PCM-Signal, kein CDR-Signal";
CM_ SG_ 1707 PCM_Sommerzeit "Sommer oder Winterzeit";
CM_ SG_ 1707 PCM_Reset_Trip_1 "Reset Trip-Daten (fortlaufend)
PCM-Signal, kein CDR-Signal";
CM_ SG_ 1707 PCM_Reset_Trip_2 "Reset Trip-Daten (Kurzzeit)
PCM-Signal";
CM_ SG_ 1707 HU_Fotosensor "Messwert Fotosensor der Headunit (PCM bzw. CDR) 
logarithmisch verzerrt (siehe Funktionsbeschreibung Nachtdesign - entsprechend Audi-Spec)
PCM/CDR_Signal";
CM_ SG_ 1707 HU_SVB_AMP "Info vom PCM/CDR an das Gateway, welche MOST Komponenten verbaut sind.
PCM/CDR_Signal";
CM_ SG_ 1707 PCM_SVB_TV "Info vom PCM/CDR an das Gateway, welche MOST Komponenten verbaut sind.
PCM/CDR_Signal";
CM_ SG_ 1707 PCM_KD_Fehler_AMP "mind. 1 Kundendienstfehlerbit im Fehlerspeicher der MOST-Komponente 'Verstärker'
PCM/CDR_Signal";
CM_ SG_ 1707 PCM_KD_Fehler_TV "mind. 1 Kundendienstfehler im Fehlerspeicher der MOST-Kompomponente 'TV'
Hinweis: muss vom CDR konstant mir dem Wert 0 gesendet werden
PCM/CDR_Signal
";
CM_ SG_ 1707 HU_PCMCDR "Unterscheidung, ob CDR oder PCM verbaut ist.
d.h. das CDR muss konstant 0, das PCM konstant 1 senden.";
CM_ SG_ 1707 HU_Topview_on_Anf "Anforderung an PDC, das Signal 'PDC_Topview_on'=1 zu setzen
";
CM_ SG_ 1707 HU_KD_Fehler "1=mindestens ein Kundendienstfehlerspeicher Eintrag vorhanden";
CM_ SG_ 1339 QUER_Charisma_FahrPr "MLB: Aktuelles Fahrprogramm des Charisma-Teilnehmers (siehe Systemlastenheft Drive Select)
MQB: Istwert der Kennlinie (siehe Systemlastenheft MQB Charisma)


";
CM_ SG_ 1339 QUER_Charisma_Status "Systemstatus des Charismateilnehmers

Wert 0x3 ist nur für Fahrzeuge ab MQB relevant
";
CM_ SG_ 1339 QUER_Charisma_Umschaltung "Erkennung Umschaltaufforderung des Charisma-Teilnehmers";
CM_ SG_ 1339 QS_St_Begrenzungsmoment "Quersperre Status Begrenzungsmoment";
CM_ SG_ 1339 QS_Symbol_Rear_Lock "Anzeige von gelockter Quersperre im Offroad-Modus";
CM_ SG_ 1339 QS_Warntexte "Anzeige von Warn- oder Fehlermeldungen der geregelten Quersperre.";
CM_ BO_ 1611 "D4 RDK High auf dem KCAN";
CM_ SG_ 1611 RDK_System_Off "'RDK System Aus' Kombiwarnung  

Nur für Bentley relevant. Wird bei AUDI nicht verwendet.

";
CM_ SG_ 1611 RDK_Warnungen "Warnungen der RDK

0xE und 0xF  für Bentley";
CM_ SG_ 1611 RDK_FMVSS138_Lampe "Ansteuerung der RDK-Lampe im Kombi bei Druckwarnung";
CM_ SG_ 1611 RDK_Druckwarnung_RdW "Druckwarnung für RdW-Projekte, bei Druckverlust Prio1";
CM_ SG_ 1611 RDK_FMVSS138_MIL "Ansteuerung der RDK-Lampe im Kombi bei Systemstörung.
RDK-Lampe muss für 65 Sekunden blinken und anschliessend dauerhaft leuchten bis RDK dieses Bit wieder auf '0' setzt (Wiedergutprüfung).
Hinweis:  Im AU48x blinken für 60 Sekunden";
CM_ SG_ 1611 RDK_LF_aktiv "Synchronisation RDK Ansteuerung und Schlüsselsuchen
";
CM_ SG_ 1611 RDK_Diff_Druck_VL "Differenzdruck zwischen Ist- und Solldruck VL, normiert auf 20°C";
CM_ SG_ 1611 RDK_KD_Fehler "Bit wird nur bedient, wenn RDK am Komfort-CAN verbaut ist! Wenn RKA am Dashboard-CAN (im ESP) vorhanden ist, dann darf das KD-Bit vom ESP-Steuergerät nie mit 0x1 bedient, es muss immer mit Null gesendet werden. Gateway darf Signal zur Verbaukontrolle nur ";
CM_ SG_ 1611 RDK_Diff_Druck_VR "Differenzdruck zwischen Ist- und Solldruck VL, normiert auf 20°C";
CM_ SG_ 1611 RDK_Diff_Druck_HL "Differenzdruck zwischen Ist- und Solldruck HL, normiert auf 20°C";
CM_ SG_ 1611 RDK_Diff_Druck_HR "Differenzdruck zwischen Ist- und Solldruck HR, normiert auf 20°C";
CM_ SG_ 1652 RDK_W_1_Reifen_VL "Harte Warnung fuer Reifen vorne links";
CM_ SG_ 1652 RDK_W_2_Reifen_VL "Weiche Warnung fuer Reifen vorne links";
CM_ SG_ 1652 RDK_W_1_Reifen_VR "Harte Warnung fuer Reifen vorne rechts
";
CM_ SG_ 1652 RDK_W_2_Reifen_VR "Weiche Warnung fuer Reifen vorne rechts";
CM_ SG_ 1652 RDK_W_1_Reifen_HL "Harte Warnung fuer Reifen hinten links";
CM_ SG_ 1652 RDK_W_2_Reifen_HL "Weiche Warnung fuer Reifen hinten links";
CM_ SG_ 1652 RDK_W_1_Reifen_HR "Harte Warnung fuer Reifen hinten rechts";
CM_ SG_ 1652 RDK_W_2_Reifen_HR "Weiche Warnung fuer Reifen hinten rechts";
CM_ SG_ 1652 RDK_Warnung_1 "Rote Warnung, unspezifisch";
CM_ SG_ 1652 RDK_Warnung_2 "Gelbe Warnung, unspezifisch";
CM_ SG_ 1652 RDK_angelernt "RDK signalisiert, dass die Radelektroniken angelernt sind und das Kombi den Rundstreckenmodus anbieten kann.";
CM_ SG_ 1652 RDK_Solldr_uebern "RDK Solldruck übernommen";
CM_ SG_ 1652 RDK_Text_1 "Textausgabe 1: RDK wechselt in Zustand 'Teilueberwachung aktiv' (gewisse Raeder koennen aufgrund von Sensordefekt nicht ueberwacht werden.Die restlichen Raeder werden weiterhin ueberwacht)
";
CM_ SG_ 1652 RDK_Text_2 "Textausgabe 2: Ueberwachung nicht aktiv, System lernt
";
CM_ SG_ 1652 RDK_Text_3 "Textausgabe 3: RDK nicht aktiv
";
CM_ SG_ 1652 RDK_Text_4 "Textausgabe 4: RDK nicht aktiv, kurzzeitige Stoerung
";
CM_ SG_ 1652 RDK_Text_5 "Textausgabe 5: Reifendruck, Geschwindigkeit reduzieren
";
CM_ SG_ 1652 RDK_Text_6 "Textausgabe 6: Radwechsel, Einstellungen pruefen
";
CM_ SG_ 1652 RDK_W_3_Reifendr_erh "Kombi Anzeige 'Reifendruck für Vmax nicht geeignet' bzw. 'Komfortdruck max. 270km/h'";
CM_ SG_ 1651 RDK_Druck_VL_unkomp "Reifendruck vorne links unkompensiert für BC";
CM_ SG_ 1651 RDK_Druck_VR_unkomp "Reifendruck vorne rechts unkompensiert für BC
";
CM_ SG_ 1651 RDK_Druck_HL_unkomp "Reifendruck hinten links unkompensiert für BC
";
CM_ SG_ 1651 RDK_Druck_HR_unkomp "Reifendruck hinten rechts unkompensiert für BC

";
CM_ SG_ 1651 RDK_R_Temp_VL "Reifentemperatur vorne links";
CM_ SG_ 1651 RDK_R_Temp_VR "Reifentemperatur vorne rechts";
CM_ SG_ 1651 RDK_R_Temp_HL "Reifentemperatur hinten links
";
CM_ SG_ 1651 RDK_R_Temp_HR "Reifentemperatur hinten rechts

";
CM_ SG_ 1525 RW_RWDS_Lastprofil "Lastprofil zur Bestimmung der notwendigen Nachladeenergie (Reichweitendurchschnittstrom)";
CM_ SG_ 1525 RW_Gesamt_Reichweite "Reichweite für primär und sekundär Reichweite (eventuell Gewichtet)";
CM_ SG_ 1525 RW_Prim_Reichweitenverbrauch "Für primäre Reichweitenberechnung zugrunde gelegter Verbrauch";
CM_ SG_ 1525 RW_Prim_Reichweitenv_Einheit "Für primäre  Reichweitenberechnung (KBI_Prim_Reichweitenverbrauch) zugrunde gelegte Einheit";
CM_ SG_ 1525 RW_Primaer_Reichweite "Reichweite der primären Antriebsart";
CM_ SG_ 1527 RW_Sekundaer_Reichweite "Reichweite der sekundaeren Antriebsart";
CM_ SG_ 1527 RW_Sek_Reichweitenv_Einheit "Für sekundäre Reichweitenberechnung (KBI_Sek_Reichweitenverbrauch) zugrunde gelegte Einheit";
CM_ SG_ 1527 RW_Sek_Reichweitenverbrauch "Für sekundäre Reichweitenberechnung zugrunde gelegter Verbrauch";
CM_ BO_ 1504 "LIN-CAN (1:1) Botschaft wird geroutet:
- wenn entsprechender Slave codiert ist
- wenn fehlerfreie Kommunikation zum Slave besteht
- bei fehlerhafter Kommunikation zum Slave wird die Botschaft für 4s mit den letzten gültigen Werten versendet


";
CM_ SG_ 1504 MD1_Position "Schiebedachstellung 1 (Signal wird 1:1 vom BCM2 geroutet; ursprünglicher Sender: SAD = LIN-Slave vom BCM2)
";
CM_ SG_ 1504 MD1_Lage "Lage Schiebedachstellung 1 (Signal wird 1:1 vom BCM2 geroutet; ursprünglicher Sender: SAD = LIN-Slave vom BCM2)";
CM_ SG_ 1504 MD3_Position "Schiebedachstellung 3 
(Signal wird 1:1 vom BCM2 geroutet; ursprünglicher Sender: SAD = LIN-Slave vom BCM2)
";
CM_ SG_ 1504 MD3_Lage "Lage Schiebedachstellung 3 
(Signal wird 1:1 vom BCM2 geroutet; ursprünglicher Sender: SAD = LIN-Slave vom BCM2) 
";
CM_ SG_ 1504 MRollo_Position "Schiebedachstellung Rollo
(Signal wird 1:1 vom BCM2 geroutet; ursprünglicher Sender: Rollo = LIN-Slave vom BCM2)";
CM_ SG_ 1504 MRollo_Lage "Lage Rollo
(Signal wird 1:1 vom BCM2 geroutet; ursprünglicher Sender: Rollo = LIN-Slave vom BCM2)";
CM_ SG_ 1413 SI_Int_CAN_gespiegelt "Nutzdaten eines internen CAN-Netzwerks (z. B. Antrieb) werden  auf den Diagnose-CAN gespiegelt (Mirror-Mode aktiviert)";
CM_ SG_ 1413 SI_CAN_Komfort_Sleep "CAN-Komfort-Netzwerk (KCAN) schläft (Status des NM)
";
CM_ SG_ 1413 SI_CAN_Dashboard_Sleep "CAN-Dashboard-Netzwerk (DCAN) schläft (Status des NM)
";
CM_ SG_ 1413 SI_CAN_Antrieb_Sleep "CAN-Antrieb-Netzwerk (ACAN) schläft (Status des NM)
";
CM_ SG_ 1413 SI_Infotainment_Sleep "Infotainment-Netzwerk (CAN/MOST) schläft (Status des NM)
";
CM_ SG_ 1413 SI_CAN_Extended_Sleep "CAN-Extended-Netzwerk (ECAN) schläft (Status des NM)
";
CM_ SG_ 1413 SI_Fahrwerk_Sleep "Fahrwerk-Netzwerk (CAN/FR) schläft (Status des NM)
";
CM_ SG_ 1413 SI_Diagnose_Aktiv "Gibt an ob Diagnose-Botschaften empfangen werden und somit eine Diagnose aktiv ist";
CM_ SG_ 1413 SI_T_Mode "0x0: Transportmodus nicht aktiv
0x1: Transportmodus aktiv";
CM_ SG_ 1413 SI_NWDF "Netzwerk-Diagnose Freigebe zur zentralen Aktivierung der Netzwerkdiagnose";
CM_ SG_ 1413 SI_NWDF_gueltig "Gültigkeitsbit zu SI_NWDF gemäß Lastenheft: Zentrale Aktivierung Netzwerkdiagnose";
CM_ SG_ 1413 SI_Sammelfehler "Sammelfehlermeldung zur Anzeige im Kombi - siehe Spez. Sammelfehlermeldung
Hinweis: Einzelne Steuergeräte können zur Anpassung an den Produktionsprozess im Gateway auskodiert werden!";
CM_ SG_ 1413 GW_KD_Fehler "Kundendienstfehlerbit Gateway zur Anzeige eines im Gateway abgelegten Fehlerspeichereintrages.";
CM_ SG_ 1413 SI_T_Schutz "Transportschutz-Signal, das bei Transportmodus und Motorlauf aktiv bleibt
0x0: Transportschutz nicht aktiv
0x1: Transportschutz aktiv";
CM_ SG_ 1413 SI_MOST_Status "Das Signal gibt den Zustand des MOST wieder.";
CM_ SG_ 1413 SI_Sammel_SG_Fehler "Anzahl der gesetzten KD-Fehler direkt angeschlossener Steuergeräte der DK3 und DK4 gemäß 80127.
Hinweis: Ein Subbusmaster stellt nur die gesammelte Information der an ihn angeschlossenen Steuergeräte der DK3 und DK4 zur Verfügung.

Für ServiceKey Auswe";
CM_ SG_ 1413 SI_MO_WU "Bit ans BCM2 zum Wecken des MSG MED9 im AUDI B8";
CM_ SG_ 786 TSK_03_CHK "Berechnung siehe Lastenheft 'Kommunikationsabsicherung für FlexRay und CAN'
Endwerte siehe 'Kommunikationsabsicherung für FlexRay und CAN / Anhang C: Tabelle S-PDU Kennungen'";
CM_ SG_ 786 FAS_Wunschgeschw "Zur Anzeige der Wunschgeschwindigkeit im Kombiinstrument";
CM_ SG_ 786 FAS_Status_Prim_Anz "Ansteuerung einer primären Statusanzeige für ACC/GRA in verschiedenen Farben";
CM_ SG_ 786 FAS_Texte_Primaeranz "Weitere Textdefinitionen im DBC-File!";
CM_ SG_ 786 FAS_Status_Anzeige "Analog zum Status nur zur Defintion von Anzeige im Kombi. Hinweis: Wird für die spez. VW-Anzeige (überlappende Anzeigebereiche) verwendet. Vom AUDI-ACC im Rahmen der Modulstrategie zu bedienen.
";
CM_ SG_ 1718 UH_Typ "0x4 - 0x7 = tbd. ";
CM_ SG_ 1718 UH_Monat "0x0D, 0xF =  Werte ungültig
0x0E = reserviert (nur VW)";
CM_ SG_ 1718 UH_Tag "0x0: reserviert bei VW";
CM_ SG_ 1718 UH_Stunde "0x18 - 0x1F = Werte ungültig";
CM_ SG_ 1718 UH_Minute "0x3C- 0x3f = Werte ungültig";
CM_ SG_ 1718 UH_Sekunde "0x3C- 0x3f = Werte ungültig";
CM_ BO_ 1716 "200ms bei D4 und folgende";
CM_ SG_ 1716 VIN_01_MUX "Achtung:
Die Botschaft ist nicht linear gemultiplext!!!
Sondern 0,1,0,2,0, usw.";
CM_ SG_ 1716 VIN_4 "Initwert:
0x2D bei Fahrzeugen mit Wegfahrsperrengeneration >= 5 
0x58 bei Fahrzeugen mit Wegfahrsperrengeneration < 5 (z.B. WFS-4)";
CM_ SG_ 1716 VIN_11 "Initwert:
0x2D bei Fahrzeugen mit Wegfahrsperrengeneration >= 5 
0x58 bei Fahrzeugen mit Wegfahrsperrengeneration < 5 (z.B. WFS-4)";
CM_ SG_ 1716 VIN_5 "Initwert:
0x2D bei Fahrzeugen mit Wegfahrsperrengeneration >= 5 
0x58 bei Fahrzeugen mit Wegfahrsperrengeneration < 5 (z.B. WFS-4)";
CM_ SG_ 1716 VIN_12 "Initwert:
0x2D bei Fahrzeugen mit Wegfahrsperrengeneration >= 5 
0x58 bei Fahrzeugen mit Wegfahrsperrengeneration < 5 (z.B. WFS-4)";
CM_ SG_ 1716 VIN_6 "Initwert:
0x2D bei Fahrzeugen mit Wegfahrsperrengeneration >= 5 
0x58 bei Fahrzeugen mit Wegfahrsperrengeneration < 5 (z.B. WFS-4)";
CM_ SG_ 1716 VIN_13 "Initwert:
0x2D bei Fahrzeugen mit Wegfahrsperrengeneration >= 5 
0x58 bei Fahrzeugen mit Wegfahrsperrengeneration < 5 (z.B. WFS-4)";
CM_ SG_ 1716 VIN_7 "Initwert:
0x2D bei Fahrzeugen mit Wegfahrsperrengeneration >= 5 
0x58 bei Fahrzeugen mit Wegfahrsperrengeneration < 5 (z.B. WFS-4)";
CM_ SG_ 1716 VIN_14 "Initwert:
0x2D bei Fahrzeugen mit Wegfahrsperrengeneration >= 5 
0x58 bei Fahrzeugen mit Wegfahrsperrengeneration < 5 (z.B. WFS-4)";
CM_ SG_ 1716 VIN_1 "Initwert:
0x2D bei Fahrzeugen mit Wegfahrsperrengeneration >= 5 
0x58 bei Fahrzeugen mit Wegfahrsperrengeneration < 5 (z.B. WFS-4)";
CM_ SG_ 1716 VIN_8 "Initwert:
0x2D bei Fahrzeugen mit Wegfahrsperrengeneration >= 5 
0x58 bei Fahrzeugen mit Wegfahrsperrengeneration < 5 (z.B. WFS-4)";
CM_ SG_ 1716 VIN_15 "Initwert:
0x2D bei Fahrzeugen mit Wegfahrsperrengeneration >= 5 
0x58 bei Fahrzeugen mit Wegfahrsperrengeneration < 5 (z.B. WFS-4)";
CM_ SG_ 1716 VIN_2 "Initwert:
0x2D bei Fahrzeugen mit Wegfahrsperrengeneration >= 5 
0x58 bei Fahrzeugen mit Wegfahrsperrengeneration < 5 (z.B. WFS-4)";
CM_ SG_ 1716 VIN_9 "Initwert:
0x2D bei Fahrzeugen mit Wegfahrsperrengeneration >= 5 
0x58 bei Fahrzeugen mit Wegfahrsperrengeneration < 5 (z.B. WFS-4)";
CM_ SG_ 1716 VIN_16 "Initwert:
0x2D bei Fahrzeugen mit Wegfahrsperrengeneration >= 5 
0x58 bei Fahrzeugen mit Wegfahrsperrengeneration < 5 (z.B. WFS-4)";
CM_ SG_ 1716 VIN_3 "Initwert:
0x2D bei Fahrzeugen mit Wegfahrsperrengeneration >= 5 
0x58 bei Fahrzeugen mit Wegfahrsperrengeneration < 5 (z.B. WFS-4)";
CM_ SG_ 1716 VIN_10 "Initwert:
0x2D bei Fahrzeugen mit Wegfahrsperrengeneration >= 5 
0x58 bei Fahrzeugen mit Wegfahrsperrengeneration < 5 (z.B. WFS-4)";
CM_ SG_ 1716 VIN_17 "Initwert:
0x2D bei Fahrzeugen mit Wegfahrsperrengeneration >= 5 
0x58 bei Fahrzeugen mit Wegfahrsperrengeneration < 5 (z.B. WFS-4)";
CM_ SG_ 915 WBA_02_CHK "Berechnung siehe Lastenheft 'Kommunikationsabsicherung für FlexRay und CAN'
Endwerte siehe 'Kommunikationsabsicherung für FlexRay und CAN / Anhang C: Tabelle S-PDU Kennungen'";
CM_ SG_ 915 WBA_Senderkennung "Die Botschaft WBA_02 wird vom Automatgetriebe gesendet, bei Handschaltern alternativ vom Motor. Das Getriebe stellt damit die Wählbereichsanzeige dar, der Motor beim Handschalter die Hochschaltaufforderung für den Fahrer im Kombi. Zur Unterscheidung des S";
CM_ SG_ 915 WBA_Lampe_Shift_Lock "Im Kombi wird Anzeige im Mitteldisplay geschaltet: 'Zum Einlegen einer Fahrstufe bitte Bremse betätigen' - nur falls WBA_Senderkennung = 00 (GSG)

";
CM_ SG_ 915 WBA_Schaltempf_verfbar "Info, ob Schaltempfehlung im Fzg. verfügbar. Statischer Wert, ändert sich für ein Fzg nicht - nur falls WBA_Senderkennung = 01 (MSG)";
CM_ SG_ 915 WBA_Effizienzmodus "Bei Handschaltern wird  das Fahrprogramm Effizienz signalisiert. 
Bei Automatikgetrieben wird das Fahrprogramm 'D' durch 'E' ersetzt.";
CM_ SG_ 915 WBA_Blinken "Dieses Bit steuert die Fehlerlampe an oder wird zum Blinken der WBA-Anzeige genutzt - nur falls WBA_Senderkennung = 00 (GSG)
";
CM_ SG_ 915 WBA_Getriebevariante "Verwendete Getriebe-Variante im Fahrzeug, Kombi stellt entsprechende WBA dar (bspw. PRNDS). Nur falls WBA_Senderkennung = 00 (GSG).
";
CM_ SG_ 915 WBA_GE_Warnung "Prioritaetswarnungen Getriebe mit Shift by wire
Werte 6 und 7 werden seitens Audi nicht bedient";
CM_ SG_ 915 WBA_Fahrstufe "Bei Automatgetrieben wird in diesem Signal die aktuelle Fahrstufe (=Wählhebelposition) ausgegeben. Nur falls WBA_Senderkennung = 00 (GSG):

Im Automatik-Betrieb:
0x0 = Zwischenstellung, keine Position  (Normaldarstellung aller Fahrstufen)
0x1 = Getrie";
CM_ SG_ 915 WBA_Istgang "Wenn Motor die WBA-Botschaft sendet wird in diesem Signal der aktuelle Gang ausgegeben (= Istgang des Schaltgetriebes). Nur falls WBA_Senderkennung = 01 (MSG).

0x7 - 0xF = tbd.

Anzeige im Kombi:
Sollgang == Istgang         ==> Anzeige Istgang
Soll";
CM_ SG_ 915 WBA_eing_Gang "Das Automatgetriebe gibt den aktuell eingelegten Gang aus. Nur falls WBA_Senderkennung = 00 (GSG)

0xB - 0xF = tbd.";
CM_ SG_ 915 WBA_Sollgang "Motor sendet den Sollgang in den der Fahrer schalten soll. Wird im Kombi als Hochschaltempfehlung hervorgehoben. Nur falls WBA_Senderkennung = 01 (MSG)

0x7 - 0xF = tbd.

Anzeige im Kombi:
Sollgang == Istgang          ==> Anzeige Istgang
Sollgang !=";
CM_ SG_ 915 WBA_GE_Texte "Fahrerhinweise für das Kombi";
CM_ SG_ 915 WBA_Schaltschema_Aktiv "Anforderung Getriebe zur Anzeige des Schaltschemas im Kombi";
CM_ SG_ 915 WH_Warnung "Warntexte vom Waehlhebel";
CM_ SG_ 915 WBA_GE_Zusatzwarnungen "Prioritaetswarnungen Getriebe an Kombi
Audi MLB Wertebereich 0 bis 3
VW MQB Projekte verwenden nur den Wertebereich 0 bis 2
VW MQB Getriebefehler werden über das Signal  GE_Warnungen_02 gesendet.";
CM_ SG_ 915 GE_Tipschaltempf_verfuegbar "Signalisierung, ob eine Hochschaltempfehlung im Tipmodus verfügbar ist oder nicht.";
CM_ SG_ 915 GE_Sollgang "Signalisiert den Sollgang, in den getippt werden soll. Abhängig vom Signal 'WBA_eing_Gang_02' und dem Sollgang kann dann das Kombi die Hochschaltempfehlung in Tip darstellen.";
CM_ SG_ 1702 Wischer_vorne_aktiv "Status: Wischer vorne ";
CM_ SG_ 1702 Waschen_vorne_aktiv "Status: Waschen vorne aktiv 
";
CM_ SG_ 1702 Wischer_vorne_Normal "Wischer Front normal aktiv";
CM_ SG_ 1702 Wischer_vorne_Schnell "Wischer vorne schnell aktiv";
CM_ SG_ 1702 Wischer_vorne_Parklage "Wischer Front in Parklage";
CM_ SG_ 1702 WWSs_01_alt "Veraltet Bit für die LIN-Botschaft WWSs_01.

Betroffene Signale:

Wischer_vorne_aktiv
";
CM_ SG_ 1702 Wischer_vorne_defekt "Fehlerstatus Wischer vorne (Anzeige im Kombi)";
CM_ SG_ 1702 Wischer_vorne_blockiert "Blockade Wischer vorne (z.B. durch Schnee)";
CM_ SG_ 1702 Wischer1_Wischgeschwindigkeit "aktuelle, durch Sensorik gemessene Wischgeschwindigkeit";
CM_ SG_ 1702 BCM1_SRA_aktiv "Status Scheinwerferreinigungsanlage";
CM_ SG_ 1602 WIV_Verschleissindex "Bei Otto Verbrauch, bei Diesel Verschleiss";
CM_ SG_ 1602 WIV_Russindex "Nur für Diesel, Rußwert, bei Otto Wert = 0";
CM_ SG_ 1602 WIV_t_min "Minimales Wartungsintervall für WIV in Monaten";
CM_ SG_ 1602 WIV_t_max "Maximales Wartungsintervall für WIV in Monaten";
CM_ SG_ 1602 WIV_W_min "Minimales Wartungsintervall für WIV in km";
CM_ SG_ 1602 WIV_W_max "Maximales Wartungsintervall für WIV in km";
BA_DEF_ BO_  "DiagRequest" ENUM  "No","Yes";
BA_DEF_ BO_  "DiagResponse" ENUM  "No","Yes";
BA_DEF_ BO_  "DiagState" ENUM  "No","Yes";
BA_DEF_ BO_  "GenMsgChkConstant" HEX 0 4095;
BA_DEF_ BO_  "GenMsgCycleTime" INT 0 65535;
BA_DEF_ BO_  "GenMsgCycleTimeFast" INT 0 65535;
BA_DEF_ BO_  "GenMsgDelayTime" INT 0 100000;
BA_DEF_ BO_  "GenMsgILSupport" ENUM  "No","Yes";
BA_DEF_ BO_  "GenMsgNrOfRepetition" INT 0 100;
BA_DEF_ BO_  "GenMsgPDUConstants" STRING ;
BA_DEF_ BO_  "GenMsgSendType" ENUM  "Cyclic","not_used","not_used","not_used","not_used","not_used","not_used","IfActive","NoMsgSendType";
BA_DEF_ BO_  "GenMsgStartDelayTime" INT 0 100000;
BA_DEF_ BO_  "NmMessage" ENUM  "No","Yes";
BA_DEF_ BO_  "NmhMessage" ENUM  "No","Yes";
BA_DEF_ BO_  "MsgType" ENUM  "Application","NM ","NMH","TP2.0","ISO-TP ","BAP","EID";
BA_DEF_ BO_  "VAGTP20_API" HEX 0 255;
BA_DEF_ BO_  "VAGTP20_DynConnection" ENUM  "No","Yes";
BA_DEF_ BO_  "VAGTP20_DynSetup" ENUM  "No","Yes";
BA_DEF_ BO_  "VAGTP20_StatConnection" ENUM  "No","Yes";
BA_DEF_ SG_  "GenSigActiveRepetitions" INT -2147483648 2147483647;
BA_DEF_ SG_  "GenSigInactiveValue" INT -2147483648 2147483647;
BA_DEF_ SG_  "GenSigSendType" ENUM  "Cyclic","OnWrite","OnWriteWithRepetition","OnChange","OnChangeWithRepetition","IfActive","IfActiveWithRepetition","NoSigSendType","OnChangeAndIfActive","OnChangeAndIfActiveWithRepetition";
BA_DEF_ SG_  "GenSigStartValue" INT -2147483648 2147483647;
BA_DEF_ SG_  "NWM-WakeupAllowed" ENUM  "No","Yes";
BA_DEF_ SG_  "GenSigFuncType" ENUM  "NoFunction","MsgCounter","CRC-8","XOR","XOR-2","DatedBit","SW-Kl15","CHK","Constant","Protocol","CRC-8-SAE_J1850";
BA_DEF_ SG_  "GenSigSwitchedByIgnition" ENUM  "No","Yes";
BA_DEF_ SG_  "Fehlerwert" HEX 0 2147483647;
BA_DEF_ SG_  "GenSigMissingSourceValue" HEX 0 2147483647;
BA_DEF_REL_ BU_SG_REL_  "GenSigTimeoutTime" INT 0 65535;
BA_DEF_DEF_REL_ "GenSigTimeoutTime" 0;
BA_DEF_DEF_  "DiagRequest" "No";
BA_DEF_DEF_  "DiagResponse" "No";
BA_DEF_DEF_  "DiagState" "No";
BA_DEF_DEF_  "GenMsgChkConstant" 0;
BA_DEF_DEF_  "GenMsgCycleTime" 0;
BA_DEF_DEF_  "GenMsgCycleTimeFast" 0;
BA_DEF_DEF_  "GenMsgDelayTime" 0;
BA_DEF_DEF_  "GenMsgILSupport" "No";
BA_DEF_DEF_  "GenMsgNrOfRepetition" 0;
BA_DEF_DEF_  "GenMsgPDUConstants" "";
BA_DEF_DEF_  "GenMsgSendType" "NoMsgSendType";
BA_DEF_DEF_  "GenMsgStartDelayTime" 0;
BA_DEF_DEF_  "NmMessage" "No";
BA_DEF_DEF_  "NmhMessage" "No";
BA_DEF_DEF_  "MsgType" "Application";
BA_DEF_DEF_  "VAGTP20_API" 0;
BA_DEF_DEF_  "VAGTP20_DynConnection" "No";
BA_DEF_DEF_  "VAGTP20_DynSetup" "No";
BA_DEF_DEF_  "VAGTP20_StatConnection" "No";
BA_DEF_DEF_  "GenSigActiveRepetitions" 0;
BA_DEF_DEF_  "GenSigInactiveValue" 0;
BA_DEF_DEF_  "GenSigSendType" "NoSigSendType";
BA_DEF_DEF_  "GenSigStartValue" 0;
BA_DEF_DEF_  "NWM-WakeupAllowed" "No";
BA_DEF_DEF_  "GenSigFuncType" "NoFunction";
BA_DEF_DEF_  "GenSigSwitchedByIgnition" "Yes";
BA_DEF_DEF_  "Fehlerwert" 0;
BA_DEF_DEF_  "GenSigMissingSourceValue" 0;
BA_ "GenMsgSendType" BO_ 391 0;
BA_ "GenMsgILSupport" BO_ 391 1;
BA_ "GenMsgDelayTime" BO_ 391 40;
BA_ "GenMsgCycleTime" BO_ 391 100;
BA_ "GenMsgSendType" BO_ 811 0;
BA_ "GenMsgILSupport" BO_ 811 1;
BA_ "GenMsgCycleTime" BO_ 811 50;
BA_ "GenMsgSendType" BO_ 305 0;
BA_ "GenMsgILSupport" BO_ 305 1;
BA_ "GenMsgCycleTime" BO_ 305 20;
BA_ "GenMsgSendType" BO_ 931 0;
BA_ "GenMsgILSupport" BO_ 931 1;
BA_ "GenMsgCycleTime" BO_ 931 100;
BA_ "GenMsgChkConstant" BO_ 931 129;
BA_ "MsgType" BO_ 1747 2;
BA_ "NmhMessage" BO_ 1747 1;
BA_ "GenMsgCycleTime" BO_ 1747 200;
BA_ "MsgType" BO_ 1728 2;
BA_ "NmhMessage" BO_ 1728 1;
BA_ "GenMsgCycleTime" BO_ 1728 200;
BA_ "MsgType" BO_ 1775 2;
BA_ "NmhMessage" BO_ 1775 1;
BA_ "GenMsgCycleTime" BO_ 1775 200;
BA_ "MsgType" BO_ 1772 2;
BA_ "NmhMessage" BO_ 1772 1;
BA_ "GenMsgCycleTime" BO_ 1772 200;
BA_ "MsgType" BO_ 1735 2;
BA_ "NmhMessage" BO_ 1735 1;
BA_ "GenMsgCycleTime" BO_ 1735 200;
BA_ "MsgType" BO_ 1750 2;
BA_ "NmhMessage" BO_ 1750 1;
BA_ "GenMsgCycleTime" BO_ 1750 200;
BA_ "MsgType" BO_ 1774 2;
BA_ "NmhMessage" BO_ 1774 1;
BA_ "GenMsgCycleTime" BO_ 1774 200;
BA_ "GenMsgSendType" BO_ 1156 0;
BA_ "GenMsgILSupport" BO_ 1156 1;
BA_ "GenMsgCycleTime" BO_ 1156 500;
BA_ "GenMsgSendType" BO_ 1630 0;
BA_ "GenMsgILSupport" BO_ 1630 1;
BA_ "GenMsgCycleTime" BO_ 1630 500;
BA_ "GenMsgSendType" BO_ 1337 0;
BA_ "GenMsgILSupport" BO_ 1337 1;
BA_ "GenMsgCycleTime" BO_ 1337 250;
BA_ "GenMsgSendType" BO_ 1530 0;
BA_ "GenMsgILSupport" BO_ 1530 1;
BA_ "GenMsgCycleTime" BO_ 1530 1000;
BA_ "GenMsgSendType" BO_ 1707 0;
BA_ "GenMsgILSupport" BO_ 1707 1;
BA_ "GenMsgDelayTime" BO_ 1707 20;
BA_ "GenMsgCycleTime" BO_ 1707 200;
BA_ "GenMsgSendType" BO_ 1339 0;
BA_ "GenMsgILSupport" BO_ 1339 1;
BA_ "GenMsgDelayTime" BO_ 1339 50;
BA_ "GenMsgCycleTime" BO_ 1339 500;
BA_ "GenMsgSendType" BO_ 1611 0;
BA_ "GenMsgILSupport" BO_ 1611 1;
BA_ "GenMsgCycleTime" BO_ 1611 500;
BA_ "GenMsgSendType" BO_ 1652 0;
BA_ "GenMsgILSupport" BO_ 1652 1;
BA_ "GenMsgDelayTime" BO_ 1652 80;
BA_ "GenMsgCycleTime" BO_ 1652 800;
BA_ "GenMsgSendType" BO_ 1651 0;
BA_ "GenMsgILSupport" BO_ 1651 1;
BA_ "GenMsgDelayTime" BO_ 1651 80;
BA_ "GenMsgCycleTime" BO_ 1651 800;
BA_ "GenMsgSendType" BO_ 1525 0;
BA_ "GenMsgILSupport" BO_ 1525 1;
BA_ "GenMsgCycleTime" BO_ 1525 1000;
BA_ "GenMsgSendType" BO_ 1527 0;
BA_ "GenMsgILSupport" BO_ 1527 1;
BA_ "GenMsgCycleTime" BO_ 1527 1000;
BA_ "GenMsgSendType" BO_ 1504 0;
BA_ "GenMsgILSupport" BO_ 1504 1;
BA_ "GenMsgCycleTime" BO_ 1504 500;
BA_ "GenMsgSendType" BO_ 1413 0;
BA_ "GenMsgILSupport" BO_ 1413 1;
BA_ "GenMsgDelayTime" BO_ 1413 10;
BA_ "GenMsgCycleTime" BO_ 1413 1000;
BA_ "GenMsgSendType" BO_ 786 0;
BA_ "GenMsgILSupport" BO_ 786 1;
BA_ "GenMsgDelayTime" BO_ 786 10;
BA_ "GenMsgCycleTime" BO_ 786 50;
BA_ "GenMsgChkConstant" BO_ 786 17;
BA_ "GenMsgSendType" BO_ 1718 0;
BA_ "GenMsgILSupport" BO_ 1718 1;
BA_ "GenMsgCycleTime" BO_ 1718 1000;
BA_ "GenMsgSendType" BO_ 1716 0;
BA_ "GenMsgILSupport" BO_ 1716 1;
BA_ "GenMsgCycleTime" BO_ 1716 200;
BA_ "GenMsgSendType" BO_ 915 0;
BA_ "GenMsgILSupport" BO_ 915 1;
BA_ "GenMsgDelayTime" BO_ 915 10;
BA_ "GenMsgCycleTime" BO_ 915 80;
BA_ "GenMsgChkConstant" BO_ 915 144;
BA_ "GenMsgSendType" BO_ 1702 0;
BA_ "GenMsgILSupport" BO_ 1702 1;
BA_ "GenMsgDelayTime" BO_ 1702 50;
BA_ "GenMsgCycleTime" BO_ 1702 1000;
BA_ "GenMsgSendType" BO_ 1602 0;
BA_ "GenMsgILSupport" BO_ 1602 1;
BA_ "GenMsgDelayTime" BO_ 1602 200;
BA_ "GenMsgCycleTime" BO_ 1602 2000;
BA_ "GenSigSwitchedByIgnition" SG_ 391 EV_Rekuperationsstufe 0;
BA_ "GenSigSendType" SG_ 391 EV_Rekuperationsstufe 0;
BA_ "GenSigSwitchedByIgnition" SG_ 391 HV_Bordnetz_aktiv 0;
BA_ "GenSigSendType" SG_ 391 HV_Bordnetz_aktiv 0;
BA_ "Fehlerwert" SG_ 391 MO_Waehlpos 7;
BA_ "GenSigSwitchedByIgnition" SG_ 391 MO_Waehlpos 0;
BA_ "GenSigSendType" SG_ 391 MO_Waehlpos 0;
BA_ "GenSigSwitchedByIgnition" SG_ 391 MO_Tankbereitschaft_Status 0;
BA_ "GenSigSendType" SG_ 391 MO_Tankbereitschaft_Status 0;
BA_ "GenSigSwitchedByIgnition" SG_ 391 MO_Tankklappensteuerung 0;
BA_ "GenSigSendType" SG_ 391 MO_Tankklappensteuerung 0;
BA_ "GenSigSwitchedByIgnition" SG_ 391 MO_HVEM_Eskalation 0;
BA_ "GenSigSendType" SG_ 391 MO_HVEM_Eskalation 3;
BA_ "Fehlerwert" SG_ 391 MO_HVEM_MaxLeistung 511;
BA_ "GenSigSwitchedByIgnition" SG_ 391 MO_HVEM_MaxLeistung 0;
BA_ "GenSigStartValue" SG_ 391 MO_HVEM_MaxLeistung 510;
BA_ "GenSigSendType" SG_ 391 MO_HVEM_MaxLeistung 0;
BA_ "GenSigSwitchedByIgnition" SG_ 811 MO_HYB_E_Faktor 0;
BA_ "GenSigSendType" SG_ 811 MO_HYB_E_Faktor 0;
BA_ "Fehlerwert" SG_ 811 MO_HYB_Drehzahl_VM 65280;
BA_ "GenSigSwitchedByIgnition" SG_ 811 MO_HYB_Drehzahl_VM 0;
BA_ "GenSigSendType" SG_ 811 MO_HYB_Drehzahl_VM 0;
BA_ "GenSigSwitchedByIgnition" SG_ 811 MO_HYB_LowSpeedModus 0;
BA_ "GenSigSendType" SG_ 811 MO_HYB_LowSpeedModus 0;
BA_ "GenSigSwitchedByIgnition" SG_ 811 MO_FahrPr1_verfuegbar 0;
BA_ "GenSigSendType" SG_ 811 MO_FahrPr1_verfuegbar 0;
BA_ "GenSigSwitchedByIgnition" SG_ 811 MO_FahrPr2_verfuegbar 0;
BA_ "GenSigSendType" SG_ 811 MO_FahrPr2_verfuegbar 0;
BA_ "GenSigSwitchedByIgnition" SG_ 811 MO_FahrPr3_verfuegbar 0;
BA_ "GenSigSendType" SG_ 811 MO_FahrPr3_verfuegbar 0;
BA_ "GenSigSwitchedByIgnition" SG_ 811 MO_FahrPr4_verfuegbar 0;
BA_ "GenSigSendType" SG_ 811 MO_FahrPr4_verfuegbar 0;
BA_ "GenSigSwitchedByIgnition" SG_ 811 MO_FahrPr5_verfuegbar 0;
BA_ "GenSigSendType" SG_ 811 MO_FahrPr5_verfuegbar 0;
BA_ "GenSigSwitchedByIgnition" SG_ 811 MO_FahrPr6_verfuegbar 0;
BA_ "GenSigSendType" SG_ 811 MO_FahrPr6_verfuegbar 0;
BA_ "GenSigSwitchedByIgnition" SG_ 811 MO_FahrPr7_verfuegbar 0;
BA_ "GenSigSendType" SG_ 811 MO_FahrPr7_verfuegbar 0;
BA_ "GenSigSwitchedByIgnition" SG_ 305 MO_ePowermeter 0;
BA_ "GenSigSendType" SG_ 305 MO_ePowermeter 0;
BA_ "GenSigSwitchedByIgnition" SG_ 305 MO_W_Reku_normiert_ueberlauf 0;
BA_ "GenSigSendType" SG_ 305 MO_W_Reku_normiert_ueberlauf 0;
BA_ "Fehlerwert" SG_ 305 Ladezustand 255;
BA_ "GenSigSwitchedByIgnition" SG_ 305 Ladezustand 0;
BA_ "GenSigSendType" SG_ 305 Ladezustand 0;
BA_ "Fehlerwert" SG_ 305 Enrgfluss_State 255;
BA_ "GenSigSwitchedByIgnition" SG_ 305 Enrgfluss_State 0;
BA_ "GenSigSendType" SG_ 305 Enrgfluss_State 0;
BA_ "GenSigSwitchedByIgnition" SG_ 305 MO_W_Reku_normiert 0;
BA_ "GenSigSendType" SG_ 305 MO_W_Reku_normiert 0;
BA_ "GenSigSwitchedByIgnition" SG_ 305 MO_Powermeter 0;
BA_ "GenSigStartValue" SG_ 305 MO_Powermeter 4093;
BA_ "GenSigSendType" SG_ 305 MO_Powermeter 0;
BA_ "GenSigSwitchedByIgnition" SG_ 931 Motor_02_CHK 0;
BA_ "GenSigFuncType" SG_ 931 Motor_02_CHK 4;
BA_ "GenSigSendType" SG_ 931 Motor_02_CHK 0;
BA_ "GenSigSwitchedByIgnition" SG_ 931 Motor_02_BZ 0;
BA_ "GenSigFuncType" SG_ 931 Motor_02_BZ 1;
BA_ "GenSigSendType" SG_ 931 Motor_02_BZ 0;
BA_ "Fehlerwert" SG_ 931 MO_Mom_ZWR 1023;
BA_ "GenSigSwitchedByIgnition" SG_ 931 MO_Mom_ZWR 0;
BA_ "GenSigStartValue" SG_ 931 MO_Mom_ZWR 1022;
BA_ "GenSigSendType" SG_ 931 MO_Mom_ZWR 0;
BA_ "Fehlerwert" SG_ 931 MO_Mom_Soll 1023;
BA_ "GenSigSwitchedByIgnition" SG_ 931 MO_Mom_Soll 0;
BA_ "GenSigStartValue" SG_ 931 MO_Mom_Soll 1022;
BA_ "GenSigSendType" SG_ 931 MO_Mom_Soll 0;
BA_ "Fehlerwert" SG_ 931 MO_Mom_Ist 1023;
BA_ "GenSigSwitchedByIgnition" SG_ 931 MO_Mom_Ist 0;
BA_ "GenSigStartValue" SG_ 931 MO_Mom_Ist 1022;
BA_ "GenSigSendType" SG_ 931 MO_Mom_Ist 0;
BA_ "GenSigSwitchedByIgnition" SG_ 931 MO_Status_Zylabschalt_01 0;
BA_ "GenSigSendType" SG_ 931 MO_Status_Zylabschalt_01 0;
BA_ "GenSigSwitchedByIgnition" SG_ 931 MO_Status_Normalbetrieb_01 0;
BA_ "GenSigSendType" SG_ 931 MO_Status_Normalbetrieb_01 0;
BA_ "GenSigSwitchedByIgnition" SG_ 931 MO_StartStopp_Status 0;
BA_ "GenSigSendType" SG_ 931 MO_StartStopp_Status 0;
BA_ "GenSigSwitchedByIgnition" SG_ 931 MO_StartStopp_Motorstopp 0;
BA_ "GenSigSendType" SG_ 931 MO_StartStopp_Motorstopp 0;
BA_ "GenSigSwitchedByIgnition" SG_ 931 MO_StartStopp_Wiederstart 0;
BA_ "GenSigSendType" SG_ 931 MO_StartStopp_Wiederstart 0;
BA_ "GenSigSwitchedByIgnition" SG_ 931 MO_Ext_E_Fahrt_aktiv 0;
BA_ "NWM-WakeupAllowed" SG_ 931 MO_Ext_E_Fahrt_aktiv 1;
BA_ "GenSigSendType" SG_ 931 MO_Ext_E_Fahrt_aktiv 0;
BA_ "Fehlerwert" SG_ 931 MO_Gangposition 15;
BA_ "GenSigSwitchedByIgnition" SG_ 931 MO_Gangposition 0;
BA_ "GenSigStartValue" SG_ 931 MO_Gangposition 14;
BA_ "GenSigSendType" SG_ 931 MO_Gangposition 0;
BA_ "GenSigSwitchedByIgnition" SG_ 931 MO_StartStopp_Fahrerwunsch 0;
BA_ "GenSigSendType" SG_ 931 MO_StartStopp_Fahrerwunsch 0;
BA_ "GenSigSwitchedByIgnition" SG_ 931 MO_Momentenintegral 0;
BA_ "GenSigSendType" SG_ 931 MO_Momentenintegral 0;
BA_ "GenSigSwitchedByIgnition" SG_ 1747 NM_CDR_PCM_Start_1 0;
BA_ "GenSigSwitchedByIgnition" SG_ 1747 NM_CDR_PCM_Start_2 0;
BA_ "GenSigSwitchedByIgnition" SG_ 1747 NM_CDR_PCM_Normal_Mode_1 0;
BA_ "GenSigSwitchedByIgnition" SG_ 1747 NM_CDR_PCM_Normal_Mode_2 0;
BA_ "GenSigSwitchedByIgnition" SG_ 1747 NM_CDR_PCM_Car_WakeUp 0;
BA_ "GenSigSwitchedByIgnition" SG_ 1747 NM_CDR_PCM_Per_WakeUp 0;
BA_ "NWM-WakeupAllowed" SG_ 1747 NM_CDR_PCM_Per_WakeUp 1;
BA_ "GenSigSwitchedByIgnition" SG_ 1747 NM_CDR_PCM_Fkt_WakeUp 0;
BA_ "NWM-WakeupAllowed" SG_ 1747 NM_CDR_PCM_Fkt_WakeUp 1;
BA_ "GenSigSwitchedByIgnition" SG_ 1747 NM_CDR_PCM_Klemme_15 0;
BA_ "GenSigSwitchedByIgnition" SG_ 1747 NM_CDR_PCM_Diagnose 0;
BA_ "GenSigSwitchedByIgnition" SG_ 1747 NM_CDR_PCM_MindestAktivZeit 0;
BA_ "GenSigSwitchedByIgnition" SG_ 1747 NMH_CDR_PCM_Signalfehler 0;
BA_ "GenSigSwitchedByIgnition" SG_ 1747 NM_CDR_PCM_TimeOut_Fehler 0;
BA_ "GenSigSwitchedByIgnition" SG_ 1747 NM_CDR_PCM_CAN_Diag_deaktiv 0;
BA_ "GenSigSwitchedByIgnition" SG_ 1747 NM_CDR_PCM_KompSchutz 0;
BA_ "GenSigSwitchedByIgnition" SG_ 1747 NM_CDR_PCM_Mute_Mode 0;
BA_ "GenSigSwitchedByIgnition" SG_ 1747 NM_CDR_PCM_Transport_Mode 0;
BA_ "GenSigSwitchedByIgnition" SG_ 1747 NM_CDR_PCM_Abschaltstufe_aktiv 0;
BA_ "GenSigSwitchedByIgnition" SG_ 1747 NM_CDR_PCM_Busfehler 0;
BA_ "GenSigSwitchedByIgnition" SG_ 1747 NMH_CDR_PCM_Lokalaktiv 0;
BA_ "GenSigSwitchedByIgnition" SG_ 1747 NMH_CDR_PCM_Subsystemaktiv 0;
BA_ "GenSigSwitchedByIgnition" SG_ 1728 NMH_GW_Start_1 0;
BA_ "GenSigStartValue" SG_ 1728 NMH_GW_Start_1 1;
BA_ "GenSigSwitchedByIgnition" SG_ 1728 NMH_GW_Start_2 0;
BA_ "GenSigSwitchedByIgnition" SG_ 1728 NMH_GW_Normal_Mode_1 0;
BA_ "GenSigSwitchedByIgnition" SG_ 1728 NMH_GW_Normal_Mode_2 0;
BA_ "GenSigSwitchedByIgnition" SG_ 1728 NMH_GW_Car_WakeUp 0;
BA_ "GenSigSwitchedByIgnition" SG_ 1728 NMH_GW_Per_WakeUp 0;
BA_ "NWM-WakeupAllowed" SG_ 1728 NMH_GW_Per_WakeUp 1;
BA_ "GenSigSwitchedByIgnition" SG_ 1728 NMH_GW_Fkt_WakeUp 0;
BA_ "NWM-WakeupAllowed" SG_ 1728 NMH_GW_Fkt_WakeUp 1;
BA_ "GenSigSwitchedByIgnition" SG_ 1728 NMH_GW_NM_aktiv_Klemme_15 0;
BA_ "GenSigSwitchedByIgnition" SG_ 1728 NMH_GW_NM_aktiv_Diagnose 0;
BA_ "GenSigSwitchedByIgnition" SG_ 1728 NMH_GW_NM_aktiv_Start 0;
BA_ "GenSigSwitchedByIgnition" SG_ 1728 NMH_GW_NM_aktiv_BDM 0;
BA_ "GenSigSwitchedByIgnition" SG_ 1728 NMH_GW_NM_aktiv_Warnblinken 0;
BA_ "GenSigSwitchedByIgnition" SG_ 1728 NMH_GW_NM_aktiv_ESP 0;
BA_ "GenSigSwitchedByIgnition" SG_ 1728 NMH_GW_NM_aktiv_EMP 0;
BA_ "GenSigSwitchedByIgnition" SG_ 1728 NMH_GW_Abschaltstufe_3 0;
BA_ "GenSigSwitchedByIgnition" SG_ 1728 NMH_GW_SG_Fehlerdauer 0;
BA_ "GenSigSwitchedByIgnition" SG_ 1728 NMH_GW_STH_Wakeup 0;
BA_ "GenSigSwitchedByIgnition" SG_ 1728 NMH_GW_NL_Diagnose 0;
BA_ "GenSigSwitchedByIgnition" SG_ 1728 NM_GW_Signalfehler 0;
BA_ "GenSigSwitchedByIgnition" SG_ 1728 NMH_GW_TimeOut_Fehler 0;
BA_ "GenSigSwitchedByIgnition" SG_ 1728 NMH_GW_CAN_Diag_deaktiv 0;
BA_ "GenSigSwitchedByIgnition" SG_ 1728 NMH_GW_KompSchutz 0;
BA_ "GenSigSwitchedByIgnition" SG_ 1728 NMH_GW_Mute_Mode 0;
BA_ "GenSigSwitchedByIgnition" SG_ 1728 NMH_GW_Transport_Mode 0;
BA_ "GenSigSwitchedByIgnition" SG_ 1728 NMH_GW_Abschaltstufe_aktiv 0;
BA_ "GenSigSwitchedByIgnition" SG_ 1728 NMH_GW_Eindraht_Fehler 0;
BA_ "GenSigSwitchedByIgnition" SG_ 1728 NMH_GW_ACAN 0;
BA_ "GenSigSwitchedByIgnition" SG_ 1728 NMH_GW_KombiCAN 0;
BA_ "GenSigSwitchedByIgnition" SG_ 1728 NMH_GW_KomfortCAN 0;
BA_ "GenSigSwitchedByIgnition" SG_ 1728 NMH_GW_Infotainment 0;
BA_ "GenSigSwitchedByIgnition" SG_ 1728 NMH_GW_Fahrwerk 0;
BA_ "GenSigSwitchedByIgnition" SG_ 1728 NMH_GW_WakeUp_CAN_Bus 0;
BA_ "GenSigSwitchedByIgnition" SG_ 1775 NMH_GSM_Start_1 0;
BA_ "GenSigSwitchedByIgnition" SG_ 1775 NMH_GSM_Start_2 0;
BA_ "GenSigSwitchedByIgnition" SG_ 1775 NMH_GSM_Normal_Mode_1 0;
BA_ "GenSigSwitchedByIgnition" SG_ 1775 NMH_GSM_Normal_Mode_2 0;
BA_ "GenSigSwitchedByIgnition" SG_ 1775 NMH_GSM_Car_WakeUp 0;
BA_ "GenSigSwitchedByIgnition" SG_ 1775 NMH_GSM_Per_WakeUp 0;
BA_ "NWM-WakeupAllowed" SG_ 1775 NMH_GSM_Per_WakeUp 1;
BA_ "GenSigSwitchedByIgnition" SG_ 1775 NMH_GSM_Fkt_WakeUp 0;
BA_ "NWM-WakeupAllowed" SG_ 1775 NMH_GSM_Fkt_WakeUp 1;
BA_ "GenSigSwitchedByIgnition" SG_ 1775 NMH_GSM_Klemme_15 0;
BA_ "GenSigSwitchedByIgnition" SG_ 1775 NMH_GSM_Diagnose 0;
BA_ "GenSigSwitchedByIgnition" SG_ 1775 NMH_GSM_MindestAktivZeit 0;
BA_ "GenSigSwitchedByIgnition" SG_ 1775 NMH_GSM_Signalfehler 0;
BA_ "GenSigSwitchedByIgnition" SG_ 1775 NMH_GSM_TimeOut_Fehler 0;
BA_ "GenSigSwitchedByIgnition" SG_ 1775 NMH_GSM_CAN_Diag_deaktiv 0;
BA_ "GenSigSwitchedByIgnition" SG_ 1775 NMH_GSM_KompSchutz 0;
BA_ "GenSigSwitchedByIgnition" SG_ 1775 NMH_GSM_Mute_Mode 0;
BA_ "GenSigSwitchedByIgnition" SG_ 1775 NMH_GSM_Transport_Mode 0;
BA_ "GenSigSwitchedByIgnition" SG_ 1775 NMH_GSM_Abschaltstufe_aktiv 0;
BA_ "GenSigSwitchedByIgnition" SG_ 1775 NMH_GSM_Eindraht_Fehler 0;
BA_ "GenSigSwitchedByIgnition" SG_ 1775 NMH_GSM_Lokalaktiv 0;
BA_ "GenSigSwitchedByIgnition" SG_ 1775 NMH_GSM_Subsystemaktiv 0;
BA_ "GenSigSwitchedByIgnition" SG_ 1772 NMH_KL_Start_1 0;
BA_ "GenSigSwitchedByIgnition" SG_ 1772 NMH_KL_Start_2 0;
BA_ "GenSigSwitchedByIgnition" SG_ 1772 NMH_KL_Normal_Mode_1 0;
BA_ "GenSigSwitchedByIgnition" SG_ 1772 NMH_KL_Normal_Mode_2 0;
BA_ "GenSigSwitchedByIgnition" SG_ 1772 NM_KL_Car_WakeUp 0;
BA_ "GenSigSwitchedByIgnition" SG_ 1772 NM_KL_Per_WakeUp 0;
BA_ "NWM-WakeupAllowed" SG_ 1772 NM_KL_Per_WakeUp 1;
BA_ "GenSigSwitchedByIgnition" SG_ 1772 NM_KL_Fkt_WakeUp 0;
BA_ "NWM-WakeupAllowed" SG_ 1772 NM_KL_Fkt_WakeUp 1;
BA_ "GenSigSwitchedByIgnition" SG_ 1772 NM_KL_Klemme_15 0;
BA_ "GenSigSwitchedByIgnition" SG_ 1772 NM_KL_Diagnose 0;
BA_ "GenSigSwitchedByIgnition" SG_ 1772 NM_KL_MindestAktivZeit 0;
BA_ "GenSigSwitchedByIgnition" SG_ 1772 NM_KL_FKT_Nachlauf_Klappen 0;
BA_ "GenSigSwitchedByIgnition" SG_ 1772 NM_KL_NL_STH 0;
BA_ "GenSigSwitchedByIgnition" SG_ 1772 NM_KL_NL_Restwaerme 0;
BA_ "GenSigSwitchedByIgnition" SG_ 1772 NM_KL_NL_LIN 0;
BA_ "GenSigSwitchedByIgnition" SG_ 1772 NM_Klima_Signalfehler 0;
BA_ "GenSigSwitchedByIgnition" SG_ 1772 NM_KL_TimeOut_Fehler 0;
BA_ "GenSigSwitchedByIgnition" SG_ 1772 NM_KL_CAN_Diag_deaktiv 0;
BA_ "GenSigSwitchedByIgnition" SG_ 1772 NM_KL_KompSchutz 0;
BA_ "GenSigSwitchedByIgnition" SG_ 1772 NM_KL_Mute_Mode 0;
BA_ "GenSigSwitchedByIgnition" SG_ 1772 NM_KL_Transport_Mode 0;
BA_ "GenSigSwitchedByIgnition" SG_ 1772 NM_KL_Abschaltstufe_aktiv 0;
BA_ "GenSigSwitchedByIgnition" SG_ 1772 NM_KL_Eindraht_Fehler 0;
BA_ "GenSigSwitchedByIgnition" SG_ 1772 NMH_Klima_Lokalaktiv 0;
BA_ "GenSigSwitchedByIgnition" SG_ 1772 NMH_Klima_Subsystemaktiv 0;
BA_ "GenSigSwitchedByIgnition" SG_ 1735 NMH_KBI_Start_1 0;
BA_ "GenSigStartValue" SG_ 1735 NMH_KBI_Start_1 1;
BA_ "GenSigSwitchedByIgnition" SG_ 1735 NMH_KBI_Start_2 0;
BA_ "GenSigSwitchedByIgnition" SG_ 1735 NMH_KBI_Normal_Mode_1 0;
BA_ "GenSigSwitchedByIgnition" SG_ 1735 NMH_KBI_Normal_Mode_2 0;
BA_ "GenSigSwitchedByIgnition" SG_ 1735 NMH_KBI_Car_WakeUp 0;
BA_ "GenSigSwitchedByIgnition" SG_ 1735 NMH_KBI_Per_WakeUp 0;
BA_ "NWM-WakeupAllowed" SG_ 1735 NMH_KBI_Per_WakeUp 1;
BA_ "GenSigSwitchedByIgnition" SG_ 1735 NMH_KBI_Fkt_WakeUp 0;
BA_ "NWM-WakeupAllowed" SG_ 1735 NMH_KBI_Fkt_WakeUp 1;
BA_ "GenSigSwitchedByIgnition" SG_ 1735 NMH_KBI_NM_aktiv_Klemme_15 0;
BA_ "GenSigSwitchedByIgnition" SG_ 1735 NMH_KBI_NM_aktiv_Diagnose 0;
BA_ "GenSigSwitchedByIgnition" SG_ 1735 NMH_KBI_NM_aktiv_Start 0;
BA_ "GenSigSwitchedByIgnition" SG_ 1735 NMH_KBI_NM_aktiv_Tankinhalt 0;
BA_ "GenSigSwitchedByIgnition" SG_ 1735 NMH_KBI_NM_aktiv_Display 0;
BA_ "GenSigSwitchedByIgnition" SG_ 1735 NMH_KBI_kein_NL 0;
BA_ "GenSigSwitchedByIgnition" SG_ 1735 NMH_KBI_NL_Sync_Funkuhr 0;
BA_ "GenSigSwitchedByIgnition" SG_ 1735 NM_Kombi_NL_Warnblinken 0;
BA_ "GenSigSwitchedByIgnition" SG_ 1735 NMH_KBI_NL_KL15 0;
BA_ "GenSigSwitchedByIgnition" SG_ 1735 NMH_KBI_Signalfehler 0;
BA_ "GenSigSwitchedByIgnition" SG_ 1735 NMH_KBI_TimeOut_Fehler 0;
BA_ "GenSigSwitchedByIgnition" SG_ 1735 NMH_KBI_CAN_Diag_deaktiv 0;
BA_ "GenSigSwitchedByIgnition" SG_ 1735 NMH_KBI_KompSchutz 0;
BA_ "GenSigSwitchedByIgnition" SG_ 1735 NMH_KBI_Mute_Mode 0;
BA_ "GenSigSwitchedByIgnition" SG_ 1735 NMH_KBI_Transport_Mode 0;
BA_ "GenSigSwitchedByIgnition" SG_ 1735 NMH_KBI_Abschaltstufe_aktiv 0;
BA_ "GenSigSwitchedByIgnition" SG_ 1735 NMH_KBI_Eindraht_Fehler 0;
BA_ "GenSigSwitchedByIgnition" SG_ 1735 NMH_Kombi_Lokalaktiv 0;
BA_ "GenSigSwitchedByIgnition" SG_ 1735 NMH_Kombi_Subsystemaktiv 0;
BA_ "GenSigSwitchedByIgnition" SG_ 1750 NMH_Miko_Start_1 0;
BA_ "GenSigSwitchedByIgnition" SG_ 1750 NMH_Miko_Start_2 0;
BA_ "GenSigSwitchedByIgnition" SG_ 1750 NMH_Miko_Normal_Mode_1 0;
BA_ "GenSigSwitchedByIgnition" SG_ 1750 NMH_Miko_Normal_Mode_2 0;
BA_ "GenSigSwitchedByIgnition" SG_ 1750 NMH_Miko_Car_WakeUp 0;
BA_ "GenSigSwitchedByIgnition" SG_ 1750 NMH_Miko_Per_WakeUp 0;
BA_ "NWM-WakeupAllowed" SG_ 1750 NMH_Miko_Per_WakeUp 1;
BA_ "GenSigSwitchedByIgnition" SG_ 1750 NMH_Miko_Fkt_WakeUp 0;
BA_ "NWM-WakeupAllowed" SG_ 1750 NMH_Miko_Fkt_WakeUp 1;
BA_ "GenSigSwitchedByIgnition" SG_ 1750 NMH_Miko_Signalfehler 0;
BA_ "GenSigSwitchedByIgnition" SG_ 1750 NMH_Miko_TimeOut_Fehler 0;
BA_ "GenSigSwitchedByIgnition" SG_ 1774 NM_RDK_Start_1 0;
BA_ "GenSigSwitchedByIgnition" SG_ 1774 NM_RDK_Start_2 0;
BA_ "GenSigSwitchedByIgnition" SG_ 1774 NM_RDK_Normal_Mode_1 0;
BA_ "GenSigSwitchedByIgnition" SG_ 1774 NM_RDK_Normal_Mode_2 0;
BA_ "GenSigSwitchedByIgnition" SG_ 1774 NM_RDK_Car_WakeUp 0;
BA_ "GenSigSwitchedByIgnition" SG_ 1774 NM_RDK_Per_WakeUp 0;
BA_ "NWM-WakeupAllowed" SG_ 1774 NM_RDK_Per_WakeUp 1;
BA_ "GenSigSwitchedByIgnition" SG_ 1774 NM_RDK_Fkt_WakeUp 0;
BA_ "NWM-WakeupAllowed" SG_ 1774 NM_RDK_Fkt_WakeUp 1;
BA_ "GenSigSwitchedByIgnition" SG_ 1774 NM_RDK_Klemme_15 0;
BA_ "GenSigSwitchedByIgnition" SG_ 1774 NM_RDK_Diagnose 0;
BA_ "GenSigSwitchedByIgnition" SG_ 1774 NM_RDK_MindestAktivZeit 0;
BA_ "GenSigSwitchedByIgnition" SG_ 1774 NMH_RDK_NL_Radmanagement 0;
BA_ "GenSigSwitchedByIgnition" SG_ 1774 NM_RDK_Signalfehler 0;
BA_ "GenSigSwitchedByIgnition" SG_ 1774 NM_RDK_TimeOut_Fehler 0;
BA_ "GenSigSwitchedByIgnition" SG_ 1774 NM_RDK_CAN_Diag_deaktiv 0;
BA_ "GenSigSwitchedByIgnition" SG_ 1774 NM_RDK_KompSchutz 0;
BA_ "GenSigSwitchedByIgnition" SG_ 1774 NM_RDK_Mute_Mode 0;
BA_ "GenSigSwitchedByIgnition" SG_ 1774 NM_RDK_Transport_Mode 0;
BA_ "GenSigSwitchedByIgnition" SG_ 1774 NM_RDK_Abschaltstufe_aktiv 0;
BA_ "GenSigSwitchedByIgnition" SG_ 1774 NM_RDK_Eindraht_Fehler 0;
BA_ "GenSigSwitchedByIgnition" SG_ 1774 NMH_RDK_Lokalaktiv 0;
BA_ "GenSigSwitchedByIgnition" SG_ 1774 NMH_RDK_Subsystemaktiv 0;
BA_ "GenSigSwitchedByIgnition" SG_ 1156 NPM_ForceShutdown 0;
BA_ "GenSigSendType" SG_ 1156 NPM_ForceShutdown 0;
BA_ "GenSigSwitchedByIgnition" SG_ 1156 NPM_PreventWakeup 0;
BA_ "GenSigSendType" SG_ 1156 NPM_PreventWakeup 0;
BA_ "GenSigSwitchedByIgnition" SG_ 1156 NPM_directAdressing 0;
BA_ "GenSigSendType" SG_ 1156 NPM_directAdressing 0;
BA_ "GenSigSwitchedByIgnition" SG_ 1156 NPM_FS_VSG 0;
BA_ "GenSigSendType" SG_ 1156 NPM_FS_VSG 0;
BA_ "GenSigSwitchedByIgnition" SG_ 1156 NPM_FS_HAL 0;
BA_ "GenSigSendType" SG_ 1156 NPM_FS_HAL 0;
BA_ "GenSigSwitchedByIgnition" SG_ 1156 NPM_FS_Vorhalt03 0;
BA_ "GenSigSendType" SG_ 1156 NPM_FS_Vorhalt03 0;
BA_ "GenSigSwitchedByIgnition" SG_ 1156 NPM_FS_Vorhalt04 0;
BA_ "GenSigSendType" SG_ 1156 NPM_FS_Vorhalt04 0;
BA_ "GenSigSwitchedByIgnition" SG_ 1156 NPM_FS_EPB 0;
BA_ "GenSigSendType" SG_ 1156 NPM_FS_EPB 0;
BA_ "GenSigSwitchedByIgnition" SG_ 1156 NPM_FS_Niveau 0;
BA_ "GenSigSendType" SG_ 1156 NPM_FS_Niveau 0;
BA_ "GenSigSwitchedByIgnition" SG_ 1156 NPM_FS_BCM1 0;
BA_ "GenSigSendType" SG_ 1156 NPM_FS_BCM1 0;
BA_ "GenSigSwitchedByIgnition" SG_ 1156 NPM_FS_BCM2 0;
BA_ "GenSigSendType" SG_ 1156 NPM_FS_BCM2 0;
BA_ "GenSigSwitchedByIgnition" SG_ 1156 NPM_FS_TF 0;
BA_ "GenSigSendType" SG_ 1156 NPM_FS_TF 0;
BA_ "GenSigSwitchedByIgnition" SG_ 1156 NPM_FS_TB 0;
BA_ "GenSigSendType" SG_ 1156 NPM_FS_TB 0;
BA_ "GenSigSwitchedByIgnition" SG_ 1156 NPM_FS_Lenkhilfe 0;
BA_ "GenSigSendType" SG_ 1156 NPM_FS_Lenkhilfe 0;
BA_ "GenSigSwitchedByIgnition" SG_ 1156 NPM_FS_Vorhalt12 0;
BA_ "GenSigSendType" SG_ 1156 NPM_FS_Vorhalt12 0;
BA_ "GenSigSwitchedByIgnition" SG_ 1156 NPM_FS_SF 0;
BA_ "GenSigSendType" SG_ 1156 NPM_FS_SF 0;
BA_ "GenSigSwitchedByIgnition" SG_ 1156 NPM_FS_SB 0;
BA_ "GenSigSendType" SG_ 1156 NPM_FS_SB 0;
BA_ "GenSigSwitchedByIgnition" SG_ 1156 NPM_FS_SMLS 0;
BA_ "GenSigSendType" SG_ 1156 NPM_FS_SMLS 0;
BA_ "GenSigSwitchedByIgnition" SG_ 1156 NPM_FS_RDK 0;
BA_ "GenSigSendType" SG_ 1156 NPM_FS_RDK 0;
BA_ "GenSigSwitchedByIgnition" SG_ 1156 NPM_FS_AAG 0;
BA_ "GenSigSendType" SG_ 1156 NPM_FS_AAG 0;
BA_ "GenSigSwitchedByIgnition" SG_ 1156 NPM_FS_HDSG 0;
BA_ "GenSigSendType" SG_ 1156 NPM_FS_HDSG 0;
BA_ "GenSigSwitchedByIgnition" SG_ 1156 NPM_FS_RFK 0;
BA_ "GenSigSendType" SG_ 1156 NPM_FS_RFK 0;
BA_ "GenSigSwitchedByIgnition" SG_ 1156 NPM_FS_TopView 0;
BA_ "GenSigSendType" SG_ 1156 NPM_FS_TopView 0;
BA_ "GenSigSwitchedByIgnition" SG_ 1156 NPM_FS_Vorhalt21 0;
BA_ "GenSigSendType" SG_ 1156 NPM_FS_Vorhalt21 0;
BA_ "GenSigSwitchedByIgnition" SG_ 1156 NPM_FS_KMB 0;
BA_ "GenSigSendType" SG_ 1156 NPM_FS_KMB 0;
BA_ "GenSigSwitchedByIgnition" SG_ 1156 NPM_FS_Miko 0;
BA_ "GenSigSendType" SG_ 1156 NPM_FS_Miko 0;
BA_ "GenSigSwitchedByIgnition" SG_ 1156 NPM_FS_SU 0;
BA_ "GenSigSendType" SG_ 1156 NPM_FS_SU 0;
BA_ "GenSigSwitchedByIgnition" SG_ 1156 NPM_FS_HU 0;
BA_ "GenSigSendType" SG_ 1156 NPM_FS_HU 0;
BA_ "GenSigSwitchedByIgnition" SG_ 1156 NPM_FS_BKE 0;
BA_ "GenSigSendType" SG_ 1156 NPM_FS_BKE 0;
BA_ "GenSigSwitchedByIgnition" SG_ 1156 NPM_FS_Vorhalt27 0;
BA_ "GenSigSendType" SG_ 1156 NPM_FS_Vorhalt27 0;
BA_ "GenSigSwitchedByIgnition" SG_ 1156 NPM_PrWu_VSG 0;
BA_ "GenSigSendType" SG_ 1156 NPM_PrWu_VSG 0;
BA_ "GenSigSwitchedByIgnition" SG_ 1156 NPM_PrWu_HAL 0;
BA_ "GenSigSendType" SG_ 1156 NPM_PrWu_HAL 0;
BA_ "GenSigSwitchedByIgnition" SG_ 1156 NPM_PrWu_Vorhalt03 0;
BA_ "GenSigSendType" SG_ 1156 NPM_PrWu_Vorhalt03 0;
BA_ "GenSigSwitchedByIgnition" SG_ 1156 NPM_PrWu_Vorhalt04 0;
BA_ "GenSigSendType" SG_ 1156 NPM_PrWu_Vorhalt04 0;
BA_ "GenSigSwitchedByIgnition" SG_ 1156 NPM_PrWu_EPB 0;
BA_ "GenSigSendType" SG_ 1156 NPM_PrWu_EPB 0;
BA_ "GenSigSwitchedByIgnition" SG_ 1156 NPM_PrWu_Niveau 0;
BA_ "GenSigSendType" SG_ 1156 NPM_PrWu_Niveau 0;
BA_ "GenSigSwitchedByIgnition" SG_ 1156 NPM_PrWu_BCM1 0;
BA_ "GenSigSendType" SG_ 1156 NPM_PrWu_BCM1 0;
BA_ "GenSigSwitchedByIgnition" SG_ 1156 NPM_PrWu_BCM2 0;
BA_ "GenSigSendType" SG_ 1156 NPM_PrWu_BCM2 0;
BA_ "GenSigSwitchedByIgnition" SG_ 1156 NPM_PrWu_TF 0;
BA_ "GenSigSendType" SG_ 1156 NPM_PrWu_TF 0;
BA_ "GenSigSwitchedByIgnition" SG_ 1156 NPM_PrWu_TB 0;
BA_ "GenSigSendType" SG_ 1156 NPM_PrWu_TB 0;
BA_ "GenSigSwitchedByIgnition" SG_ 1156 NPM_PrWu_Lenkhilfe 0;
BA_ "GenSigSendType" SG_ 1156 NPM_PrWu_Lenkhilfe 0;
BA_ "GenSigSwitchedByIgnition" SG_ 1156 NPM_PrWu_SF 0;
BA_ "GenSigSendType" SG_ 1156 NPM_PrWu_SF 0;
BA_ "GenSigSwitchedByIgnition" SG_ 1156 NPM_PrWu_SB 0;
BA_ "GenSigSendType" SG_ 1156 NPM_PrWu_SB 0;
BA_ "GenSigSwitchedByIgnition" SG_ 1156 NPM_PrWu_SMLS 0;
BA_ "GenSigSendType" SG_ 1156 NPM_PrWu_SMLS 0;
BA_ "GenSigSwitchedByIgnition" SG_ 1156 NPM_PrWu_RDK 0;
BA_ "GenSigSendType" SG_ 1156 NPM_PrWu_RDK 0;
BA_ "GenSigSwitchedByIgnition" SG_ 1156 NPM_PrWu_AAG 0;
BA_ "GenSigSendType" SG_ 1156 NPM_PrWu_AAG 0;
BA_ "GenSigSwitchedByIgnition" SG_ 1156 NPM_PrWu_HDSG 0;
BA_ "GenSigSendType" SG_ 1156 NPM_PrWu_HDSG 0;
BA_ "GenSigSwitchedByIgnition" SG_ 1156 NPM_PrWu_RFK 0;
BA_ "GenSigSendType" SG_ 1156 NPM_PrWu_RFK 0;
BA_ "GenSigSwitchedByIgnition" SG_ 1156 NPM_PrWu_TopView 0;
BA_ "GenSigSendType" SG_ 1156 NPM_PrWu_TopView 0;
BA_ "GenSigSwitchedByIgnition" SG_ 1156 NPM_PrWu_Vorhalt21 0;
BA_ "GenSigSendType" SG_ 1156 NPM_PrWu_Vorhalt21 0;
BA_ "GenSigSwitchedByIgnition" SG_ 1156 NPM_PrWu_KMB 0;
BA_ "GenSigSendType" SG_ 1156 NPM_PrWu_KMB 0;
BA_ "GenSigSwitchedByIgnition" SG_ 1156 NPM_PrWu_Miko 0;
BA_ "GenSigSendType" SG_ 1156 NPM_PrWu_Miko 0;
BA_ "GenSigSwitchedByIgnition" SG_ 1156 NPM_PrWu_SU 0;
BA_ "GenSigSendType" SG_ 1156 NPM_PrWu_SU 0;
BA_ "GenSigSwitchedByIgnition" SG_ 1156 NPM_PrWu_HU 0;
BA_ "GenSigSendType" SG_ 1156 NPM_PrWu_HU 0;
BA_ "GenSigSwitchedByIgnition" SG_ 1156 NPM_PrWu_BKE 0;
BA_ "GenSigSendType" SG_ 1156 NPM_PrWu_BKE 0;
BA_ "GenSigSwitchedByIgnition" SG_ 1156 NPM_PrWu_Vorhalt27 0;
BA_ "GenSigSendType" SG_ 1156 NPM_PrWu_Vorhalt27 0;
BA_ "GenSigSwitchedByIgnition" SG_ 1630 OBD_TG_F_Status_1 0;
BA_ "GenSigSendType" SG_ 1630 OBD_TG_F_Status_1 0;
BA_ "GenSigSwitchedByIgnition" SG_ 1630 OBD_TG_F_Status_2 0;
BA_ "GenSigSendType" SG_ 1630 OBD_TG_F_Status_2 0;
BA_ "GenSigSwitchedByIgnition" SG_ 1630 OBD_TG_F_Status_3 0;
BA_ "GenSigSendType" SG_ 1630 OBD_TG_F_Status_3 0;
BA_ "GenSigSwitchedByIgnition" SG_ 1630 OBD_TG_F_Status_4 0;
BA_ "GenSigSendType" SG_ 1630 OBD_TG_F_Status_4 0;
BA_ "GenSigSwitchedByIgnition" SG_ 1630 OBD_TG_Sens_Rohwert_1 0;
BA_ "GenSigSendType" SG_ 1630 OBD_TG_Sens_Rohwert_1 0;
BA_ "GenSigSwitchedByIgnition" SG_ 1630 OBD_TG_Sens_Rohwert_2 0;
BA_ "GenSigSendType" SG_ 1630 OBD_TG_Sens_Rohwert_2 0;
BA_ "GenSigSwitchedByIgnition" SG_ 1630 OBD_TG_Sens_Rohwert_3 0;
BA_ "GenSigSendType" SG_ 1630 OBD_TG_Sens_Rohwert_3 0;
BA_ "GenSigSwitchedByIgnition" SG_ 1630 OBD_TG_Sens_Rohwert_4 0;
BA_ "GenSigSendType" SG_ 1630 OBD_TG_Sens_Rohwert_4 0;
BA_ "GenSigSwitchedByIgnition" SG_ 1337 PCM_FOT_Temp 0;
BA_ "GenSigSendType" SG_ 1337 PCM_FOT_Temp 0;
BA_ "GenSigSwitchedByIgnition" SG_ 1337 PCM_HMI_mode 0;
BA_ "NWM-WakeupAllowed" SG_ 1337 PCM_HMI_mode 1;
BA_ "GenSigSendType" SG_ 1337 PCM_HMI_mode 0;
BA_ "GenSigSwitchedByIgnition" SG_ 1337 PCM_RFK_manuell 0;
BA_ "NWM-WakeupAllowed" SG_ 1337 PCM_RFK_manuell 1;
BA_ "GenSigSendType" SG_ 1337 PCM_RFK_manuell 0;
BA_ "GenSigSwitchedByIgnition" SG_ 1337 PCM_Rundenfarbe 0;
BA_ "GenSigSendType" SG_ 1337 PCM_Rundenfarbe 0;
BA_ "GenSigSwitchedByIgnition" SG_ 1337 PCM_Limit_Info 0;
BA_ "GenSigSendType" SG_ 1337 PCM_Limit_Info 0;
BA_ "GenSigSwitchedByIgnition" SG_ 1337 PCM_Limit_Einheit 0;
BA_ "GenSigSendType" SG_ 1337 PCM_Limit_Einheit 0;
BA_ "GenSigSwitchedByIgnition" SG_ 1337 PCM_Rundenfortschritt 0;
BA_ "GenSigSendType" SG_ 1337 PCM_Rundenfortschritt 0;
BA_ "Fehlerwert" SG_ 1337 PCM_Kompass 511;
BA_ "GenSigSwitchedByIgnition" SG_ 1337 PCM_Kompass 0;
BA_ "GenSigSendType" SG_ 1337 PCM_Kompass 0;
BA_ "GenSigSwitchedByIgnition" SG_ 1337 PCM_Elev_Einheit 0;
BA_ "NWM-WakeupAllowed" SG_ 1337 PCM_Elev_Einheit 1;
BA_ "GenSigSendType" SG_ 1337 PCM_Elev_Einheit 0;
BA_ "GenSigSwitchedByIgnition" SG_ 1337 PCM_HMI_Mode_TopView 0;
BA_ "GenSigSendType" SG_ 1337 PCM_HMI_Mode_TopView 0;
BA_ "GenSigSwitchedByIgnition" SG_ 1337 PCM_Street_class 0;
BA_ "GenSigSendType" SG_ 1337 PCM_Street_class 0;
BA_ "GenSigSwitchedByIgnition" SG_ 1337 PCM_Sat 0;
BA_ "GenSigSendType" SG_ 1337 PCM_Sat 0;
BA_ "GenSigSwitchedByIgnition" SG_ 1337 PCM_Entfernung_Kurve 0;
BA_ "GenSigSwitchedByIgnition" SG_ 1530 GPS_N_Grad 0;
BA_ "GenSigSendType" SG_ 1530 GPS_N_Grad 0;
BA_ "GenSigSwitchedByIgnition" SG_ 1530 GPS_E_Grad 0;
BA_ "GenSigSendType" SG_ 1530 GPS_E_Grad 0;
BA_ "GenSigMissingSourceValue" SG_ 1530 GPS_elev 8191;
BA_ "GenSigSwitchedByIgnition" SG_ 1530 GPS_elev 0;
BA_ "GenSigStartValue" SG_ 1530 GPS_elev 8191;
BA_ "GenSigSendType" SG_ 1530 GPS_elev 0;
BA_ "GenSigSwitchedByIgnition" SG_ 1707 PCM_Std 0;
BA_ "GenSigSendType" SG_ 1707 PCM_Std 0;
BA_ "GenSigSwitchedByIgnition" SG_ 1707 PCM_Min 0;
BA_ "GenSigSendType" SG_ 1707 PCM_Min 0;
BA_ "GenSigSwitchedByIgnition" SG_ 1707 PCM_Sek 0;
BA_ "GenSigSendType" SG_ 1707 PCM_Sek 0;
BA_ "GenSigSwitchedByIgnition" SG_ 1707 PCM_Zeitzone 0;
BA_ "GenSigSendType" SG_ 1707 PCM_Zeitzone 0;
BA_ "GenSigSwitchedByIgnition" SG_ 1707 PCM_Zeitzone_Vorzeichen 0;
BA_ "GenSigSendType" SG_ 1707 PCM_Zeitzone_Vorzeichen 0;
BA_ "GenSigSwitchedByIgnition" SG_ 1707 PCM_Uebern 0;
BA_ "GenSigSendType" SG_ 1707 PCM_Uebern 0;
BA_ "GenSigSwitchedByIgnition" SG_ 1707 PCM_Tag 0;
BA_ "GenSigStartValue" SG_ 1707 PCM_Tag 1;
BA_ "GenSigSendType" SG_ 1707 PCM_Tag 0;
BA_ "GenSigSwitchedByIgnition" SG_ 1707 PCM_Mon 0;
BA_ "GenSigStartValue" SG_ 1707 PCM_Mon 1;
BA_ "GenSigSendType" SG_ 1707 PCM_Mon 0;
BA_ "GenSigSwitchedByIgnition" SG_ 1707 PCM_JJ 0;
BA_ "GenSigSendType" SG_ 1707 PCM_JJ 0;
BA_ "GenSigSwitchedByIgnition" SG_ 1707 PCM_Sommerzeit 0;
BA_ "GenSigSendType" SG_ 1707 PCM_Sommerzeit 0;
BA_ "GenSigSwitchedByIgnition" SG_ 1707 PCM_Reset_Trip_1 0;
BA_ "GenSigSendType" SG_ 1707 PCM_Reset_Trip_1 0;
BA_ "GenSigSwitchedByIgnition" SG_ 1707 PCM_Reset_Trip_2 0;
BA_ "GenSigSendType" SG_ 1707 PCM_Reset_Trip_2 0;
BA_ "Fehlerwert" SG_ 1707 HU_Fotosensor 511;
BA_ "GenSigSwitchedByIgnition" SG_ 1707 HU_Fotosensor 0;
BA_ "GenSigStartValue" SG_ 1707 HU_Fotosensor 510;
BA_ "GenSigSendType" SG_ 1707 HU_Fotosensor 0;
BA_ "GenSigSwitchedByIgnition" SG_ 1707 HU_SVB_AMP 0;
BA_ "GenSigSendType" SG_ 1707 HU_SVB_AMP 0;
BA_ "GenSigSwitchedByIgnition" SG_ 1707 PCM_SVB_TV 0;
BA_ "GenSigSendType" SG_ 1707 PCM_SVB_TV 0;
BA_ "GenSigSwitchedByIgnition" SG_ 1707 PCM_KD_Fehler_AMP 0;
BA_ "GenSigSendType" SG_ 1707 PCM_KD_Fehler_AMP 0;
BA_ "GenSigSwitchedByIgnition" SG_ 1707 PCM_KD_Fehler_TV 0;
BA_ "GenSigSendType" SG_ 1707 PCM_KD_Fehler_TV 0;
BA_ "GenSigSwitchedByIgnition" SG_ 1707 HU_PCMCDR 0;
BA_ "GenSigSendType" SG_ 1707 HU_PCMCDR 0;
BA_ "GenSigSwitchedByIgnition" SG_ 1707 HU_Topview_on_Anf 0;
BA_ "GenSigSendType" SG_ 1707 HU_Topview_on_Anf 3;
BA_ "GenSigSwitchedByIgnition" SG_ 1707 HU_KD_Fehler 0;
BA_ "GenSigSendType" SG_ 1707 HU_KD_Fehler 0;
BA_ "GenSigSwitchedByIgnition" SG_ 1339 QUER_Charisma_FahrPr 0;
BA_ "GenSigSendType" SG_ 1339 QUER_Charisma_FahrPr 3;
BA_ "GenSigSwitchedByIgnition" SG_ 1339 QUER_Charisma_Status 0;
BA_ "GenSigSendType" SG_ 1339 QUER_Charisma_Status 0;
BA_ "GenSigSwitchedByIgnition" SG_ 1339 QUER_Charisma_Umschaltung 0;
BA_ "GenSigSendType" SG_ 1339 QUER_Charisma_Umschaltung 3;
BA_ "GenSigSwitchedByIgnition" SG_ 1339 QS_St_Begrenzungsmoment 0;
BA_ "GenSigSendType" SG_ 1339 QS_St_Begrenzungsmoment 0;
BA_ "GenSigSwitchedByIgnition" SG_ 1339 QS_Symbol_Rear_Lock 0;
BA_ "GenSigSendType" SG_ 1339 QS_Symbol_Rear_Lock 0;
BA_ "GenSigSwitchedByIgnition" SG_ 1339 QS_Warntexte 0;
BA_ "GenSigSendType" SG_ 1339 QS_Warntexte 0;
BA_ "GenSigSwitchedByIgnition" SG_ 1611 RDK_System_Off 0;
BA_ "GenSigSendType" SG_ 1611 RDK_System_Off 0;
BA_ "GenSigSwitchedByIgnition" SG_ 1611 RDK_Warnungen 0;
BA_ "GenSigSendType" SG_ 1611 RDK_Warnungen 0;
BA_ "GenSigSwitchedByIgnition" SG_ 1611 RDK_FMVSS138_Lampe 0;
BA_ "GenSigSendType" SG_ 1611 RDK_FMVSS138_Lampe 0;
BA_ "GenSigSwitchedByIgnition" SG_ 1611 RDK_Druckwarnung_RdW 0;
BA_ "GenSigSendType" SG_ 1611 RDK_Druckwarnung_RdW 0;
BA_ "GenSigSwitchedByIgnition" SG_ 1611 RDK_FMVSS138_MIL 0;
BA_ "GenSigSendType" SG_ 1611 RDK_FMVSS138_MIL 0;
BA_ "GenSigSwitchedByIgnition" SG_ 1611 RDK_LF_aktiv 0;
BA_ "GenSigSendType" SG_ 1611 RDK_LF_aktiv 0;
BA_ "GenSigSwitchedByIgnition" SG_ 1611 RDK_Diff_Druck_VL 0;
BA_ "GenSigSendType" SG_ 1611 RDK_Diff_Druck_VL 0;
BA_ "GenSigSwitchedByIgnition" SG_ 1611 RDK_KD_Fehler 0;
BA_ "GenSigSendType" SG_ 1611 RDK_KD_Fehler 0;
BA_ "GenSigSwitchedByIgnition" SG_ 1611 RDK_Diff_Druck_VR 0;
BA_ "GenSigSendType" SG_ 1611 RDK_Diff_Druck_VR 0;
BA_ "GenSigSwitchedByIgnition" SG_ 1611 RDK_Diff_Druck_HL 0;
BA_ "GenSigSendType" SG_ 1611 RDK_Diff_Druck_HL 0;
BA_ "GenSigSwitchedByIgnition" SG_ 1611 RDK_Diff_Druck_HR 0;
BA_ "GenSigSendType" SG_ 1611 RDK_Diff_Druck_HR 0;
BA_ "GenSigSwitchedByIgnition" SG_ 1652 RDK_W_1_Reifen_VL 0;
BA_ "GenSigSendType" SG_ 1652 RDK_W_1_Reifen_VL 0;
BA_ "GenSigSwitchedByIgnition" SG_ 1652 RDK_W_2_Reifen_VL 0;
BA_ "GenSigSendType" SG_ 1652 RDK_W_2_Reifen_VL 0;
BA_ "GenSigSwitchedByIgnition" SG_ 1652 RDK_W_1_Reifen_VR 0;
BA_ "GenSigSendType" SG_ 1652 RDK_W_1_Reifen_VR 0;
BA_ "GenSigSwitchedByIgnition" SG_ 1652 RDK_W_2_Reifen_VR 0;
BA_ "GenSigSendType" SG_ 1652 RDK_W_2_Reifen_VR 0;
BA_ "GenSigSwitchedByIgnition" SG_ 1652 RDK_W_1_Reifen_HL 0;
BA_ "GenSigSendType" SG_ 1652 RDK_W_1_Reifen_HL 0;
BA_ "GenSigSwitchedByIgnition" SG_ 1652 RDK_W_2_Reifen_HL 0;
BA_ "GenSigSendType" SG_ 1652 RDK_W_2_Reifen_HL 0;
BA_ "GenSigSwitchedByIgnition" SG_ 1652 RDK_W_1_Reifen_HR 0;
BA_ "GenSigSendType" SG_ 1652 RDK_W_1_Reifen_HR 0;
BA_ "GenSigSwitchedByIgnition" SG_ 1652 RDK_W_2_Reifen_HR 0;
BA_ "GenSigSendType" SG_ 1652 RDK_W_2_Reifen_HR 0;
BA_ "GenSigSendType" SG_ 1652 RDK_Warnung_1 0;
BA_ "GenSigSendType" SG_ 1652 RDK_Warnung_2 0;
BA_ "GenSigSwitchedByIgnition" SG_ 1652 RDK_angelernt 0;
BA_ "GenSigSendType" SG_ 1652 RDK_angelernt 0;
BA_ "GenSigSwitchedByIgnition" SG_ 1652 RDK_Solldr_uebern 0;
BA_ "GenSigSendType" SG_ 1652 RDK_Solldr_uebern 3;
BA_ "GenSigSwitchedByIgnition" SG_ 1652 RDK_Text_1 0;
BA_ "GenSigSendType" SG_ 1652 RDK_Text_1 0;
BA_ "GenSigSwitchedByIgnition" SG_ 1652 RDK_Text_2 0;
BA_ "GenSigSendType" SG_ 1652 RDK_Text_2 0;
BA_ "GenSigSwitchedByIgnition" SG_ 1652 RDK_Text_3 0;
BA_ "GenSigSendType" SG_ 1652 RDK_Text_3 0;
BA_ "GenSigSwitchedByIgnition" SG_ 1652 RDK_Text_4 0;
BA_ "GenSigSendType" SG_ 1652 RDK_Text_4 0;
BA_ "GenSigSwitchedByIgnition" SG_ 1652 RDK_Text_5 0;
BA_ "GenSigSendType" SG_ 1652 RDK_Text_5 0;
BA_ "GenSigSwitchedByIgnition" SG_ 1652 RDK_Text_6 0;
BA_ "GenSigSendType" SG_ 1652 RDK_Text_6 0;
BA_ "GenSigSwitchedByIgnition" SG_ 1652 RDK_W_3_Reifendr_erh 0;
BA_ "GenSigSendType" SG_ 1652 RDK_W_3_Reifendr_erh 3;
BA_ "GenSigSwitchedByIgnition" SG_ 1651 RDK_Druck_VL_unkomp 0;
BA_ "GenSigSendType" SG_ 1651 RDK_Druck_VL_unkomp 3;
BA_ "GenSigSwitchedByIgnition" SG_ 1651 RDK_Druck_VR_unkomp 0;
BA_ "GenSigSendType" SG_ 1651 RDK_Druck_VR_unkomp 3;
BA_ "GenSigSwitchedByIgnition" SG_ 1651 RDK_Druck_HL_unkomp 0;
BA_ "GenSigSendType" SG_ 1651 RDK_Druck_HL_unkomp 3;
BA_ "GenSigSwitchedByIgnition" SG_ 1651 RDK_Druck_HR_unkomp 0;
BA_ "GenSigSendType" SG_ 1651 RDK_Druck_HR_unkomp 3;
BA_ "GenSigSwitchedByIgnition" SG_ 1651 RDK_R_Temp_VL 0;
BA_ "GenSigSendType" SG_ 1651 RDK_R_Temp_VL 0;
BA_ "GenSigSwitchedByIgnition" SG_ 1651 RDK_R_Temp_VR 0;
BA_ "GenSigSendType" SG_ 1651 RDK_R_Temp_VR 0;
BA_ "GenSigSwitchedByIgnition" SG_ 1651 RDK_R_Temp_HL 0;
BA_ "GenSigSendType" SG_ 1651 RDK_R_Temp_HL 0;
BA_ "GenSigSwitchedByIgnition" SG_ 1651 RDK_R_Temp_HR 0;
BA_ "GenSigSendType" SG_ 1651 RDK_R_Temp_HR 0;
BA_ "Fehlerwert" SG_ 1525 RW_RWDS_Lastprofil 2047;
BA_ "GenSigSwitchedByIgnition" SG_ 1525 RW_RWDS_Lastprofil 0;
BA_ "GenSigSendType" SG_ 1525 RW_RWDS_Lastprofil 0;
BA_ "Fehlerwert" SG_ 1525 RW_Gesamt_Reichweite 2047;
BA_ "GenSigSwitchedByIgnition" SG_ 1525 RW_Gesamt_Reichweite 0;
BA_ "GenSigStartValue" SG_ 1525 RW_Gesamt_Reichweite 2046;
BA_ "GenSigSendType" SG_ 1525 RW_Gesamt_Reichweite 0;
BA_ "GenSigSwitchedByIgnition" SG_ 1525 RW_Prim_Reichweitenverbrauch 0;
BA_ "GenSigStartValue" SG_ 1525 RW_Prim_Reichweitenverbrauch 2047;
BA_ "GenSigSendType" SG_ 1525 RW_Prim_Reichweitenverbrauch 0;
BA_ "GenSigSwitchedByIgnition" SG_ 1525 RW_Prim_Reichweitenv_Einheit 0;
BA_ "GenSigStartValue" SG_ 1525 RW_Prim_Reichweitenv_Einheit 3;
BA_ "GenSigSendType" SG_ 1525 RW_Prim_Reichweitenv_Einheit 0;
BA_ "Fehlerwert" SG_ 1525 RW_Primaer_Reichweite 2047;
BA_ "GenSigSwitchedByIgnition" SG_ 1525 RW_Primaer_Reichweite 0;
BA_ "GenSigStartValue" SG_ 1525 RW_Primaer_Reichweite 2046;
BA_ "GenSigSendType" SG_ 1525 RW_Primaer_Reichweite 0;
BA_ "Fehlerwert" SG_ 1527 RW_Sekundaer_Reichweite 2047;
BA_ "GenSigSwitchedByIgnition" SG_ 1527 RW_Sekundaer_Reichweite 0;
BA_ "GenSigStartValue" SG_ 1527 RW_Sekundaer_Reichweite 2046;
BA_ "GenSigSendType" SG_ 1527 RW_Sekundaer_Reichweite 0;
BA_ "GenSigSwitchedByIgnition" SG_ 1527 RW_Sek_Reichweitenv_Einheit 0;
BA_ "GenSigStartValue" SG_ 1527 RW_Sek_Reichweitenv_Einheit 3;
BA_ "GenSigSendType" SG_ 1527 RW_Sek_Reichweitenv_Einheit 0;
BA_ "GenSigSwitchedByIgnition" SG_ 1527 RW_Sek_Reichweitenverbrauch 0;
BA_ "GenSigStartValue" SG_ 1527 RW_Sek_Reichweitenverbrauch 2047;
BA_ "GenSigSendType" SG_ 1527 RW_Sek_Reichweitenverbrauch 0;
BA_ "GenSigSwitchedByIgnition" SG_ 1504 MD1_Position 0;
BA_ "GenSigSendType" SG_ 1504 MD1_Position 0;
BA_ "GenSigSwitchedByIgnition" SG_ 1504 MD1_Lage 0;
BA_ "GenSigSendType" SG_ 1504 MD1_Lage 0;
BA_ "GenSigSwitchedByIgnition" SG_ 1504 MD3_Position 0;
BA_ "GenSigSendType" SG_ 1504 MD3_Position 0;
BA_ "GenSigSwitchedByIgnition" SG_ 1504 MD3_Lage 0;
BA_ "GenSigSendType" SG_ 1504 MD3_Lage 0;
BA_ "GenSigSwitchedByIgnition" SG_ 1504 MRollo_Position 0;
BA_ "GenSigSendType" SG_ 1504 MRollo_Position 0;
BA_ "GenSigSwitchedByIgnition" SG_ 1504 MRollo_Lage 0;
BA_ "GenSigSendType" SG_ 1504 MRollo_Lage 0;
BA_ "GenSigSwitchedByIgnition" SG_ 1413 SI_Int_CAN_gespiegelt 0;
BA_ "GenSigSendType" SG_ 1413 SI_Int_CAN_gespiegelt 3;
BA_ "GenSigSwitchedByIgnition" SG_ 1413 SI_CAN_Komfort_Sleep 0;
BA_ "GenSigStartValue" SG_ 1413 SI_CAN_Komfort_Sleep 1;
BA_ "GenSigSendType" SG_ 1413 SI_CAN_Komfort_Sleep 3;
BA_ "GenSigSwitchedByIgnition" SG_ 1413 SI_CAN_Dashboard_Sleep 0;
BA_ "GenSigStartValue" SG_ 1413 SI_CAN_Dashboard_Sleep 1;
BA_ "GenSigSendType" SG_ 1413 SI_CAN_Dashboard_Sleep 3;
BA_ "GenSigSwitchedByIgnition" SG_ 1413 SI_CAN_Antrieb_Sleep 0;
BA_ "GenSigStartValue" SG_ 1413 SI_CAN_Antrieb_Sleep 1;
BA_ "GenSigSendType" SG_ 1413 SI_CAN_Antrieb_Sleep 3;
BA_ "GenSigSwitchedByIgnition" SG_ 1413 SI_Infotainment_Sleep 0;
BA_ "GenSigStartValue" SG_ 1413 SI_Infotainment_Sleep 1;
BA_ "GenSigSendType" SG_ 1413 SI_Infotainment_Sleep 3;
BA_ "GenSigSwitchedByIgnition" SG_ 1413 SI_CAN_Extended_Sleep 0;
BA_ "GenSigStartValue" SG_ 1413 SI_CAN_Extended_Sleep 1;
BA_ "GenSigSendType" SG_ 1413 SI_CAN_Extended_Sleep 3;
BA_ "GenSigSwitchedByIgnition" SG_ 1413 SI_Fahrwerk_Sleep 0;
BA_ "GenSigStartValue" SG_ 1413 SI_Fahrwerk_Sleep 1;
BA_ "GenSigSendType" SG_ 1413 SI_Fahrwerk_Sleep 3;
BA_ "GenSigSwitchedByIgnition" SG_ 1413 SI_Diagnose_Aktiv 0;
BA_ "GenSigSendType" SG_ 1413 SI_Diagnose_Aktiv 3;
BA_ "GenSigSwitchedByIgnition" SG_ 1413 SI_QRS_Mode 0;
BA_ "GenSigSendType" SG_ 1413 SI_QRS_Mode 3;
BA_ "GenSigSwitchedByIgnition" SG_ 1413 SI_T_Mode 0;
BA_ "GenSigSendType" SG_ 1413 SI_T_Mode 3;
BA_ "GenSigSwitchedByIgnition" SG_ 1413 SI_NWDF 0;
BA_ "GenSigSendType" SG_ 1413 SI_NWDF 3;
BA_ "GenSigSwitchedByIgnition" SG_ 1413 SI_NWDF_gueltig 0;
BA_ "GenSigFuncType" SG_ 1413 SI_NWDF_gueltig 8;
BA_ "GenSigSendType" SG_ 1413 SI_NWDF_gueltig 3;
BA_ "GenSigSwitchedByIgnition" SG_ 1413 SI_Sammelfehler 0;
BA_ "GenSigSendType" SG_ 1413 SI_Sammelfehler 3;
BA_ "GenSigSendType" SG_ 1413 GW_KD_Fehler 3;
BA_ "GenSigSwitchedByIgnition" SG_ 1413 SI_T_Schutz 0;
BA_ "GenSigSendType" SG_ 1413 SI_T_Schutz 3;
BA_ "GenSigSwitchedByIgnition" SG_ 1413 SI_MOST_Status 0;
BA_ "GenSigSendType" SG_ 1413 SI_MOST_Status 3;
BA_ "GenSigSwitchedByIgnition" SG_ 1413 SI_Sammel_SG_Fehler 0;
BA_ "GenSigStartValue" SG_ 1413 SI_Sammel_SG_Fehler 63;
BA_ "GenSigSendType" SG_ 1413 SI_Sammel_SG_Fehler 0;
BA_ "GenSigSwitchedByIgnition" SG_ 1413 SI_MO_WU 0;
BA_ "GenSigSendType" SG_ 1413 SI_MO_WU 3;
BA_ "GenSigSwitchedByIgnition" SG_ 786 TSK_03_CHK 0;
BA_ "GenSigFuncType" SG_ 786 TSK_03_CHK 3;
BA_ "GenSigSendType" SG_ 786 TSK_03_CHK 0;
BA_ "GenSigSwitchedByIgnition" SG_ 786 TSK_03_BZ 0;
BA_ "GenSigFuncType" SG_ 786 TSK_03_BZ 1;
BA_ "GenSigSendType" SG_ 786 TSK_03_BZ 0;
BA_ "GenSigSwitchedByIgnition" SG_ 786 FAS_Wunschgeschw 0;
BA_ "GenSigSendType" SG_ 786 FAS_Wunschgeschw 3;
BA_ "GenSigSwitchedByIgnition" SG_ 786 FAS_Status_Prim_Anz 0;
BA_ "GenSigSendType" SG_ 786 FAS_Status_Prim_Anz 3;
BA_ "GenSigSwitchedByIgnition" SG_ 786 FAS_Texte_Primaeranz 0;
BA_ "GenSigSendType" SG_ 786 FAS_Texte_Primaeranz 3;
BA_ "GenSigSwitchedByIgnition" SG_ 786 FAS_Status_Anzeige 0;
BA_ "GenSigSendType" SG_ 786 FAS_Status_Anzeige 3;
BA_ "GenSigSwitchedByIgnition" SG_ 1718 UH_Typ 0;
BA_ "GenSigFuncType" SG_ 1718 UH_Typ 8;
BA_ "GenSigSendType" SG_ 1718 UH_Typ 0;
BA_ "GenSigSwitchedByIgnition" SG_ 1718 UH_DLS 0;
BA_ "GenSigSendType" SG_ 1718 UH_DLS 0;
BA_ "GenSigSwitchedByIgnition" SG_ 1718 UH_Monat 0;
BA_ "GenSigSendType" SG_ 1718 UH_Monat 0;
BA_ "GenSigSwitchedByIgnition" SG_ 1718 UH_Jahr 0;
BA_ "GenSigSendType" SG_ 1718 UH_Jahr 0;
BA_ "GenSigSwitchedByIgnition" SG_ 1718 UH_Tag 0;
BA_ "GenSigSendType" SG_ 1718 UH_Tag 0;
BA_ "GenSigSwitchedByIgnition" SG_ 1718 UH_Stunde 0;
BA_ "GenSigSendType" SG_ 1718 UH_Stunde 0;
BA_ "GenSigSwitchedByIgnition" SG_ 1718 UH_Minute 0;
BA_ "GenSigSendType" SG_ 1718 UH_Minute 0;
BA_ "GenSigSwitchedByIgnition" SG_ 1718 UH_Sekunde 0;
BA_ "GenSigSendType" SG_ 1718 UH_Sekunde 0;
BA_ "GenSigSwitchedByIgnition" SG_ 1716 VIN_01_MUX 0;
BA_ "GenSigSendType" SG_ 1716 VIN_01_MUX 0;
BA_ "GenSigSwitchedByIgnition" SG_ 1716 KS_Geheimnis_1 0;
BA_ "GenSigSwitchedByIgnition" SG_ 1716 VIN_4 0;
BA_ "GenSigStartValue" SG_ 1716 VIN_4 45;
BA_ "GenSigSwitchedByIgnition" SG_ 1716 VIN_11 0;
BA_ "GenSigStartValue" SG_ 1716 VIN_11 45;
BA_ "GenSigSwitchedByIgnition" SG_ 1716 KS_Geheimnis_2 0;
BA_ "GenSigSwitchedByIgnition" SG_ 1716 VIN_5 0;
BA_ "GenSigStartValue" SG_ 1716 VIN_5 45;
BA_ "GenSigSwitchedByIgnition" SG_ 1716 VIN_12 0;
BA_ "GenSigStartValue" SG_ 1716 VIN_12 45;
BA_ "GenSigSwitchedByIgnition" SG_ 1716 KS_Geheimnis_3 0;
BA_ "GenSigSwitchedByIgnition" SG_ 1716 VIN_6 0;
BA_ "GenSigStartValue" SG_ 1716 VIN_6 45;
BA_ "GenSigSwitchedByIgnition" SG_ 1716 VIN_13 0;
BA_ "GenSigStartValue" SG_ 1716 VIN_13 45;
BA_ "GenSigSwitchedByIgnition" SG_ 1716 KS_Geheimnis_4 0;
BA_ "GenSigSwitchedByIgnition" SG_ 1716 VIN_7 0;
BA_ "GenSigStartValue" SG_ 1716 VIN_7 45;
BA_ "GenSigSwitchedByIgnition" SG_ 1716 VIN_14 0;
BA_ "GenSigStartValue" SG_ 1716 VIN_14 45;
BA_ "GenSigSwitchedByIgnition" SG_ 1716 VIN_1 0;
BA_ "GenSigStartValue" SG_ 1716 VIN_1 45;
BA_ "GenSigSwitchedByIgnition" SG_ 1716 VIN_8 0;
BA_ "GenSigStartValue" SG_ 1716 VIN_8 45;
BA_ "GenSigSwitchedByIgnition" SG_ 1716 VIN_15 0;
BA_ "GenSigStartValue" SG_ 1716 VIN_15 45;
BA_ "GenSigSwitchedByIgnition" SG_ 1716 VIN_2 0;
BA_ "GenSigStartValue" SG_ 1716 VIN_2 45;
BA_ "GenSigSwitchedByIgnition" SG_ 1716 VIN_9 0;
BA_ "GenSigStartValue" SG_ 1716 VIN_9 45;
BA_ "GenSigSwitchedByIgnition" SG_ 1716 VIN_16 0;
BA_ "GenSigStartValue" SG_ 1716 VIN_16 45;
BA_ "GenSigSwitchedByIgnition" SG_ 1716 VIN_3 0;
BA_ "GenSigStartValue" SG_ 1716 VIN_3 45;
BA_ "GenSigSwitchedByIgnition" SG_ 1716 VIN_10 0;
BA_ "GenSigStartValue" SG_ 1716 VIN_10 45;
BA_ "GenSigSwitchedByIgnition" SG_ 1716 VIN_17 0;
BA_ "GenSigStartValue" SG_ 1716 VIN_17 45;
BA_ "GenSigSwitchedByIgnition" SG_ 915 WBA_02_CHK 0;
BA_ "GenSigFuncType" SG_ 915 WBA_02_CHK 4;
BA_ "GenSigSendType" SG_ 915 WBA_02_CHK 0;
BA_ "GenSigSwitchedByIgnition" SG_ 915 WBA_02_BZ 0;
BA_ "GenSigFuncType" SG_ 915 WBA_02_BZ 1;
BA_ "GenSigSendType" SG_ 915 WBA_02_BZ 0;
BA_ "GenSigSwitchedByIgnition" SG_ 915 WBA_Senderkennung 0;
BA_ "GenSigSendType" SG_ 915 WBA_Senderkennung 3;
BA_ "GenSigSwitchedByIgnition" SG_ 915 WBA_Lampe_Shift_Lock 0;
BA_ "GenSigSwitchedByIgnition" SG_ 915 WBA_Schaltempf_verfbar 0;
BA_ "GenSigSwitchedByIgnition" SG_ 915 WBA_Effizienzmodus 0;
BA_ "GenSigSendType" SG_ 915 WBA_Effizienzmodus 3;
BA_ "GenSigSwitchedByIgnition" SG_ 915 WBA_Blinken 0;
BA_ "GenSigSwitchedByIgnition" SG_ 915 WBA_Getriebevariante 0;
BA_ "GenSigSwitchedByIgnition" SG_ 915 WBA_GE_Warnung 0;
BA_ "GenSigSendType" SG_ 915 WBA_GE_Warnung 3;
BA_ "GenSigSwitchedByIgnition" SG_ 915 WBA_Fahrstufe 0;
BA_ "GenSigSwitchedByIgnition" SG_ 915 WBA_Istgang 0;
BA_ "GenSigSwitchedByIgnition" SG_ 915 WBA_eing_Gang 0;
BA_ "GenSigStartValue" SG_ 915 WBA_eing_Gang 1;
BA_ "GenSigSwitchedByIgnition" SG_ 915 WBA_Sollgang 0;
BA_ "GenSigSwitchedByIgnition" SG_ 915 WBA_GE_Texte 0;
BA_ "GenSigSwitchedByIgnition" SG_ 915 WBA_Schaltschema_Aktiv 0;
BA_ "GenSigSwitchedByIgnition" SG_ 915 WH_Warnung 0;
BA_ "GenSigSwitchedByIgnition" SG_ 915 WBA_GE_Zusatzwarnungen 0;
BA_ "GenSigSwitchedByIgnition" SG_ 915 GE_Tipschaltempf_verfuegbar 0;
BA_ "GenSigFuncType" SG_ 915 GE_Tipschaltempf_verfuegbar 8;
BA_ "GenSigSwitchedByIgnition" SG_ 915 GE_Sollgang 0;
BA_ "GenSigSwitchedByIgnition" SG_ 1702 Wischer_vorne_aktiv 0;
BA_ "GenSigSendType" SG_ 1702 Wischer_vorne_aktiv 3;
BA_ "GenSigSwitchedByIgnition" SG_ 1702 Waschen_vorne_aktiv 0;
BA_ "GenSigSendType" SG_ 1702 Waschen_vorne_aktiv 3;
BA_ "GenSigSwitchedByIgnition" SG_ 1702 Wischer_vorne_Normal 0;
BA_ "GenSigSendType" SG_ 1702 Wischer_vorne_Normal 3;
BA_ "GenSigSwitchedByIgnition" SG_ 1702 Wischer_vorne_Schnell 0;
BA_ "GenSigSendType" SG_ 1702 Wischer_vorne_Schnell 3;
BA_ "GenSigSwitchedByIgnition" SG_ 1702 Wischer_vorne_Parklage 0;
BA_ "GenSigSendType" SG_ 1702 Wischer_vorne_Parklage 3;
BA_ "GenSigSwitchedByIgnition" SG_ 1702 WWSs_01_alt 0;
BA_ "GenSigFuncType" SG_ 1702 WWSs_01_alt 5;
BA_ "GenSigStartValue" SG_ 1702 WWSs_01_alt 1;
BA_ "GenSigSendType" SG_ 1702 WWSs_01_alt 3;
BA_ "GenSigSwitchedByIgnition" SG_ 1702 Wischer_vorne_defekt 0;
BA_ "GenSigSendType" SG_ 1702 Wischer_vorne_defekt 3;
BA_ "GenSigSwitchedByIgnition" SG_ 1702 Wischer_vorne_blockiert 0;
BA_ "GenSigSendType" SG_ 1702 Wischer_vorne_blockiert 3;
BA_ "GenSigSwitchedByIgnition" SG_ 1702 Wischer1_Wischgeschwindigkeit 0;
BA_ "GenSigStartValue" SG_ 1702 Wischer1_Wischgeschwindigkeit 62;
BA_ "GenSigSendType" SG_ 1702 Wischer1_Wischgeschwindigkeit 3;
BA_ "GenSigSwitchedByIgnition" SG_ 1702 BCM1_SRA_aktiv 0;
BA_ "GenSigSendType" SG_ 1702 BCM1_SRA_aktiv 3;
BA_ "Fehlerwert" SG_ 1602 WIV_Verschleissindex 65535;
BA_ "GenSigSwitchedByIgnition" SG_ 1602 WIV_Verschleissindex 0;
BA_ "GenSigSendType" SG_ 1602 WIV_Verschleissindex 3;
BA_ "Fehlerwert" SG_ 1602 WIV_Russindex 65535;
BA_ "GenSigSwitchedByIgnition" SG_ 1602 WIV_Russindex 0;
BA_ "GenSigSendType" SG_ 1602 WIV_Russindex 3;
BA_ "GenSigSwitchedByIgnition" SG_ 1602 WIV_t_min 0;
BA_ "GenSigStartValue" SG_ 1602 WIV_t_min 12;
BA_ "GenSigSendType" SG_ 1602 WIV_t_min 3;
BA_ "GenSigSwitchedByIgnition" SG_ 1602 WIV_t_max 0;
BA_ "GenSigStartValue" SG_ 1602 WIV_t_max 24;
BA_ "GenSigSendType" SG_ 1602 WIV_t_max 3;
BA_ "GenSigSwitchedByIgnition" SG_ 1602 WIV_W_min 0;
BA_ "GenSigStartValue" SG_ 1602 WIV_W_min 17;
BA_ "GenSigSendType" SG_ 1602 WIV_W_min 3;
BA_ "GenSigSwitchedByIgnition" SG_ 1602 WIV_W_max 0;
BA_ "GenSigStartValue" SG_ 1602 WIV_W_max 31;
BA_ "GenSigSendType" SG_ 1602 WIV_W_max 3;
BA_REL_ "GenSigTimeoutTime" BU_SG_REL_ Kombi_PAG_PF SG_ 391 MO_Tankbereitschaft_Status 1000;
BA_REL_ "GenSigTimeoutTime" BU_SG_REL_ Klima_PAG_PF SG_ 811 MO_FahrPr1_verfuegbar 500;
BA_REL_ "GenSigTimeoutTime" BU_SG_REL_ Klima_PAG_PF SG_ 811 MO_FahrPr2_verfuegbar 500;
BA_REL_ "GenSigTimeoutTime" BU_SG_REL_ Klima_PAG_PF SG_ 811 MO_FahrPr3_verfuegbar 500;
BA_REL_ "GenSigTimeoutTime" BU_SG_REL_ Klima_PAG_PF SG_ 811 MO_FahrPr4_verfuegbar 500;
BA_REL_ "GenSigTimeoutTime" BU_SG_REL_ Klima_PAG_PF SG_ 811 MO_FahrPr5_verfuegbar 500;
BA_REL_ "GenSigTimeoutTime" BU_SG_REL_ Klima_PAG_PF SG_ 811 MO_FahrPr6_verfuegbar 500;
BA_REL_ "GenSigTimeoutTime" BU_SG_REL_ Klima_PAG_PF SG_ 811 MO_FahrPr7_verfuegbar 500;
BA_REL_ "GenSigTimeoutTime" BU_SG_REL_ OCU_PAG_PF SG_ 305 Ladezustand 500;
BA_REL_ "GenSigTimeoutTime" BU_SG_REL_ Kombi_PAG_PF SG_ 305 MO_Powermeter 500;
BA_REL_ "GenSigTimeoutTime" BU_SG_REL_ Klima_PAG_PF SG_ 931 MO_StartStopp_Status 1000;
BA_REL_ "GenSigTimeoutTime" BU_SG_REL_ Kombi_PAG_PF SG_ 931 MO_StartStopp_Status 1000;
BA_REL_ "GenSigTimeoutTime" BU_SG_REL_ ADR_PAG_X2 SG_ 931 MO_StartStopp_Motorstopp 1000;
BA_REL_ "GenSigTimeoutTime" BU_SG_REL_ Klima_PAG_PF SG_ 931 MO_StartStopp_Motorstopp 1000;
BA_REL_ "GenSigTimeoutTime" BU_SG_REL_ Kombi_PAG_PF SG_ 931 MO_StartStopp_Motorstopp 1000;
BA_REL_ "GenSigTimeoutTime" BU_SG_REL_ Klima_PAG_PF SG_ 931 MO_StartStopp_Wiederstart 1000;
BA_REL_ "GenSigTimeoutTime" BU_SG_REL_ Klima_PAG_PF SG_ 931 MO_Ext_E_Fahrt_aktiv 1000;
BA_REL_ "GenSigTimeoutTime" BU_SG_REL_ ADR_PAG_X2 SG_ 1747 NM_CDR_PCM_Start_1 2000;
BA_REL_ "GenSigTimeoutTime" BU_SG_REL_ GW_App_PAG_PF SG_ 1747 NM_CDR_PCM_Start_1 2000;
BA_REL_ "GenSigTimeoutTime" BU_SG_REL_ Klima_PAG_PF SG_ 1747 NM_CDR_PCM_Start_1 2000;
BA_REL_ "GenSigTimeoutTime" BU_SG_REL_ Kombi_PAG_PF SG_ 1747 NM_CDR_PCM_Start_1 2000;
BA_REL_ "GenSigTimeoutTime" BU_SG_REL_ Miko_PAG_X2 SG_ 1747 NM_CDR_PCM_Start_1 2000;
BA_REL_ "GenSigTimeoutTime" BU_SG_REL_ OCU_PAG_PF SG_ 1747 NM_CDR_PCM_Start_1 2000;
BA_REL_ "GenSigTimeoutTime" BU_SG_REL_ RDK_High_PAG_PF SG_ 1747 NM_CDR_PCM_Start_1 2000;
BA_REL_ "GenSigTimeoutTime" BU_SG_REL_ ADR_PAG_X2 SG_ 1728 NMH_GW_Start_1 2000;
BA_REL_ "GenSigTimeoutTime" BU_SG_REL_ GW_App_PAG_PF SG_ 1728 NMH_GW_Start_1 2000;
BA_REL_ "GenSigTimeoutTime" BU_SG_REL_ Klima_PAG_PF SG_ 1728 NMH_GW_Start_1 2000;
BA_REL_ "GenSigTimeoutTime" BU_SG_REL_ Kombi_PAG_PF SG_ 1728 NMH_GW_Start_1 2000;
BA_REL_ "GenSigTimeoutTime" BU_SG_REL_ Miko_PAG_X2 SG_ 1728 NMH_GW_Start_1 2000;
BA_REL_ "GenSigTimeoutTime" BU_SG_REL_ OCU_PAG_PF SG_ 1728 NMH_GW_Start_1 2000;
BA_REL_ "GenSigTimeoutTime" BU_SG_REL_ RDK_High_PAG_PF SG_ 1728 NMH_GW_Start_1 2000;
BA_REL_ "GenSigTimeoutTime" BU_SG_REL_ ADR_PAG_X2 SG_ 1775 NMH_GSM_Start_1 2000;
BA_REL_ "GenSigTimeoutTime" BU_SG_REL_ GW_App_PAG_PF SG_ 1775 NMH_GSM_Start_1 2000;
BA_REL_ "GenSigTimeoutTime" BU_SG_REL_ Klima_PAG_PF SG_ 1775 NMH_GSM_Start_1 2000;
BA_REL_ "GenSigTimeoutTime" BU_SG_REL_ Kombi_PAG_PF SG_ 1775 NMH_GSM_Start_1 2000;
BA_REL_ "GenSigTimeoutTime" BU_SG_REL_ Miko_PAG_X2 SG_ 1775 NMH_GSM_Start_1 2000;
BA_REL_ "GenSigTimeoutTime" BU_SG_REL_ OCU_PAG_PF SG_ 1775 NMH_GSM_Start_1 2000;
BA_REL_ "GenSigTimeoutTime" BU_SG_REL_ RDK_High_PAG_PF SG_ 1775 NMH_GSM_Start_1 2000;
BA_REL_ "GenSigTimeoutTime" BU_SG_REL_ ADR_PAG_X2 SG_ 1772 NMH_KL_Start_1 2000;
BA_REL_ "GenSigTimeoutTime" BU_SG_REL_ GW_App_PAG_PF SG_ 1772 NMH_KL_Start_1 2000;
BA_REL_ "GenSigTimeoutTime" BU_SG_REL_ Klima_PAG_PF SG_ 1772 NMH_KL_Start_1 2000;
BA_REL_ "GenSigTimeoutTime" BU_SG_REL_ Kombi_PAG_PF SG_ 1772 NMH_KL_Start_1 2000;
BA_REL_ "GenSigTimeoutTime" BU_SG_REL_ Miko_PAG_X2 SG_ 1772 NMH_KL_Start_1 2000;
BA_REL_ "GenSigTimeoutTime" BU_SG_REL_ OCU_PAG_PF SG_ 1772 NMH_KL_Start_1 2000;
BA_REL_ "GenSigTimeoutTime" BU_SG_REL_ RDK_High_PAG_PF SG_ 1772 NMH_KL_Start_1 2000;
BA_REL_ "GenSigTimeoutTime" BU_SG_REL_ ADR_PAG_X2 SG_ 1735 NMH_KBI_Start_1 2000;
BA_REL_ "GenSigTimeoutTime" BU_SG_REL_ GW_App_PAG_PF SG_ 1735 NMH_KBI_Start_1 2000;
BA_REL_ "GenSigTimeoutTime" BU_SG_REL_ Klima_PAG_PF SG_ 1735 NMH_KBI_Start_1 2000;
BA_REL_ "GenSigTimeoutTime" BU_SG_REL_ Kombi_PAG_PF SG_ 1735 NMH_KBI_Start_1 2000;
BA_REL_ "GenSigTimeoutTime" BU_SG_REL_ Miko_PAG_X2 SG_ 1735 NMH_KBI_Start_1 2000;
BA_REL_ "GenSigTimeoutTime" BU_SG_REL_ OCU_PAG_PF SG_ 1735 NMH_KBI_Start_1 2000;
BA_REL_ "GenSigTimeoutTime" BU_SG_REL_ RDK_High_PAG_PF SG_ 1735 NMH_KBI_Start_1 2000;
BA_REL_ "GenSigTimeoutTime" BU_SG_REL_ ADR_PAG_X2 SG_ 1750 NMH_Miko_Start_1 2000;
BA_REL_ "GenSigTimeoutTime" BU_SG_REL_ GW_App_PAG_PF SG_ 1750 NMH_Miko_Start_1 2000;
BA_REL_ "GenSigTimeoutTime" BU_SG_REL_ Klima_PAG_PF SG_ 1750 NMH_Miko_Start_1 2000;
BA_REL_ "GenSigTimeoutTime" BU_SG_REL_ Kombi_PAG_PF SG_ 1750 NMH_Miko_Start_1 2000;
BA_REL_ "GenSigTimeoutTime" BU_SG_REL_ Miko_PAG_X2 SG_ 1750 NMH_Miko_Start_1 2000;
BA_REL_ "GenSigTimeoutTime" BU_SG_REL_ OCU_PAG_PF SG_ 1750 NMH_Miko_Start_1 2000;
BA_REL_ "GenSigTimeoutTime" BU_SG_REL_ RDK_High_PAG_PF SG_ 1750 NMH_Miko_Start_1 2000;
BA_REL_ "GenSigTimeoutTime" BU_SG_REL_ ADR_PAG_X2 SG_ 1774 NM_RDK_Start_1 2000;
BA_REL_ "GenSigTimeoutTime" BU_SG_REL_ GW_App_PAG_PF SG_ 1774 NM_RDK_Start_1 2000;
BA_REL_ "GenSigTimeoutTime" BU_SG_REL_ Klima_PAG_PF SG_ 1774 NM_RDK_Start_1 2000;
BA_REL_ "GenSigTimeoutTime" BU_SG_REL_ Kombi_PAG_PF SG_ 1774 NM_RDK_Start_1 2000;
BA_REL_ "GenSigTimeoutTime" BU_SG_REL_ Miko_PAG_X2 SG_ 1774 NM_RDK_Start_1 2000;
BA_REL_ "GenSigTimeoutTime" BU_SG_REL_ OCU_PAG_PF SG_ 1774 NM_RDK_Start_1 2000;
BA_REL_ "GenSigTimeoutTime" BU_SG_REL_ RDK_High_PAG_PF SG_ 1774 NM_RDK_Start_1 2000;
BA_REL_ "GenSigTimeoutTime" BU_SG_REL_ ADR_PAG_X2 SG_ 1156 NPM_ForceShutdown 5000;
BA_REL_ "GenSigTimeoutTime" BU_SG_REL_ Klima_PAG_PF SG_ 1156 NPM_ForceShutdown 5000;
BA_REL_ "GenSigTimeoutTime" BU_SG_REL_ Kombi_PAG_PF SG_ 1156 NPM_ForceShutdown 5000;
BA_REL_ "GenSigTimeoutTime" BU_SG_REL_ Miko_PAG_X2 SG_ 1156 NPM_ForceShutdown 5000;
BA_REL_ "GenSigTimeoutTime" BU_SG_REL_ RDK_High_PAG_PF SG_ 1156 NPM_ForceShutdown 5000;
BA_REL_ "GenSigTimeoutTime" BU_SG_REL_ ADR_PAG_X2 SG_ 1156 NPM_PreventWakeup 5000;
BA_REL_ "GenSigTimeoutTime" BU_SG_REL_ Klima_PAG_PF SG_ 1156 NPM_PreventWakeup 5000;
BA_REL_ "GenSigTimeoutTime" BU_SG_REL_ Kombi_PAG_PF SG_ 1156 NPM_PreventWakeup 5000;
BA_REL_ "GenSigTimeoutTime" BU_SG_REL_ Miko_PAG_X2 SG_ 1156 NPM_PreventWakeup 5000;
BA_REL_ "GenSigTimeoutTime" BU_SG_REL_ RDK_High_PAG_PF SG_ 1156 NPM_PreventWakeup 5000;
BA_REL_ "GenSigTimeoutTime" BU_SG_REL_ ADR_PAG_X2 SG_ 1156 NPM_directAdressing 5000;
BA_REL_ "GenSigTimeoutTime" BU_SG_REL_ Klima_PAG_PF SG_ 1156 NPM_directAdressing 5000;
BA_REL_ "GenSigTimeoutTime" BU_SG_REL_ Kombi_PAG_PF SG_ 1156 NPM_directAdressing 5000;
BA_REL_ "GenSigTimeoutTime" BU_SG_REL_ Miko_PAG_X2 SG_ 1156 NPM_directAdressing 5000;
BA_REL_ "GenSigTimeoutTime" BU_SG_REL_ RDK_High_PAG_PF SG_ 1156 NPM_directAdressing 5000;
BA_REL_ "GenSigTimeoutTime" BU_SG_REL_ RDK_High_PAG_PF SG_ 1156 NPM_FS_RDK 5000;
BA_REL_ "GenSigTimeoutTime" BU_SG_REL_ Kombi_PAG_PF SG_ 1156 NPM_FS_KMB 5000;
BA_REL_ "GenSigTimeoutTime" BU_SG_REL_ Miko_PAG_X2 SG_ 1156 NPM_FS_Miko 5000;
BA_REL_ "GenSigTimeoutTime" BU_SG_REL_ ADR_PAG_X2 SG_ 1156 NPM_FS_HU 5000;
BA_REL_ "GenSigTimeoutTime" BU_SG_REL_ Klima_PAG_PF SG_ 1156 NPM_FS_BKE 5000;
BA_REL_ "GenSigTimeoutTime" BU_SG_REL_ RDK_High_PAG_PF SG_ 1156 NPM_PrWu_RDK 5000;
BA_REL_ "GenSigTimeoutTime" BU_SG_REL_ Kombi_PAG_PF SG_ 1156 NPM_PrWu_KMB 5000;
BA_REL_ "GenSigTimeoutTime" BU_SG_REL_ Miko_PAG_X2 SG_ 1156 NPM_PrWu_Miko 5000;
BA_REL_ "GenSigTimeoutTime" BU_SG_REL_ ADR_PAG_X2 SG_ 1156 NPM_PrWu_HU 5000;
BA_REL_ "GenSigTimeoutTime" BU_SG_REL_ Klima_PAG_PF SG_ 1156 NPM_PrWu_BKE 5000;
BA_REL_ "GenSigTimeoutTime" BU_SG_REL_ Kombi_PAG_PF SG_ 1337 PCM_Limit_Info 2500;
BA_REL_ "GenSigTimeoutTime" BU_SG_REL_ Kombi_PAG_PF SG_ 1337 PCM_Kompass 2500;
BA_REL_ "GenSigTimeoutTime" BU_SG_REL_ Kombi_PAG_PF SG_ 1337 PCM_Elev_Einheit 2500;
BA_REL_ "GenSigTimeoutTime" BU_SG_REL_ OCU_PAG_PF SG_ 1337 PCM_Elev_Einheit 2500;
BA_REL_ "GenSigTimeoutTime" BU_SG_REL_ Kombi_PAG_PF SG_ 1337 PCM_Entfernung_Kurve 2500;
BA_REL_ "GenSigTimeoutTime" BU_SG_REL_ OCU_PAG_PF SG_ 1530 GPS_N_Grad 5000;
BA_REL_ "GenSigTimeoutTime" BU_SG_REL_ OCU_PAG_PF SG_ 1530 GPS_E_Grad 5000;
BA_REL_ "GenSigTimeoutTime" BU_SG_REL_ OCU_PAG_PF SG_ 1530 GPS_elev 5000;
BA_REL_ "GenSigTimeoutTime" BU_SG_REL_ Kombi_PAG_PF SG_ 1707 PCM_Std 2000;
BA_REL_ "GenSigTimeoutTime" BU_SG_REL_ Kombi_PAG_PF SG_ 1707 PCM_Min 2000;
BA_REL_ "GenSigTimeoutTime" BU_SG_REL_ Kombi_PAG_PF SG_ 1707 PCM_Sek 2000;
BA_REL_ "GenSigTimeoutTime" BU_SG_REL_ Kombi_PAG_PF SG_ 1707 PCM_Zeitzone 2000;
BA_REL_ "GenSigTimeoutTime" BU_SG_REL_ Kombi_PAG_PF SG_ 1707 PCM_Zeitzone_Vorzeichen 2000;
BA_REL_ "GenSigTimeoutTime" BU_SG_REL_ Kombi_PAG_PF SG_ 1707 PCM_Uebern 2000;
BA_REL_ "GenSigTimeoutTime" BU_SG_REL_ Kombi_PAG_PF SG_ 1707 PCM_Tag 2000;
BA_REL_ "GenSigTimeoutTime" BU_SG_REL_ Kombi_PAG_PF SG_ 1707 PCM_Mon 2000;
BA_REL_ "GenSigTimeoutTime" BU_SG_REL_ Kombi_PAG_PF SG_ 1707 PCM_JJ 2000;
BA_REL_ "GenSigTimeoutTime" BU_SG_REL_ Kombi_PAG_PF SG_ 1707 PCM_Sommerzeit 2000;
BA_REL_ "GenSigTimeoutTime" BU_SG_REL_ Kombi_PAG_PF SG_ 1707 PCM_Reset_Trip_1 2000;
BA_REL_ "GenSigTimeoutTime" BU_SG_REL_ Kombi_PAG_PF SG_ 1707 PCM_Reset_Trip_2 2000;
BA_REL_ "GenSigTimeoutTime" BU_SG_REL_ Klima_PAG_PF SG_ 1707 HU_Fotosensor 2000;
BA_REL_ "GenSigTimeoutTime" BU_SG_REL_ Kombi_PAG_PF SG_ 1707 HU_Fotosensor 2000;
BA_REL_ "GenSigTimeoutTime" BU_SG_REL_ Miko_PAG_X2 SG_ 1707 HU_Fotosensor 2000;
BA_REL_ "GenSigTimeoutTime" BU_SG_REL_ GW_App_PAG_PF SG_ 1707 HU_PCMCDR 2000;
BA_REL_ "GenSigTimeoutTime" BU_SG_REL_ GW_App_PAG_PF SG_ 1707 HU_KD_Fehler 2000;
BA_REL_ "GenSigTimeoutTime" BU_SG_REL_ Kombi_PAG_PF SG_ 1339 QS_Warntexte 5000;
BA_REL_ "GenSigTimeoutTime" BU_SG_REL_ Kombi_PAG_PF SG_ 1339 QS_Warntexte 5000;
BA_REL_ "GenSigTimeoutTime" BU_SG_REL_ Kombi_PAG_PF SG_ 1611 RDK_Diff_Druck_VL 5000;
BA_REL_ "GenSigTimeoutTime" BU_SG_REL_ GW_App_PAG_PF SG_ 1611 RDK_KD_Fehler 5000;
BA_REL_ "GenSigTimeoutTime" BU_SG_REL_ Kombi_PAG_PF SG_ 1611 RDK_Diff_Druck_VR 5000;
BA_REL_ "GenSigTimeoutTime" BU_SG_REL_ Kombi_PAG_PF SG_ 1611 RDK_Diff_Druck_HL 5000;
BA_REL_ "GenSigTimeoutTime" BU_SG_REL_ Kombi_PAG_PF SG_ 1611 RDK_Diff_Druck_HR 5000;
BA_REL_ "GenSigTimeoutTime" BU_SG_REL_ Kombi_PAG_PF SG_ 1652 RDK_W_1_Reifen_VL 5000;
BA_REL_ "GenSigTimeoutTime" BU_SG_REL_ Kombi_PAG_PF SG_ 1652 RDK_W_2_Reifen_VL 5000;
BA_REL_ "GenSigTimeoutTime" BU_SG_REL_ Kombi_PAG_PF SG_ 1652 RDK_W_1_Reifen_VR 5000;
BA_REL_ "GenSigTimeoutTime" BU_SG_REL_ Kombi_PAG_PF SG_ 1652 RDK_W_2_Reifen_VR 5000;
BA_REL_ "GenSigTimeoutTime" BU_SG_REL_ Kombi_PAG_PF SG_ 1652 RDK_W_1_Reifen_HL 5000;
BA_REL_ "GenSigTimeoutTime" BU_SG_REL_ Kombi_PAG_PF SG_ 1652 RDK_W_2_Reifen_HL 5000;
BA_REL_ "GenSigTimeoutTime" BU_SG_REL_ Kombi_PAG_PF SG_ 1652 RDK_W_1_Reifen_HR 5000;
BA_REL_ "GenSigTimeoutTime" BU_SG_REL_ Kombi_PAG_PF SG_ 1652 RDK_W_2_Reifen_HR 5000;
BA_REL_ "GenSigTimeoutTime" BU_SG_REL_ ADR_PAG_X2 SG_ 1652 RDK_angelernt 5000;
BA_REL_ "GenSigTimeoutTime" BU_SG_REL_ Kombi_PAG_PF SG_ 1652 RDK_Solldr_uebern 5000;
BA_REL_ "GenSigTimeoutTime" BU_SG_REL_ Kombi_PAG_PF SG_ 1652 RDK_Text_1 5000;
BA_REL_ "GenSigTimeoutTime" BU_SG_REL_ Kombi_PAG_PF SG_ 1652 RDK_Text_2 5000;
BA_REL_ "GenSigTimeoutTime" BU_SG_REL_ Kombi_PAG_PF SG_ 1652 RDK_Text_3 5000;
BA_REL_ "GenSigTimeoutTime" BU_SG_REL_ Kombi_PAG_PF SG_ 1652 RDK_Text_4 5000;
BA_REL_ "GenSigTimeoutTime" BU_SG_REL_ Kombi_PAG_PF SG_ 1652 RDK_Text_5 5000;
BA_REL_ "GenSigTimeoutTime" BU_SG_REL_ Kombi_PAG_PF SG_ 1652 RDK_Text_5 5000;
BA_REL_ "GenSigTimeoutTime" BU_SG_REL_ Kombi_PAG_PF SG_ 1652 RDK_Text_6 5000;
BA_REL_ "GenSigTimeoutTime" BU_SG_REL_ Kombi_PAG_PF SG_ 1652 RDK_W_3_Reifendr_erh 5000;
BA_REL_ "GenSigTimeoutTime" BU_SG_REL_ Kombi_PAG_PF SG_ 1651 RDK_Druck_VL_unkomp 5000;
BA_REL_ "GenSigTimeoutTime" BU_SG_REL_ Kombi_PAG_PF SG_ 1651 RDK_Druck_VR_unkomp 5000;
BA_REL_ "GenSigTimeoutTime" BU_SG_REL_ Kombi_PAG_PF SG_ 1651 RDK_Druck_HL_unkomp 5000;
BA_REL_ "GenSigTimeoutTime" BU_SG_REL_ Kombi_PAG_PF SG_ 1651 RDK_Druck_HR_unkomp 5000;
BA_REL_ "GenSigTimeoutTime" BU_SG_REL_ Kombi_PAG_PF SG_ 1525 RW_Gesamt_Reichweite 5000;
BA_REL_ "GenSigTimeoutTime" BU_SG_REL_ Kombi_PAG_PF SG_ 1527 RW_Sekundaer_Reichweite 5000;
BA_REL_ "GenSigTimeoutTime" BU_SG_REL_ Klima_PAG_PF SG_ 1504 MD1_Position 5000;
BA_REL_ "GenSigTimeoutTime" BU_SG_REL_ Klima_PAG_PF SG_ 1504 MD1_Lage 5000;
BA_REL_ "GenSigTimeoutTime" BU_SG_REL_ Klima_PAG_PF SG_ 1504 MD3_Position 5000;
BA_REL_ "GenSigTimeoutTime" BU_SG_REL_ ADR_PAG_X2 SG_ 1413 SI_CAN_Komfort_Sleep 5000;
BA_REL_ "GenSigTimeoutTime" BU_SG_REL_ Kombi_PAG_PF SG_ 1413 SI_CAN_Komfort_Sleep 5000;
BA_REL_ "GenSigTimeoutTime" BU_SG_REL_ ADR_PAG_X2 SG_ 1413 SI_CAN_Dashboard_Sleep 5000;
BA_REL_ "GenSigTimeoutTime" BU_SG_REL_ ADR_PAG_X2 SG_ 1413 SI_CAN_Antrieb_Sleep 5000;
BA_REL_ "GenSigTimeoutTime" BU_SG_REL_ ADR_PAG_X2 SG_ 1413 SI_CAN_Extended_Sleep 5000;
BA_REL_ "GenSigTimeoutTime" BU_SG_REL_ Kombi_PAG_PF SG_ 1413 SI_CAN_Extended_Sleep 5000;
BA_REL_ "GenSigTimeoutTime" BU_SG_REL_ ADR_PAG_X2 SG_ 1413 SI_Fahrwerk_Sleep 5000;
BA_REL_ "GenSigTimeoutTime" BU_SG_REL_ OCU_PAG_PF SG_ 1413 SI_QRS_Mode 5000;
BA_REL_ "GenSigTimeoutTime" BU_SG_REL_ RDK_High_PAG_PF SG_ 1413 SI_QRS_Mode 5000;
BA_REL_ "GenSigTimeoutTime" BU_SG_REL_ ADR_PAG_X2 SG_ 1413 SI_T_Mode 5000;
BA_REL_ "GenSigTimeoutTime" BU_SG_REL_ Klima_PAG_PF SG_ 1413 SI_T_Mode 5000;
BA_REL_ "GenSigTimeoutTime" BU_SG_REL_ Kombi_PAG_PF SG_ 1413 SI_T_Mode 5000;
BA_REL_ "GenSigTimeoutTime" BU_SG_REL_ OCU_PAG_PF SG_ 1413 SI_T_Mode 5000;
BA_REL_ "GenSigTimeoutTime" BU_SG_REL_ RDK_High_PAG_PF SG_ 1413 SI_T_Mode 5000;
BA_REL_ "GenSigTimeoutTime" BU_SG_REL_ ADR_PAG_X2 SG_ 1413 SI_NWDF 5000;
BA_REL_ "GenSigTimeoutTime" BU_SG_REL_ Klima_PAG_PF SG_ 1413 SI_NWDF 5000;
BA_REL_ "GenSigTimeoutTime" BU_SG_REL_ Kombi_PAG_PF SG_ 1413 SI_NWDF 5000;
BA_REL_ "GenSigTimeoutTime" BU_SG_REL_ Miko_PAG_X2 SG_ 1413 SI_NWDF 5000;
BA_REL_ "GenSigTimeoutTime" BU_SG_REL_ OCU_PAG_PF SG_ 1413 SI_NWDF 5000;
BA_REL_ "GenSigTimeoutTime" BU_SG_REL_ RDK_High_PAG_PF SG_ 1413 SI_NWDF 5000;
BA_REL_ "GenSigTimeoutTime" BU_SG_REL_ ADR_PAG_X2 SG_ 1413 SI_NWDF_gueltig 5000;
BA_REL_ "GenSigTimeoutTime" BU_SG_REL_ Klima_PAG_PF SG_ 1413 SI_NWDF_gueltig 5000;
BA_REL_ "GenSigTimeoutTime" BU_SG_REL_ Kombi_PAG_PF SG_ 1413 SI_NWDF_gueltig 5000;
BA_REL_ "GenSigTimeoutTime" BU_SG_REL_ Miko_PAG_X2 SG_ 1413 SI_NWDF_gueltig 5000;
BA_REL_ "GenSigTimeoutTime" BU_SG_REL_ OCU_PAG_PF SG_ 1413 SI_NWDF_gueltig 5000;
BA_REL_ "GenSigTimeoutTime" BU_SG_REL_ RDK_High_PAG_PF SG_ 1413 SI_NWDF_gueltig 5000;
BA_REL_ "GenSigTimeoutTime" BU_SG_REL_ Kombi_PAG_PF SG_ 786 TSK_03_CHK 500;
BA_REL_ "GenSigTimeoutTime" BU_SG_REL_ Kombi_PAG_PF SG_ 786 TSK_03_BZ 500;
BA_REL_ "GenSigTimeoutTime" BU_SG_REL_ Kombi_PAG_PF SG_ 786 FAS_Wunschgeschw 500;
BA_REL_ "GenSigTimeoutTime" BU_SG_REL_ Kombi_PAG_PF SG_ 786 FAS_Texte_Primaeranz 500;
BA_REL_ "GenSigTimeoutTime" BU_SG_REL_ Kombi_PAG_PF SG_ 786 FAS_Status_Anzeige 500;
BA_REL_ "GenSigTimeoutTime" BU_SG_REL_ GW_App_PAG_PF SG_ 1718 UH_Monat 5000;
BA_REL_ "GenSigTimeoutTime" BU_SG_REL_ GW_App_PAG_PF SG_ 1718 UH_Jahr 5000;
BA_REL_ "GenSigTimeoutTime" BU_SG_REL_ GW_App_PAG_PF SG_ 1718 UH_Tag 5000;
BA_REL_ "GenSigTimeoutTime" BU_SG_REL_ GW_App_PAG_PF SG_ 1718 UH_Stunde 5000;
BA_REL_ "GenSigTimeoutTime" BU_SG_REL_ GW_App_PAG_PF SG_ 1718 UH_Minute 5000;
BA_REL_ "GenSigTimeoutTime" BU_SG_REL_ GW_App_PAG_PF SG_ 1718 UH_Sekunde 5000;
BA_REL_ "GenSigTimeoutTime" BU_SG_REL_ ADR_PAG_X2 SG_ 1716 VIN_01_MUX 2000;
BA_REL_ "GenSigTimeoutTime" BU_SG_REL_ Klima_PAG_PF SG_ 1716 VIN_01_MUX 2000;
BA_REL_ "GenSigTimeoutTime" BU_SG_REL_ OCU_PAG_PF SG_ 1716 VIN_01_MUX 2000;
BA_REL_ "GenSigTimeoutTime" BU_SG_REL_ ADR_PAG_X2 SG_ 1716 VIN_4 2000;
BA_REL_ "GenSigTimeoutTime" BU_SG_REL_ Klima_PAG_PF SG_ 1716 VIN_4 2000;
BA_REL_ "GenSigTimeoutTime" BU_SG_REL_ OCU_PAG_PF SG_ 1716 VIN_4 2000;
BA_REL_ "GenSigTimeoutTime" BU_SG_REL_ ADR_PAG_X2 SG_ 1716 VIN_11 2000;
BA_REL_ "GenSigTimeoutTime" BU_SG_REL_ Klima_PAG_PF SG_ 1716 VIN_11 2000;
BA_REL_ "GenSigTimeoutTime" BU_SG_REL_ OCU_PAG_PF SG_ 1716 VIN_11 2000;
BA_REL_ "GenSigTimeoutTime" BU_SG_REL_ ADR_PAG_X2 SG_ 1716 VIN_5 2000;
BA_REL_ "GenSigTimeoutTime" BU_SG_REL_ Klima_PAG_PF SG_ 1716 VIN_5 2000;
BA_REL_ "GenSigTimeoutTime" BU_SG_REL_ OCU_PAG_PF SG_ 1716 VIN_5 2000;
BA_REL_ "GenSigTimeoutTime" BU_SG_REL_ ADR_PAG_X2 SG_ 1716 VIN_12 2000;
BA_REL_ "GenSigTimeoutTime" BU_SG_REL_ Klima_PAG_PF SG_ 1716 VIN_12 2000;
BA_REL_ "GenSigTimeoutTime" BU_SG_REL_ OCU_PAG_PF SG_ 1716 VIN_12 2000;
BA_REL_ "GenSigTimeoutTime" BU_SG_REL_ ADR_PAG_X2 SG_ 1716 VIN_6 2000;
BA_REL_ "GenSigTimeoutTime" BU_SG_REL_ Klima_PAG_PF SG_ 1716 VIN_6 2000;
BA_REL_ "GenSigTimeoutTime" BU_SG_REL_ OCU_PAG_PF SG_ 1716 VIN_6 2000;
BA_REL_ "GenSigTimeoutTime" BU_SG_REL_ ADR_PAG_X2 SG_ 1716 VIN_13 2000;
BA_REL_ "GenSigTimeoutTime" BU_SG_REL_ Klima_PAG_PF SG_ 1716 VIN_13 2000;
BA_REL_ "GenSigTimeoutTime" BU_SG_REL_ OCU_PAG_PF SG_ 1716 VIN_13 2000;
BA_REL_ "GenSigTimeoutTime" BU_SG_REL_ ADR_PAG_X2 SG_ 1716 VIN_7 2000;
BA_REL_ "GenSigTimeoutTime" BU_SG_REL_ Klima_PAG_PF SG_ 1716 VIN_7 2000;
BA_REL_ "GenSigTimeoutTime" BU_SG_REL_ OCU_PAG_PF SG_ 1716 VIN_7 2000;
BA_REL_ "GenSigTimeoutTime" BU_SG_REL_ ADR_PAG_X2 SG_ 1716 VIN_14 2000;
BA_REL_ "GenSigTimeoutTime" BU_SG_REL_ Klima_PAG_PF SG_ 1716 VIN_14 2000;
BA_REL_ "GenSigTimeoutTime" BU_SG_REL_ OCU_PAG_PF SG_ 1716 VIN_14 2000;
BA_REL_ "GenSigTimeoutTime" BU_SG_REL_ ADR_PAG_X2 SG_ 1716 VIN_1 2000;
BA_REL_ "GenSigTimeoutTime" BU_SG_REL_ Klima_PAG_PF SG_ 1716 VIN_1 2000;
BA_REL_ "GenSigTimeoutTime" BU_SG_REL_ OCU_PAG_PF SG_ 1716 VIN_1 2000;
BA_REL_ "GenSigTimeoutTime" BU_SG_REL_ ADR_PAG_X2 SG_ 1716 VIN_8 2000;
BA_REL_ "GenSigTimeoutTime" BU_SG_REL_ Klima_PAG_PF SG_ 1716 VIN_8 2000;
BA_REL_ "GenSigTimeoutTime" BU_SG_REL_ OCU_PAG_PF SG_ 1716 VIN_8 2000;
BA_REL_ "GenSigTimeoutTime" BU_SG_REL_ ADR_PAG_X2 SG_ 1716 VIN_15 2000;
BA_REL_ "GenSigTimeoutTime" BU_SG_REL_ Klima_PAG_PF SG_ 1716 VIN_15 2000;
BA_REL_ "GenSigTimeoutTime" BU_SG_REL_ OCU_PAG_PF SG_ 1716 VIN_15 2000;
BA_REL_ "GenSigTimeoutTime" BU_SG_REL_ ADR_PAG_X2 SG_ 1716 VIN_2 2000;
BA_REL_ "GenSigTimeoutTime" BU_SG_REL_ Klima_PAG_PF SG_ 1716 VIN_2 2000;
BA_REL_ "GenSigTimeoutTime" BU_SG_REL_ OCU_PAG_PF SG_ 1716 VIN_2 2000;
BA_REL_ "GenSigTimeoutTime" BU_SG_REL_ ADR_PAG_X2 SG_ 1716 VIN_9 2000;
BA_REL_ "GenSigTimeoutTime" BU_SG_REL_ Klima_PAG_PF SG_ 1716 VIN_9 2000;
BA_REL_ "GenSigTimeoutTime" BU_SG_REL_ OCU_PAG_PF SG_ 1716 VIN_9 2000;
BA_REL_ "GenSigTimeoutTime" BU_SG_REL_ ADR_PAG_X2 SG_ 1716 VIN_16 2000;
BA_REL_ "GenSigTimeoutTime" BU_SG_REL_ Klima_PAG_PF SG_ 1716 VIN_16 2000;
BA_REL_ "GenSigTimeoutTime" BU_SG_REL_ OCU_PAG_PF SG_ 1716 VIN_16 2000;
BA_REL_ "GenSigTimeoutTime" BU_SG_REL_ ADR_PAG_X2 SG_ 1716 VIN_3 2000;
BA_REL_ "GenSigTimeoutTime" BU_SG_REL_ Klima_PAG_PF SG_ 1716 VIN_3 2000;
BA_REL_ "GenSigTimeoutTime" BU_SG_REL_ OCU_PAG_PF SG_ 1716 VIN_3 2000;
BA_REL_ "GenSigTimeoutTime" BU_SG_REL_ ADR_PAG_X2 SG_ 1716 VIN_10 2000;
BA_REL_ "GenSigTimeoutTime" BU_SG_REL_ Klima_PAG_PF SG_ 1716 VIN_10 2000;
BA_REL_ "GenSigTimeoutTime" BU_SG_REL_ OCU_PAG_PF SG_ 1716 VIN_10 2000;
BA_REL_ "GenSigTimeoutTime" BU_SG_REL_ ADR_PAG_X2 SG_ 1716 VIN_17 2000;
BA_REL_ "GenSigTimeoutTime" BU_SG_REL_ Klima_PAG_PF SG_ 1716 VIN_17 2000;
BA_REL_ "GenSigTimeoutTime" BU_SG_REL_ OCU_PAG_PF SG_ 1716 VIN_17 2000;
BA_REL_ "GenSigTimeoutTime" BU_SG_REL_ Kombi_PAG_PF SG_ 915 WBA_02_CHK 800;
BA_REL_ "GenSigTimeoutTime" BU_SG_REL_ Kombi_PAG_PF SG_ 915 WBA_02_BZ 800;
BA_REL_ "GenSigTimeoutTime" BU_SG_REL_ Kombi_PAG_PF SG_ 915 WBA_Senderkennung 800;
BA_REL_ "GenSigTimeoutTime" BU_SG_REL_ Kombi_PAG_PF SG_ 915 WBA_Blinken 800;
BA_REL_ "GenSigTimeoutTime" BU_SG_REL_ Kombi_PAG_PF SG_ 915 WBA_GE_Warnung 800;
BA_REL_ "GenSigTimeoutTime" BU_SG_REL_ Kombi_PAG_PF SG_ 915 WBA_Fahrstufe 800;
BA_REL_ "GenSigTimeoutTime" BU_SG_REL_ Kombi_PAG_PF SG_ 915 WBA_eing_Gang 800;
BA_REL_ "GenSigTimeoutTime" BU_SG_REL_ Kombi_PAG_PF SG_ 915 WBA_GE_Texte 800;
BA_REL_ "GenSigTimeoutTime" BU_SG_REL_ Klima_PAG_PF SG_ 1702 Wischer_vorne_aktiv 5000;
BA_REL_ "GenSigTimeoutTime" BU_SG_REL_ Klima_PAG_PF SG_ 1702 Waschen_vorne_aktiv 5000;
BA_REL_ "GenSigTimeoutTime" BU_SG_REL_ Klima_PAG_PF SG_ 1702 Wischer_vorne_Normal 5000;
BA_REL_ "GenSigTimeoutTime" BU_SG_REL_ Klima_PAG_PF SG_ 1702 Wischer_vorne_Schnell 5000;
BA_REL_ "GenSigTimeoutTime" BU_SG_REL_ Kombi_PAG_PF SG_ 1702 Wischer_vorne_defekt 5000;
BA_REL_ "GenSigTimeoutTime" BU_SG_REL_ Kombi_PAG_PF SG_ 1602 WIV_Verschleissindex 5000;
BA_REL_ "GenSigTimeoutTime" BU_SG_REL_ Kombi_PAG_PF SG_ 1602 WIV_Russindex 5000;
BA_REL_ "GenSigTimeoutTime" BU_SG_REL_ Kombi_PAG_PF SG_ 1602 WIV_t_min 5000;
BA_REL_ "GenSigTimeoutTime" BU_SG_REL_ Kombi_PAG_PF SG_ 1602 WIV_t_max 5000;
BA_REL_ "GenSigTimeoutTime" BU_SG_REL_ Kombi_PAG_PF SG_ 1602 WIV_W_min 5000;
BA_REL_ "GenSigTimeoutTime" BU_SG_REL_ Kombi_PAG_PF SG_ 1602 WIV_W_max 5000;
VAL_ 391 EV_Rekuperationsstufe 0 "keine_Anzeige" 1 "1" 2 "2" 3 "3" 4 "4" 5 "5" ;
VAL_ 391 HV_Bordnetz_aktiv 0 "inaktiv" 1 "aktiv" ;
VAL_ 391 MO_Waehlpos 0 "Init_nicht_unterstuetzt" 1 "reserviert" 2 "P" 3 "R" 4 "N" 5 "D" 6 "B" 7 "Fehler" ;
VAL_ 391 MO_Tankbereitschaft_Status 0 "keine_Aktion_Init" 1 "Tankbereitschaft_wird_hergestellt" 2 "Tankbereitschaft_ist_hergestellt" 3 "Tankbereitschaft_kann_nicht_hergestellt_werden" 4 "Tanksystem_Systemfehler" 5 "Tankklappe_pruefen_schliessen" 6 "Tankvorgang_abgebrochen" ;
VAL_ 391 MO_Tankklappensteuerung 0 "Init_nicht_verbaut" 1 "Tankklappe_soll_entriegeln" 2 "Tankklappe_soll_verriegeln" 3 "keine_Aktion" ;
VAL_ 391 MO_HVEM_Eskalation 0 "keine_Eskalation_HVEM" 1 "Eskalation_HVEM" ;
VAL_ 391 MO_HVEM_MaxLeistung 510 "Init" 511 "Fehler" ;
VAL_ 811 MO_HYB_E_Faktor 0 "null" 1 "plus_1" 2 "plus_2" 3 "plus_3" 4 "plus_4" 5 "plus_5" 6 "plus_6" 7 "plus_7" 8 "minus_8" 9 "minus_7" 10 "minus_6" 11 "minus_5" 12 "minus_4" 13 "minus_3" 14 "minus_2" 15 "minus_1" ;
VAL_ 811 MO_HYB_Drehzahl_VM 65280 "Fehler" ;
VAL_ 811 MO_HYB_LowSpeedModus 0 "LowSpeed_mit_LLDZ" 1 "LowSpeed_ohne_LLDZ" ;
VAL_ 811 MO_FahrPr1_verfuegbar 0 "Fahrprogramm_nicht_verfuegbar" 1 "Fahrprogramm_verfuegbar" ;
VAL_ 811 MO_FahrPr2_verfuegbar 0 "Fahrprogramm_nicht_verfuegbar" 1 "Fahrprogramm_verfuegbar" ;
VAL_ 811 MO_FahrPr3_verfuegbar 0 "Fahrprogramm_nicht_verfuegbar" 1 "Fahrprogramm_verfuegbar" ;
VAL_ 811 MO_FahrPr4_verfuegbar 0 "Fahrprogramm_nicht_verfuegbar" 1 "Fahrprogramm_verfuegbar" ;
VAL_ 811 MO_FahrPr5_verfuegbar 0 "Fahrprogramm_nicht_verfuegbar" 1 "Fahrprogramm_verfuegbar" ;
VAL_ 811 MO_FahrPr6_verfuegbar 0 "Fahrprogramm_nicht_verfuegbar" 1 "Fahrprogramm_verfuegbar" ;
VAL_ 811 MO_FahrPr7_verfuegbar 0 "Fahrprogramm_nicht_verfuegbar" 1 "Fahrprogramm_verfuegbar" ;
VAL_ 305 MO_ePowermeter 0 "Init_keine_Anzeige" 254 "Funktion_deaktiv_Anzeige_ausgegraut" 255 "Fehler_keine_Anzeige" ;
VAL_ 305 MO_W_Reku_normiert_ueberlauf 0 "kein_Ueberlauf" 1 "Rekuperationssignal_min_1_mal_uebergelaufen" ;
VAL_ 305 Ladezustand 255 "Fehler" ;
VAL_ 305 Enrgfluss_State 0 "Init" 1 "no_torques" 2 "pos_tor_EE" 3 "pos_tor_ICE" 4 "pos_tor_ICE_bat_charge" 5 "pos_tor_EE_ICE" 6 "neg_tor_EE_bar_charge" 7 "neg_tor_EE_bat_discharge" 8 "neg_tor_EE" 9 "ICE_charge_bat" 10 "neg_tor_EE_and_ICE" 11 "no_tor_sailing" 12 "no_tor_sailing_and_ICE" 255 "Fehler" ;
VAL_ 305 MO_Powermeter 4093 "Off" ;
VAL_ 931 MO_Mom_ZWR 1022 "Init" 1023 "Fehler" ;
VAL_ 931 MO_Mom_Soll 1022 "Init" 1023 "Fehler" ;
VAL_ 931 MO_Mom_Ist 1022 "Init" 1023 "Fehler" ;
VAL_ 931 MO_Status_Zylabschalt_01 0 "alle Zylinder brennen" 1 "mindestens ein Zylinder wurde abgeschaltet" ;
VAL_ 931 MO_Status_Normalbetrieb_01 0 "kein Normalbetrieb" 1 "Normalbetrieb erreicht" ;
VAL_ 931 MO_StartStopp_Status 0 "System_in_diesem_KL15_Zyklus_nicht_verfuegbar" 1 "System_aktiv_keine_Freigabe_durch_StartStop_Koordinator" 2 "System_aktiv_alle Freigaben_liegen_vor" 3 "System_aktiv_mindestens_eine_Freigabe_fehlt" ;
VAL_ 931 MO_StartStopp_Motorstopp 0 "Motor_Stop_inaktiv" 1 "Motor_Stop_aktiv" ;
VAL_ 931 MO_StartStopp_Wiederstart 0 "Wiederstart_inaktiv" 1 "Wiederstart_aktiv" ;
VAL_ 931 MO_Ext_E_Fahrt_aktiv 0 "Rueckmeldung_E_Taster_aus" 1 "Rueckmeldung_E_Taster_ein" ;
VAL_ 931 MO_Gangposition 0 "Gang_N" 1 "Gang_1" 2 "Gang_2" 3 "Gang_3" 4 "Gang_4" 5 "Gang_5" 6 "Gang_6" 7 "Gang_7" 8 "Gang_8" 12 "Zwischengangstellung" 13 "Gang_R" 14 "Istgang_nicht_definiert" 15 "Fehler" ;
VAL_ 931 MO_StartStopp_Fahrerwunsch 0 "Init" 1 "Stoppverbot_durch_Fahrer" 2 "Stoppfreigabe_durch_Fahrer" 3 "Stoppanforderung_durch_Fahrer" ;
VAL_ 1747 NM_CDR_PCM_Start_1 1 "Zustand Start (<--Sleep)" ;
VAL_ 1747 NM_CDR_PCM_Start_2 1 "Zustand Start (<--Prepare to Sleep)" ;
VAL_ 1747 NM_CDR_PCM_Normal_Mode_1 1 "Zustand Normal Mode (<-- Start)" ;
VAL_ 1747 NM_CDR_PCM_Normal_Mode_2 1 "Zustand Normal Mode (<-- Ready to Sleep)" ;
VAL_ 1747 NM_CDR_PCM_Car_WakeUp 1 "Car Wake Up" ;
VAL_ 1747 NM_CDR_PCM_Per_WakeUp 0 "Funktions-WakeUp" 1 "CAN" ;
VAL_ 1747 NM_CDR_PCM_Fkt_WakeUp 0 "Peripheriewakeup" ;
VAL_ 1747 NM_CDR_PCM_Klemme_15 1 "Klemme 15 ein" ;
VAL_ 1747 NM_CDR_PCM_Diagnose 1 "Diagnose bei Kl 15 aus" ;
VAL_ 1747 NM_CDR_PCM_MindestAktivZeit 1 "aktiv" ;
VAL_ 1747 NMH_CDR_PCM_Signalfehler 1 "Aktiver_Signalfehler_eingetragen" ;
VAL_ 1747 NM_CDR_PCM_TimeOut_Fehler 1 "Aktiver Timeout Fehlerspeichereintrag" ;
VAL_ 1747 NM_CDR_PCM_CAN_Diag_deaktiv 1 "CAN Bus bezogene Eigendiagnose deaktiviert" ;
VAL_ 1747 NM_CDR_PCM_KompSchutz 1 "KS aktiv" ;
VAL_ 1747 NM_CDR_PCM_Mute_Mode 1 "Mute Mode aktiv" ;
VAL_ 1747 NM_CDR_PCM_Transport_Mode 1 "Transportmodus aktiv" ;
VAL_ 1747 NM_CDR_PCM_Abschaltstufe_aktiv 1 "Funktionsabschaltung wegen Abschaltschaltstufe" ;
VAL_ 1747 NM_CDR_PCM_Busfehler 1 "Busfehler" ;
VAL_ 1747 NMH_CDR_PCM_Lokalaktiv 0 "war_nicht_lokal_aktiv" 1 "war_lokal_aktiv" ;
VAL_ 1747 NMH_CDR_PCM_Subsystemaktiv 0 "Subsystem war nicht lokalaktiv" 1 "war Lokalaktiv" ;
VAL_ 1728 NMH_GW_Start_1 1 "Zustand Start (<--Sleep)" ;
VAL_ 1728 NMH_GW_Start_2 1 "Zustand Start (<--Prepare to Sleep)" ;
VAL_ 1728 NMH_GW_Normal_Mode_1 1 "Zustand Normal Mode (<-- Start)" ;
VAL_ 1728 NMH_GW_Normal_Mode_2 1 "Zustand Normal Mode (<-- Ready to Sleep)" ;
VAL_ 1728 NMH_GW_Per_WakeUp 0 "Wenn_FunktionsWakeup" 1 "CAN_Wakeup__Weckendes_CAN_Segment_siehe_NMH_GW_WakeUp_CAN_Bus" 2 "P_WakeUp_Ursache_unbekannt" 3 "Klemme_15HW__falls_vorhanden" 4 "MOST_Wakeup" 5 "LIN_Wakeup" 6 "KL30_Reset" ;
VAL_ 1728 NMH_GW_Fkt_WakeUp 0 "Wenn_Peripherie_Wakeup" 1 "Funktionswakeup_EM" 2 "Car_Wakeup_empfangen" 3 "VNSM_VehicleNetworkStateManager" 4 "Alarm_RTC__Wecken_weil_Weckzeit_abgelaufen" 5 "Wecken_durch_Diagnose" ;
VAL_ 1728 NMH_GW_NM_aktiv_Klemme_15 1 "Klemme 15 EIN" ;
VAL_ 1728 NMH_GW_NM_aktiv_Diagnose 1 "Diagnose bei Kl 15 aus" ;
VAL_ 1728 NMH_GW_NM_aktiv_Start 1 "Zustand 'START' (NM-high)" ;
VAL_ 1728 NMH_GW_NM_aktiv_BDM 1 "BDM-Kommunikation" ;
VAL_ 1728 NMH_GW_NM_aktiv_Warnblinken 1 "Warnblinken aktiv" ;
VAL_ 1728 NMH_GW_NM_aktiv_ESP 1 "ESP aktiv (Wakeup/Sleep-Konzept)" ;
VAL_ 1728 NMH_GW_NM_aktiv_EMP 1 "EMP_aktiv" ;
VAL_ 1728 NMH_GW_Abschaltstufe_3 1 "BEM aufgrund Abschaltstufe 3 aktiv" ;
VAL_ 1728 NMH_GW_SG_Fehlerdauer 1 "BEM aufgrund Steuergeraetefehlerdauer aktiv" ;
VAL_ 1728 NMH_GW_STH_Wakeup 1 "BEM aktiv aufgrund Standheizungswakeup" ;
VAL_ 1728 NMH_GW_NL_Diagnose 0 "keine_Diagnose_aktiv" 1 "Diagnose_war_lokal_aktiv" ;
VAL_ 1728 NM_GW_Signalfehler 1 "Aktiver_Signalfehler_eingetragen" ;
VAL_ 1728 NMH_GW_TimeOut_Fehler 1 "Aktiver Timeout Fehlerspeichereintrag  " ;
VAL_ 1728 NMH_GW_CAN_Diag_deaktiv 1 "CAN Bus bezogene Eigendiagnose deaktiv" ;
VAL_ 1728 NMH_GW_KompSchutz 1 "KS aktiv" ;
VAL_ 1728 NMH_GW_Mute_Mode 1 "MuteMode aktiv" ;
VAL_ 1728 NMH_GW_Transport_Mode 1 "Transportmodus aktiv" ;
VAL_ 1728 NMH_GW_Abschaltstufe_aktiv 1 "Abschaltstufe aktiv" ;
VAL_ 1728 NMH_GW_Eindraht_Fehler 1 "Eindrahtbetrieb erkannt" ;
VAL_ 1728 NMH_GW_ACAN 1 "ACAN aktiv (Wakeup/Sleep-Konzept)" ;
VAL_ 1728 NMH_GW_KombiCAN 1 "KombiCAN aktiv (Wakeup/Sleep-Konzept)" ;
VAL_ 1728 NMH_GW_KomfortCAN 1 "KomfortCAN aktiv (Wakeup/Sleep-Konzept)" ;
VAL_ 1728 NMH_GW_Infotainment 1 "Infotainment aktiv (CAN oder MOST), Wakeup/Sleep-Konzept" ;
VAL_ 1728 NMH_GW_Fahrwerk 1 "BUS_Fahrwerk_aktiv (Wakeup/Sleep-Konzept)" ;
VAL_ 1728 NMH_GW_WakeUp_CAN_Bus 0 "Nicht zutreffend (kein CAN-Wakeup bzw. CarWakeup)" 1 "Antriebs-CAN" 2 "Kombi-CAN" 3 "Komfort-CAN" 4 "Infotainment-CAN (wenn verfuegbar)" 5 "Fahrwerks-CAN" 6 "Diagnose-CAN" ;
VAL_ 1775 NMH_GSM_Start_1 1 "Zustand Start (<--Sleep)" ;
VAL_ 1775 NMH_GSM_Start_2 1 "Zustand Start (<--Prepare to Sleep)" ;
VAL_ 1775 NMH_GSM_Normal_Mode_1 1 "Zustand Normal Mode (<-- Start)" ;
VAL_ 1775 NMH_GSM_Normal_Mode_2 1 "Zustand Normal Mode (<-- Ready to Sleep)" ;
VAL_ 1775 NMH_GSM_Per_WakeUp 0 "wenn_Funktionswakeup" 1 "CAN" 2 "P_Wakeup__Ursache_nicht_bekannt" 3 "Kl_15_Hardware_falls_vorhanden" ;
VAL_ 1775 NMH_GSM_Fkt_WakeUp 0 "wenn Peripheriewakeup" ;
VAL_ 1775 NMH_GSM_Klemme_15 1 "Klemme 15 ein" ;
VAL_ 1775 NMH_GSM_Diagnose 1 "Diagnose bei Kl.15 AUS" ;
VAL_ 1775 NMH_GSM_MindestAktivZeit 1 "aktiv" ;
VAL_ 1775 NMH_GSM_Signalfehler 1 "Aktiver_Signalfehler_eingetragen" ;
VAL_ 1775 NMH_GSM_TimeOut_Fehler 1 "Aktiver Timeout Fehlerspeichereintrag" ;
VAL_ 1775 NMH_GSM_CAN_Diag_deaktiv 1 "CAN Bus bezogene Eigendiagnose deaktiviert " ;
VAL_ 1775 NMH_GSM_KompSchutz 1 "KS aktiv" ;
VAL_ 1775 NMH_GSM_Mute_Mode 1 "Mute Mode aktiv" ;
VAL_ 1775 NMH_GSM_Transport_Mode 1 "Transportmodus aktiv" ;
VAL_ 1775 NMH_GSM_Abschaltstufe_aktiv 1 "Funktionsabschaltung wegen Abschaltschaltstufe" ;
VAL_ 1775 NMH_GSM_Eindraht_Fehler 1 "Eindrahtbetrieb erkannt" ;
VAL_ 1775 NMH_GSM_Lokalaktiv 0 "war_nicht_lokal_aktiv" 1 "war_lokal_aktiv" ;
VAL_ 1775 NMH_GSM_Subsystemaktiv 0 "Subsystem war nicht lokalaktiv" 1 "war Lokalaktiv" ;
VAL_ 1772 NMH_KL_Start_1 1 "Zustand Start (<--Sleep)" ;
VAL_ 1772 NMH_KL_Start_2 1 "Zustand Start (<--Prepare to Sleep)" ;
VAL_ 1772 NMH_KL_Normal_Mode_1 1 "Zustand Normal Mode (<-- Start)" ;
VAL_ 1772 NMH_KL_Normal_Mode_2 1 "Zustand Normal Mode (<-- Ready to Sleep)" ;
VAL_ 1772 NM_KL_Per_WakeUp 0 "wenn Funktionswakeup" 1 "CAN" 2 "P-Wakeup, Ursache nicht bekannt" 3 "Kl. 15 Hardware, falls vorhanden" 4 "Klemme 30 Reset" 5 "LIN (nicht im B8)" 6 "ON_OFF_Taste___Restwaermetaste" 7 "Bedienaktion im SH Betrieb" 8 "Kl 15 HW / STH - Pin (Nachrüstlösung) " ;
VAL_ 1772 NM_KL_Fkt_WakeUp 0 "wenn_Peripheriewakeup" 1 "Standheizung" 2 "Restwaerme" 3 "Solarluefter" ;
VAL_ 1772 NM_KL_Klemme_15 1 "Klemme 15 EIN" ;
VAL_ 1772 NM_KL_Diagnose 1 "Diagnose bei Kl 15 aus" ;
VAL_ 1772 NM_KL_MindestAktivZeit 1 "aktiv" ;
VAL_ 1772 NM_KL_FKT_Nachlauf_Klappen 1 "Nachlauf_aktiv" ;
VAL_ 1772 NM_KL_NL_STH 1 "Nachlauf_STH" ;
VAL_ 1772 NM_KL_NL_Restwaerme 1 "Nachlauf_Restwaerme" ;
VAL_ 1772 NM_KL_NL_LIN 1 "Nachlaufursache_LIN" ;
VAL_ 1772 NM_Klima_Signalfehler 1 "Aktiver_Signalfehler_eingetragen" ;
VAL_ 1772 NM_KL_TimeOut_Fehler 1 "Aktiver Timeout Fehlerspeichereintrag" ;
VAL_ 1772 NM_KL_CAN_Diag_deaktiv 1 "CAN Bus bezogene Eigendiagnose deaktiviert" ;
VAL_ 1772 NM_KL_KompSchutz 1 "KS aktiv" ;
VAL_ 1772 NM_KL_Mute_Mode 1 "MuteMode aktiv" ;
VAL_ 1772 NM_KL_Transport_Mode 1 "Transportmodus aktiv" ;
VAL_ 1772 NM_KL_Abschaltstufe_aktiv 1 "Abschaltstufe aktiv" ;
VAL_ 1772 NM_KL_Eindraht_Fehler 1 "Eindrahtbetrieb erkannt" ;
VAL_ 1772 NMH_Klima_Lokalaktiv 0 "war_nicht_lokal_aktiv" 1 "war_lokal_aktiv" ;
VAL_ 1772 NMH_Klima_Subsystemaktiv 0 "Subsystem war nicht lokalaktiv" 1 "war Lokalaktiv" ;
VAL_ 1735 NMH_KBI_Start_1 1 "Zustand Start (<--Sleep)" ;
VAL_ 1735 NMH_KBI_Start_2 1 "Zustand Start (<--Prepare to Sleep)" ;
VAL_ 1735 NMH_KBI_Normal_Mode_1 1 "Zustand Normal Mode (<-- Start)" ;
VAL_ 1735 NMH_KBI_Normal_Mode_2 1 "Zustand Normal Mode (<-- Ready to Sleep)" ;
VAL_ 1735 NMH_KBI_Per_WakeUp 0 "wenn Funktionswakeup" 1 "CAN-Wakeup" 2 "P-Wakeup, Ursache nicht bekannt" 3 "KL 15 HW (falls vorhanden)" 4 "Check-Taste" 5 "Kl.30-Reset" ;
VAL_ 1735 NMH_KBI_Fkt_WakeUp 0 "wenn Peripheriewakeup" 1 "Ablauf des Standheizungstimers" ;
VAL_ 1735 NMH_KBI_NM_aktiv_Klemme_15 1 "Klemme 15 EIN" ;
VAL_ 1735 NMH_KBI_NM_aktiv_Diagnose 1 "Diagnose bei Kl 15 aus" ;
VAL_ 1735 NMH_KBI_NM_aktiv_Start 1 "Zustand 'START' (NM-high)" ;
VAL_ 1735 NMH_KBI_NM_aktiv_Tankinhalt 1 "Referenzwertbildung Tankinhalt aktiv" ;
VAL_ 1735 NMH_KBI_NM_aktiv_Display 1 "Display aktiv " ;
VAL_ 1735 NMH_KBI_kein_NL 1 "kein lokaler Nachlauf" ;
VAL_ 1735 NMH_KBI_NL_Sync_Funkuhr 1 "Synchronisation Funkuhr" ;
VAL_ 1735 NM_Kombi_NL_Warnblinken 0 "inaktiv" 1 "aktiv" ;
VAL_ 1735 NMH_KBI_NL_KL15 1 "Nachlauf Kl.15 AUS aktiv" ;
VAL_ 1735 NMH_KBI_Signalfehler 1 "Aktiver_Signalfehler_eingetragen" ;
VAL_ 1735 NMH_KBI_TimeOut_Fehler 1 "Aktiver Timeout Fehlerspeichereintrag  " ;
VAL_ 1735 NMH_KBI_CAN_Diag_deaktiv 1 "CAN-Diagnose deaktiv" ;
VAL_ 1735 NMH_KBI_KompSchutz 1 "KS aktiv" ;
VAL_ 1735 NMH_KBI_Mute_Mode 1 "MuteMode aktiv" ;
VAL_ 1735 NMH_KBI_Transport_Mode 1 "Transportmodus aktiv" ;
VAL_ 1735 NMH_KBI_Abschaltstufe_aktiv 1 "Abschaltstufe aktiv" ;
VAL_ 1735 NMH_KBI_Eindraht_Fehler 1 "Eindrahtbetrieb erkannt" ;
VAL_ 1735 NMH_Kombi_Lokalaktiv 0 "war nicht Lokalaktiv" 1 "war Lokalaktiv" ;
VAL_ 1735 NMH_Kombi_Subsystemaktiv 0 "Subsystem war nicht lokalaktiv" 1 "war Lokalaktiv" ;
VAL_ 1750 NMH_Miko_Start_1 1 "Zustand Start (<--Sleep)" ;
VAL_ 1750 NMH_Miko_Start_2 1 "Zustand Start (<--Prepare to Sleep)" ;
VAL_ 1750 NMH_Miko_Normal_Mode_1 1 "Zustand Normal Mode (<-- Start)" ;
VAL_ 1750 NMH_Miko_Normal_Mode_2 1 "Zustand Normal Mode (<-- Ready to Sleep)" ;
VAL_ 1750 NMH_Miko_Per_WakeUp 0 "wenn Funktionswakeup" 1 "CAN" 2 "P-Wakeup, Ursache nicht bekannt" 3 "Kl. 15 Hardware, falls vorhanden" 4 "Innentaster_bet" 5 "Kessy_Taster_bet" 6 "Klemme_30_Reset" 8 "Sensoren_SBC__Hall_1__man_Beweg" 9 "Sensoren_SBC__Hall_2__man_Beweg" ;
VAL_ 1750 NMH_Miko_Fkt_WakeUp 0 "wenn Peripheriewakeup" ;
VAL_ 1750 NMH_Miko_Signalfehler 1 "Aktiver_Signalfehler_eingetragen" ;
VAL_ 1750 NMH_Miko_TimeOut_Fehler 1 "Aktiver Timeout Fehlerspeichereintrag  " ;
VAL_ 1774 NM_RDK_Start_1 1 "Zustand Start (<--Sleep)" ;
VAL_ 1774 NM_RDK_Start_2 1 "Zustand Start (<--Prepare to Sleep)" ;
VAL_ 1774 NM_RDK_Normal_Mode_1 1 "Zustand Normal Mode (<-- Start)" ;
VAL_ 1774 NM_RDK_Normal_Mode_2 1 "Zustand Normal Mode (<-- Start)" ;
VAL_ 1774 NM_RDK_Per_WakeUp 0 "wenn Funktionswakeup" 1 "CAN" 2 "P-Wakeup, Ursache nicht bekannt" 3 "Kl. 15 Hardware, falls vorhanden" ;
VAL_ 1774 NM_RDK_Fkt_WakeUp 0 "wenn Peripheriewakeup" ;
VAL_ 1774 NM_RDK_Klemme_15 1 "Klemme 15 EIN" ;
VAL_ 1774 NM_RDK_Diagnose 1 "Diagnose bei Kl 15 aus" ;
VAL_ 1774 NM_RDK_MindestAktivZeit 1 "aktiv" ;
VAL_ 1774 NMH_RDK_NL_Radmanagement 0 "kein_Nachlauf" 1 "Radmanagement_aktiv" ;
VAL_ 1774 NM_RDK_Signalfehler 1 "Aktiver_Signalfehler_eingetragen" ;
VAL_ 1774 NM_RDK_TimeOut_Fehler 1 "Aktiver Timeout Fehlerspeichereintrag" ;
VAL_ 1774 NM_RDK_CAN_Diag_deaktiv 1 "CAN Bus bezogene Eigendiagnose deaktiviert" ;
VAL_ 1774 NM_RDK_KompSchutz 1 "KS aktiv" ;
VAL_ 1774 NM_RDK_Mute_Mode 1 "MuteMode aktiv" ;
VAL_ 1774 NM_RDK_Transport_Mode 1 "Transportmodus aktiv" ;
VAL_ 1774 NM_RDK_Abschaltstufe_aktiv 1 "Abschaltschaltstufe aktiv" ;
VAL_ 1774 NM_RDK_Eindraht_Fehler 1 "Eindrahtbetrieb erkannt" ;
VAL_ 1774 NMH_RDK_Lokalaktiv 0 "war_nicht_lokal_aktiv" 1 "war_lokal_aktiv" ;
VAL_ 1774 NMH_RDK_Subsystemaktiv 0 "Subsystem war nicht lokalaktiv" 1 "war Lokalaktiv" ;
VAL_ 1630 OBD_TG_F_Status_1 0 "kein Fehler / Init / nicht verbaut" 1 "KS- (Kurzschluss nach minus)" 2 "KS+ (Kurzschluss nach plus)" 3 "OC (Leitungsunterbrechung)" 4 "OOR+ (Signal zu gross)" 5 "OOR- (Signal zu klein)" 6 "RC+ (Signal unplausibel zu gross)" 7 "RC- (Signal unplausibel zu klein)" 8 "KS+/OC (Kurzschluss nach plus/Unterbrechung)" 9 "KS-/OC  (Kurzschluss nach minus/Unterbrechung)" 10 "KS-/KS+  (Kurzschluss nach minus/plus)" 11 "KS-/KS+/OC (Kurzschluss nach minus/plus/Unterbrechung)" 14 "frei" 15 "frei" ;
VAL_ 1630 OBD_TG_F_Status_2 0 "kein Fehler / Init / nicht verbaut" 1 "KS- (Kurzschluss nach minus)" 2 "KS+ (Kurzschluss nach plus)" 3 "OC (Leitungsunterbrechung)" 4 "OOR+ (Signal zu gross)" 5 "OOR- (Signal zu klein)" 6 "RC+ (Signal unplausibel zu gross)" 7 "RC- (Signal unplausibel zu klein)" 8 "KS+/OC (Kurzschluss nach plus/Unterbrechung)" 9 "KS-/OC  (Kurzschluss nach minus/Unterbrechung)" 10 "KS-/KS+  (Kurzschluss nach minus/plus)" 11 "KS-/KS+/OC (Kurzschluss nach minus/plus/Unterbrechung)" 14 "frei" 15 "frei" ;
VAL_ 1630 OBD_TG_F_Status_3 0 "kein Fehler / Init / nicht verbaut" 1 "KS- (Kurzschluss nach minus)" 2 "KS+ (Kurzschluss nach plus)" 3 "OC (Leitungsunterbrechung)" 4 "OOR+ (Signal zu gross)" 5 "OOR- (Signal zu klein)" 6 "RC+ (Signal unplausibel zu gross)" 7 "RC- (Signal unplausibel zu klein)" 8 "KS+/OC (Kurzschluss nach plus/Unterbrechung)" 9 "KS-/OC  (Kurzschluss nach minus/Unterbrechung)" 10 "KS-/KS+  (Kurzschluss nach minus/plus)" 11 "KS-/KS+/OC (Kurzschluss nach minus/plus/Unterbrechung)" 14 "frei" 15 "frei" ;
VAL_ 1630 OBD_TG_F_Status_4 0 "kein Fehler / Init / nicht verbaut" 1 "KS- (Kurzschluss nach minus)" 2 "KS+ (Kurzschluss nach plus)" 3 "OC (Leitungsunterbrechung)" 4 "OOR+ (Signal zu gross)" 5 "OOR- (Signal zu klein)" 6 "RC+ (Signal unplausibel zu gross)" 7 "RC- (Signal unplausibel zu klein)" 8 "KS+/OC (Kurzschluss nach plus/Unterbrechung)" 9 "KS-/OC  (Kurzschluss nach minus/Unterbrechung)" 10 "KS-/KS+  (Kurzschluss nach minus/plus)" 11 "KS-/KS+/OC (Kurzschluss nach minus/plus/Unterbrechung)" 14 "frei" 15 "frei" ;
VAL_ 1337 PCM_HMI_mode 0 "Parkbox" 1 "parallel_Strasse" 2 "keine_Guidlines" 3 "nicht_bekannt" ;
VAL_ 1337 PCM_RFK_manuell 0 "keine Aenderung" 1 "Aktiviert" 2 "Deaktiviert" 3 "reserviert" ;
VAL_ 1337 PCM_Rundenfarbe 0 "grün" 1 "gelb" 2 "rot" ;
VAL_ 1337 PCM_Limit_Einheit 0 "km/h" 1 "mls/h" ;
VAL_ 1337 PCM_Kompass 510 "Init, kein gültiger Kompass Wert liegt vor" 511 "Fehler" ;
VAL_ 1337 PCM_Elev_Einheit 0 "meter" 1 "feet" ;
VAL_ 1337 PCM_HMI_Mode_TopView 0 "keine_Anzeige" 1 "RearView_ohne_Hilfslinine" 2 "RearView_mit_dyn_Hilfslinien" 3 "RearView_mit_stat_Hilfslinien" 4 "FrontView_ohne_Hilfslinie" 5 "FrontView_mit_dyn_Hilfslinien" 6 "RealView_Fullscreen" 7 "RealView_Fullscreen_mit_dyn_Hilfslinien" 8 "RealView_Front_Splitscreen" 9 "RealView_Front_Splitscreen_mit_Hilfslinine" 10 "RealView_Rear_Splitscreen" 11 "RealView_Rear_Splitscreen_mit_Hilfslinine" 12 "TopView_PDC_Anzeige__durch_HU" 13 "TopView_Front_Splitscreen" 14 "TopView_Front_Splitscreen_mit_Hilfslinine" 15 "TopView_Rear_Splitscreen" 16 "TopView_Rear_Splitscreen_mit_Hilfslinine" 17 "CornerView_Front_Blick_re_li_vorn" 18 "CornerView_Heck_Blick_re_li_hinten" 19 "SideView_Fahrzeugseite_re_li" 20 "SideView_Front_Vorderachse_re_li" 21 "SideView_Heck_Hinterachse_re_li" 22 "JapanView" ;
VAL_ 1337 PCM_Entfernung_Kurve 0 "keine_Anzeige" ;
VAL_ 1530 GPS_elev 8190 "Hoehe_ungueltig" 8191 "Hoehe_und_Koordinaten_ungueltig" ;
VAL_ 1707 PCM_Zeitzone 0 "Initialwert__entspricht_0_h" 31 "Zeitzone_nicht_verfuegbar" ;
VAL_ 1707 PCM_Zeitzone_Vorzeichen 0 "positiv" 1 "negativ" ;
VAL_ 1707 PCM_Sommerzeit 0 "Sommerzeit" 1 "Winterzeit" ;
VAL_ 1707 PCM_Reset_Trip_1 0 "kein Reset" 1 "Reset" ;
VAL_ 1707 PCM_Reset_Trip_2 0 "kein Reset" 1 "Reset" ;
VAL_ 1707 HU_Fotosensor 0 "Sensor unbeleuchtet" 510 "Initialwert" 511 "Fehler" ;
VAL_ 1707 HU_SVB_AMP 0 "SG nicht verbaut" 1 "SG verbaut" ;
VAL_ 1707 PCM_SVB_TV 0 "SG nicht verbaut" 1 "SG verbaut" ;
VAL_ 1707 PCM_KD_Fehler_AMP 0 "kein Fehler gespeichert" 1 "mind. 1 Fehler gespeichert" ;
VAL_ 1707 PCM_KD_Fehler_TV 0 "kein Fehler gespeichert" 1 "mind. 1 Fehler gespeichert" ;
VAL_ 1707 HU_PCMCDR 0 "CDR verbaut" 1 "PCM verbaut" ;
VAL_ 1707 HU_Topview_on_Anf 0 "keine Anforderung" 1 "Anforderung aktiv" ;
VAL_ 1339 QUER_Charisma_FahrPr 0 "nicht_belegt" 1 "Programm_1" 2 "Programm_2" 3 "Programm_3" 4 "Programm_4" 5 "Programm_5" 6 "Programm_6" 7 "Programm_7" ;
VAL_ 1339 QUER_Charisma_Status 0 "Init" 1 "verfuegbar" 2 "nicht_verfuegbar" 3 "asynchron_durch_Fahrerwunsch" ;
VAL_ 1339 QUER_Charisma_Umschaltung 0 "Idle" 1 "Erkennung_Umschaltaufforderung" 2 "Steuerbotschaft_nicht_definiert" 3 "Umschaltung_verzoegert" ;
VAL_ 1339 QS_St_Begrenzungsmoment 0 "kein_Eingriff" 1 "langsamer_Eingriff_Luftpfad" 2 "schneller_Eingriff_Zuendwinkel" 3 "nicht_belegt" ;
VAL_ 1339 QS_Symbol_Rear_Lock 0 "aus" 1 "ein" ;
VAL_ 1339 QS_Warntexte 0 "keine Meldung" 1 "Meldung_1" 2 "Meldung_2" 3 "Meldung_3" ;
VAL_ 1611 RDK_System_Off 0 "System_eingeschaltet" 1 "System_ausgeschaltet" ;
VAL_ 1611 RDK_Warnungen 0 "keine Anzeige" 1 "RD prüfen (P1-rot)" 2 "RD_VL (P1-rot)" 3 "RD_VR (P1-rot)" 4 "RD_HL (P1-rot)" 5 "RD_HR (P1-rot)" 6 "RD_RR (P2-gelb)" 7 "RD prüfen (P2-gelb)" 8 "reserviert" 9 "RD Systemstörung (P2-gelb)" 10 "RD_VL_(P2-gelb)" 11 "RD_VR_(P2-gelb)" 12 "RD_HL_(P2-gelb)" 13 "RD_HR_(P2-gelb)" 14 "Zu_schnell_fuer_Winterreifen" 15 "Zu_schnell_fuer_Reifendruck" ;
VAL_ 1611 RDK_FMVSS138_Lampe 0 "RDK_WaLa_inaktiv" 1 "RDK_WaLa_aktiv" ;
VAL_ 1611 RDK_Druckwarnung_RdW 0 "rote Lampe aus" 1 "rote Lampe ein" ;
VAL_ 1611 RDK_FMVSS138_MIL 0 "keine_Stoerungsanzeige" 1 "Stoerungsanzeige" ;
VAL_ 1611 RDK_LF_aktiv 0 "Inaktiv" 1 "Aktiv" ;
VAL_ 1611 RDK_KD_Fehler 0 "kein_KD_Fehler" 1 "KD_Fehler" ;
VAL_ 1652 RDK_Warnung_1 0 "Keine Warnung" 1 "Rote Warnung" ;
VAL_ 1652 RDK_Warnung_2 0 "Keine Warnung" 1 "Gelbe Warnung" ;
VAL_ 1652 RDK_angelernt 0 "nicht_angelernt" 1 "angelernt" ;
VAL_ 1652 RDK_Text_1 0 "inaktiv" 1 "aktiv" ;
VAL_ 1652 RDK_Text_2 0 "inaktiv" 1 "aktiv" ;
VAL_ 1652 RDK_Text_3 0 "inaktiv" 1 "aktiv" ;
VAL_ 1652 RDK_Text_4 0 "inaktiv" 1 "aktiv" ;
VAL_ 1652 RDK_Text_5 0 "inaktiv" 1 "aktiv" ;
VAL_ 1652 RDK_Text_6 0 "inaktiv" 1 "aktiv" ;
VAL_ 1652 RDK_W_3_Reifendr_erh 0 "keine Ausgabe" 1 "Ausgabe" ;
VAL_ 1525 RW_RWDS_Lastprofil 2046 "Init" 2047 "Fehler" ;
VAL_ 1525 RW_Gesamt_Reichweite 2045 "nicht_verbaut" 2046 "Init" 2047 "Fehler" ;
VAL_ 1525 RW_Prim_Reichweitenverbrauch 2047 "Init" ;
VAL_ 1525 RW_Prim_Reichweitenv_Einheit 0 "Liter_pro_100km" 1 "kWh_pro_100km" 2 "Kg_pro_100km" 3 "nicht_verbaut" ;
VAL_ 1525 RW_Primaer_Reichweite 2045 "nicht_verbaut" 2046 "Init" 2047 "Fehler" ;
VAL_ 1527 RW_Sekundaer_Reichweite 2045 "nicht_verbaut" 2046 "Init" 2047 "Fehler" ;
VAL_ 1527 RW_Sek_Reichweitenv_Einheit 0 "Liter_pro_100km" 1 "kWh_pro_100km" 2 "Kg_pro_100km" 3 "nicht_verbaut" ;
VAL_ 1527 RW_Sek_Reichweitenverbrauch 2047 "Init" ;
VAL_ 1504 MD1_Lage 0 "Ausstelllage" 1 "Schiebelage" ;
VAL_ 1504 MD3_Lage 0 "Ausstelllage" 1 "Schiebelage" ;
VAL_ 1504 MRollo_Lage 0 "Ausstelllage" 1 "Schiebelage" ;
VAL_ 1413 SI_Int_CAN_gespiegelt 0 "interner CAN getrennt" 1 "interner CAN gespiegelt" ;
VAL_ 1413 SI_CAN_Komfort_Sleep 0 "keine_Busruhe" 1 "Busruhe" ;
VAL_ 1413 SI_CAN_Dashboard_Sleep 0 "keine_Busruhe" 1 "Busruhe" ;
VAL_ 1413 SI_CAN_Antrieb_Sleep 0 "keine_Busruhe" 1 "Busruhe" ;
VAL_ 1413 SI_Infotainment_Sleep 0 "keine_Busruhe" 1 "Busruhe" ;
VAL_ 1413 SI_CAN_Extended_Sleep 0 "keine_Busruhe" 1 "Busruhe" ;
VAL_ 1413 SI_Fahrwerk_Sleep 0 "keine_Busruhe" 1 "Busruhe" ;
VAL_ 1413 SI_Diagnose_Aktiv 0 "inaktiv" 1 "aktiv" ;
VAL_ 1413 SI_QRS_Mode 0 "QRS_Messmodus_nicht_aktiv" 1 "QRS_Messmodus_aktiv" ;
VAL_ 1413 SI_T_Mode 0 "Transportmodus_nicht_aktiv" 1 "Transportmodus_aktiv" ;
VAL_ 1413 SI_NWDF 0 "Ueberwachung_nicht_freigegeben" 1 "Ueberwachung_freigegeben" ;
VAL_ 1413 SI_NWDF_gueltig 0 "NWDF_wird_nicht_unterstuetzt" 1 "NWDF_wird_unterstuetzt" ;
VAL_ 1413 SI_Sammelfehler 0 "kein_Sammelfehler" 1 "Sammelfehler" ;
VAL_ 1413 GW_KD_Fehler 0 "kein_KD_Fehler" 1 "KD_Fehler" ;
VAL_ 1413 SI_T_Schutz 0 "Transportschutz_nicht_aktiv" 1 "Transportschutz_aktiv" ;
VAL_ 1413 SI_MOST_Status 0 "MOST_sleep_(Licht_AUS)" 1 "MOST_aktiv_(Kommunikation_moeglich)" ;
VAL_ 1413 SI_Sammel_SG_Fehler 61 "Reserviert" 62 "Overflow" 63 "ungueltig" ;
VAL_ 1413 SI_MO_WU 0 "kein Wakeup angefordert" 1 "Wakeup MED9 angefordert" ;
VAL_ 786 FAS_Wunschgeschw 1022 "keine Anzeige" 1023 "nicht definiert" ;
VAL_ 786 FAS_Status_Prim_Anz 0 "Symbol nicht beleuchtet" 1 "Farbe 1 (typisch 'grün')" 2 "Farbe 2 (typisch 'rot')" 3 "Farbe 3 (typisch 'gelb')" ;
VAL_ 786 FAS_Texte_Primaeranz 0 "keine Anzeige " 1 "ACC nicht verfuegbar !" 2 "Auto_Auto_ _ _" 3 "Auto_ _Auto_ _" 4 "Auto_ _ _Auto_" 5 "Auto_ _ _ _Auto" 6 "Auto_Auto_ _ _ Gong (durchgestrichen)" 7 "Auto_ _Auto_ _ Gong (durchgestrichen)" 8 "Auto_ _ _Auto_ Gong (durchgestrichen)" 9 "Auto_ _ _ _Auto Gong (durchgestrichen)" 10 "ACC bereit" 11 "keine Abstandsregelung" 12 "ACC Sensor Sicht !" 13 "ACC nicht verfuegbar" 14 "o  o  o" 15 "Hochschalten" 16 "ESP Eingriff" 17 "Herunterschalten" 18 "Parkbremse !" 19 "Geschwindigkeitsgrenze" 20 "Waehlhebelposition !" 21 "VDA ACC-Symbol YYY km/h / mph" 22 "Tempolimit XXX km/h / mph" 23 "Kurve XXX km/h / mph" 24 "ACC Abschaltung" 25 "Symbol 'Eieruhr'" 26 "!" 27 "--- km/h / mph" 28 "XXX km/h / mph (Schriftart 2)" 29 "Lenkradwinkel" 30 "Anfahren bestaetigen" 31 "Fahrzeug verloren" 32 "Im Stand nicht moeglich" 33 "Ungueltiger Anfahrbefehl" 34 "Tuer offen !" 35 "Fahrer Gurtschloss offen !" 36 "Schalthebelposition !" 37 "Drehzahl !" 38 "Kurvenassistent aus" 39 "Tempolimit aus" 40 "Abbiegeassistent" 41 "Ortsanfang XXX km/h / mph" 42 "Ortsende XXX km/h / mph" 43 "Tempolimit Ende XXX km/h / mph" 44 "HDC aktiv" 45 "braking guard Bremsruck" 46 "braking guard aus " 47 "braking guard aus" 48 "Uebernehmen !" 49 "Steigung zu gross" 50 "Stehendes Objekt voraus" 51 "SET / 'GRA Symbol'___xxx km/h / mph" 52 "SET / 'GRA Symbol' xxx km/h / mph" 53 "ACC aus" 54 "ACC startet" 55 "ACC reinigen" 56 "ACC Fehler" 57 "ACC haelt an !" 58 "Bremse betaetigen !" 59 "Kupplung betaetigt" 60 "LIM AUS" 61 "LIM AKTIV " 62 "LIM PASSIV" 63 "LIM FEHLER" 64 "Bremse ueberhitzt !" 65 "Bremse haelt !" 66 "ESP PASSIV !" ;
VAL_ 786 FAS_Status_Anzeige 0 "ACC/GRA Hauptschalter aus" 1 "ACC in Init (nicht bei GRA)" 2 "ACC/GRA passiv" 3 "ACCGRA aktiv" 4 "ACC/GRA im Hintergrund (übertreten)" 5 "frei" 6 "ACC reversibel aus (nicht bei GRA)" 7 "ACC/GRA irreversibel aus" ;
VAL_ 1718 UH_Typ 0 "undefiniert" 1 "Quarzuhr" 2 "DCF" 3 "GPS" ;
VAL_ 1718 UH_DLS 0 "Winterzeit" 1 "Sommerzeit" ;
VAL_ 1718 UH_Monat 0 "Init" 14 "reserviert" ;
VAL_ 1718 UH_Tag 0 "Init" ;
VAL_ 915 WBA_Senderkennung 0 "Getriebe" 1 "Motor" ;
VAL_ 915 WBA_Lampe_Shift_Lock 0 "SL_Lampe_aus" 1 "SL_Lampe_ein" ;
VAL_ 915 WBA_Schaltempf_verfbar 0 "nicht verfügbar" 1 "verfügbar" ;
VAL_ 915 WBA_Effizienzmodus 0 "nicht_im_Effizienz_Modus" 1 "Effizienz_Modus" ;
VAL_ 915 WBA_Blinken 0 "kein_WBA_Blinken" 1 "WBA_Blinken" ;
VAL_ 915 WBA_Getriebevariante 1 "Automat PRND" 2 "tbd." 3 "tbd." 4 "Vorhalt für ASG (Selespeed)" 5 "tbd." 6 "Automat PRNDS" 7 "tbd." 8 "2x3 shift_by_wire" 9 "tbd." 10 "tbd." 11 "5 Gang Automat Tiptronic" 12 "6 Gang Automat Tiptronic" 13 "7 Gang Automat Tiptronic" 14 "8 Gang Automat Tiptronic" 15 "9 Gang Automat Tiptronic" ;
VAL_ 915 WBA_GE_Warnung 0 "keine Anzeige" 1 "Weiterfahrt möglich (+ gelbes Getriebefehlersymbol)" 2 "Weiterfahrt nur eingeschränkt möglich (+ gelbes Getriebefehlersymbol)" 3 "nur DL-Getriebe: Weiterfahrt nur eingeschränkt möglich. Kein R-Gang" 4 "Getriebefehler, Weiterfahrt nur in D moeglich, P bei Motor aus" 5 "Wegrollgefahr! P nicht möglich" 6 "Kupplung ueberhitzt, Fahrzeug Stopp (+ gelbes Getriebefehlersymbol)" 7 "Kupplung ueberhitzt, Fahrzeug Stopp (+ rotes Getriebefehlersymbol)" ;
VAL_ 915 WBA_Istgang 0 "kein Gang eingelegt" 1 "1.Gang" 2 "2.Gang" 3 "3.Gang" 4 "4.Gang" 5 "5.Gang" 6 "6.Gang" ;
VAL_ 915 WBA_eing_Gang 0 "kein Gang eingelegt / kein Gang empfohlen" 1 "Init" 2 "1.Gang" 3 "2.Gang" 4 "3.Gang" 5 "4.Gang" 6 "5.Gang" 7 "6.Gang" 8 "7.Gang" 9 "8.Gang" 10 "9.Gang" ;
VAL_ 915 WBA_Sollgang 0 "keine Empfehlung" 1 "1.Gang" 2 "2.Gang" 3 "3.Gang" 4 "4.Gang" 5 "5.Gang" 6 "6.Gang" ;
VAL_ 915 WBA_GE_Texte 0 "keine_Anzeige" 1 "zum_Einlegen_einer_Fahrstufe_Fussbremse_betaetigen__ShiftLock_Information" 2 "zum_Einlegen_von_R_N_D_Fussbremse_betaetigen_und_Motor_starten" 3 "Wegrollgefahr_bitte_P_einlegen" 4 "Achtung_Zeitueberschreitung_P_wird_eingelegt" 5 "Wiederanmeldeprozedur_Bremse_betaetigen" 6 "P_nur_im_Stillstand_moeglich" 7 "Rennstart_aktiv" ;
VAL_ 915 WBA_Schaltschema_Aktiv 0 "keine_Anzeige" 1 "Schaltschema_anzeigen" ;
VAL_ 915 WH_Warnung 0 "keine_Anzeige" 1 "Waehlhebelfehler_Fahrstufenwechsel_moeglich_(gelbes_Getriebesymbol)" ;
VAL_ 915 WBA_GE_Zusatzwarnungen 0 "keine_Anzeige" 1 "Getriebeueberhitzung_Warnstufe_I" 2 "Getriebeueberhitzung_Warnstufe_II" 3 "Getriebefehler_Bitte_anhalten_und_P_einlegen" ;
VAL_ 915 GE_Tipschaltempf_verfuegbar 0 "nicht_verfuegbar" 1 "verfuegbar" ;
VAL_ 915 GE_Sollgang 0 "keine_Empfehlung" 1 "Gang_1" 2 "Gang_2" 3 "Gang_3" 4 "Gang_4" 5 "Gang_5" 6 "Gang_6" 7 "Gang_7" 8 "Gang_8" 9 "Gang_9" ;
VAL_ 1702 Wischer_vorne_aktiv 1 "Wischer vorne läuft" ;
VAL_ 1702 Waschen_vorne_aktiv 1 "Waschen aktiv" ;
VAL_ 1702 Wischer_vorne_Normal 1 "Wischer Front normal aktiv" ;
VAL_ 1702 Wischer_vorne_Schnell 1 "Wischer vorne schnell aktiv" ;
VAL_ 1702 Wischer_vorne_Parklage 1 "Wischer Front in Parklage" ;
VAL_ 1702 WWSs_01_alt 0 "aktuell" 1 "veraltet" ;
VAL_ 1702 Wischer_vorne_defekt 1 "Wischer vorne defekt" ;
VAL_ 1702 Wischer_vorne_blockiert 1 "Wischer vorne blockiert" ;
VAL_ 1702 Wischer1_Wischgeschwindigkeit 0 "0 U/min" 62 "Init" 63 "Fehler" ;
VAL_ 1702 BCM1_SRA_aktiv 0 "nicht aktiv" 1 "aktiv" ;
VAL_ 1602 WIV_Verschleissindex 65535 "Fehler" ;
VAL_ 1602 WIV_Russindex 65535 "Fehler" ;
